VERSION ""

NS_ :

BS_:

BU_: ECS Dummy CGW MFC SPAS ESC BSD SCC SAS MDPS HUD CLU

BO_ 208 EMS_02_10ms: 32 CGW
 SG_ ENG_AccelPdlVal : 16|8@1+ (0.3906,0) [0|0] "%"  Dummy
 SG_ ENG_TqStndVal : 24|6@1+ (10,0) [0|0] "Nm"  Dummy
 SG_ ENG_BrkSwSta : 30|2@1+ (1,0) [0|0] ""  Dummy
 SG_ ENG_TransmsnTyp : 38|6@1+ (1,0) [0|0] ""  Dummy
 SG_ ENG_EngClntTempVal : 44|8@1+ (0.75,-48) [0|0] "℃"  Dummy
 SG_ ENG_AccActSta : 69|2@1+ (1,0) [0|0] ""  Dummy
 SG_ ENG_CltchOpSta : 71|2@1+ (1,0) [0|0] ""  Dummy
 SG_ ENG_EngTyp : 73|4@1+ (1,0) [0|0] ""  Dummy
 SG_ ENG_ThrPosVal : 79|8@1+ (0.469484,-15.0235) [0|0] "%"  Dummy
 SG_ ENG_EngDsplceTyp : 87|8@1+ (0.1,0) [0|0] "liter"  Dummy
 SG_ ENG_MinIndTqVal : 95|8@1+ (0.390625,0) [0|0] "%"  Dummy
 SG_ ENG_TrgtTqVal : 103|8@1+ (0.390625,0) [0|0] "%"  Dummy
 SG_ ENG_GlowLmpSta : 111|2@1+ (1,0) [0|0] ""  Dummy
 SG_ ACC_CrsMainSwLmpSta : 113|2@1+ (1,0) [0|0] ""  Dummy
 SG_ ACC_CrsSetSwLmpSta : 115|2@1+ (1,0) [0|0] ""  Dummy
 SG_ ENG_PreFuelCutInSta : 117|2@1+ (1,0) [0|0] ""  Dummy
 SG_ ENG_EngSta : 119|3@1+ (1,0) [0|0] ""  Dummy
 SG_ ENG_SoakTimeErrSta : 122|2@1+ (1,0) [0|0] ""  Dummy
 SG_ ENG_SoakTimeVal : 124|8@1+ (1,0) [0|0] "Min"  Dummy
 SG_ ENG_MaxIndTqVal : 132|8@1+ (0.390625,0) [0|0] "%"  Dummy
 SG_ ENG_SprkTimeVal : 140|8@1+ (0.375,-35.625) [0|0] "˚"  Dummy
 SG_ ENG_AppAccelPdlSta : 148|2@1+ (1,0) [0|0] ""  Dummy
 SG_ ENG_BstPrsrVal : 172|12@1+ (1.322,0) [0|0] "hPa"  Dummy
 SG_ ENG_EngOilTempVal : 184|8@1+ (0.75,-40) [0|0] "℃"  Dummy
 SG_ ENG_DpfWrngSta : 192|2@1+ (1,0) [0|0] ""  Dummy
 SG_ ENG_BattWrngLmpSta : 194|2@1+ (1,0) [0|0] ""  Dummy
 SG_ ENG_OilPrsrWrngLmpSta : 204|2@1+ (1,0) [0|0] ""  Dummy

BO_ 48 EMS_03_10ms: 32 CGW
 SG_ DCT_AccelPdlVal : 16|8@1+ (0.3906,0) [0|0] "%"  Dummy
 SG_ DCT_EngSpdErrSta : 30|2@1+ (1,0) [0|0] ""  Dummy
 SG_ DCT_EngSpdVal : 34|16@1+ (0.25,0) [0|0] "rpm"  Dummy
 SG_ DCT_CrctEngTqVal : 50|8@1+ (0.390625,0) [0|0] "%"  Dummy

BO_ 538 EMS_04_100ms: 32 CGW
 SG_ BAT_SocVal : 32|8@1+ (1,0) [0|0] "%"  Dummy

BO_ 528 EMS_05_100ms: 32 CGW
 SG_ ENG_ImmoLmpSta : 16|2@1+ (1,0) [0|0] ""  Dummy
 SG_ ENG_MilSta : 18|2@1+ (1,0) [0|0] ""  Dummy
 SG_ ENG_AtmsphPrsrVal : 22|5@1+ (10.7316,458.98) [0|0] "mmHg"  Dummy
 SG_ ENG_BattVoltVal : 35|8@1+ (0.101563,0) [0|0] "V"  Dummy
 SG_ SCC_SafetyFunctSta : 65|2@1+ (1,0) [0|0] ""  Dummy
 SG_ SCC_InAirTempVal : 67|8@1+ (0.75,-48) [0|0] "℃"  Dummy
 SG_ SCR_LvlWrngLmpSta : 116|2@1+ (1,0) [0|0] ""  Dummy
 SG_ SCR_LvlWrngMsgDis : 118|3@1+ (1,0) [0|0] ""  Dummy
 SG_ SCR_SysErrMsgDis : 121|3@1+ (1,0) [0|0] ""  Dummy
 SG_ SCR_IndcmtExitStaDis : 126|2@1+ (1,0) [0|0] ""  Dummy
 SG_ SCR_UreaLvlSta : 128|8@1+ (0.5,0) [0|0] "%"  Dummy
 SG_ SCR_RmnRstrtDis : 136|8@1+ (1,0) [0|0] ""  Dummy
 SG_ SCR_RmnDstDis : 144|16@1+ (1,0) [0|0] "km"  Dummy

BO_ 581 EMS_06_100ms: 32 CGW
 SG_ OBD_EngRpmVal : 32|16@1+ (0.25,0) [0|0] "rpm"  Dummy

BO_ 64 TCU_01_10ms: 32 CGW
 SG_ TCU_Crc1Val : 0|16@1+ (1,0) [0|65535] ""  CLU,Dummy
 SG_ TCU_AlvCnt1Val : 16|8@1+ (1,0) [0|255] ""  CLU,Dummy
 SG_ TCU_GearSlctDis : 24|4@1+ (1,0) [0|0] ""  Dummy
 SG_ TCU_TqRdctnPcVal : 32|16@1+ (0.390625,0) [0|0] "%"  Dummy
 SG_ TCU_GearStepTyp : 48|4@1+ (1,0) [0|0] ""  Dummy
 SG_ TCU_GearShftSta : 52|2@1+ (1,0) [0|0] ""  Dummy
 SG_ TCU_TqCnvrtrSta : 54|2@1+ (1,0) [0|0] ""  Dummy
 SG_ TCU_CurrGearSta : 56|4@1+ (1,0) [0|0] ""  Dummy
 SG_ TCU_TrgtGearSta : 60|4@1+ (1,0) [0|0] ""  Dummy
 SG_ TCU_CluTrgtGearSta : 64|4@1+ (1,0) [0|0] ""  Dummy
 SG_ TCH_EngTrgtGearSta : 68|4@1+ (1,0) [0|0] ""  Dummy
 SG_ TCU_VehSpdKphVal : 88|8@1+ (1,0) [0|0] "km/h"  Dummy
 SG_ TCU_DcmlVehSpdKphVal : 96|8@1+ (0.0078125,0) [0|0] "km/h"  Dummy
 SG_ TCU_EngRpmDis : 112|16@1+ (0.25,0) [0|0] "rpm"  Dummy
 SG_ TCU_EngRpmDisSta : 128|2@1+ (1,0) [0|3] ""  CLU,Dummy
 SG_ TCU_GearLmpBlnkngReq : 130|2@1+ (1,0) [0|0] ""  Dummy
 SG_ TCU_FuelCutInhbtReq : 132|2@1+ (1,0) [0|0] ""  Dummy
 SG_ TCU_SprtyIndxSta : 147|5@1+ (1,0) [0|0] ""  Dummy
 SG_ TCU_DrvngModDis : 152|3@1+ (1,0) [0|0] ""  Dummy
 SG_ TCU_SmrtShftSta : 158|2@1+ (1,0) [0|0] ""  Dummy
 SG_ TCU_NetrlCtrlSta : 184|2@1+ (1,0) [0|0] ""  Dummy
 SG_ TCU_ShftPtrnSta : 186|4@1+ (1,0) [0|0] ""  Dummy
 SG_ TCU_VgisInhbtReq : 190|2@1+ (1,0) [0|0] ""  Dummy

BO_ 106 TCU_02_10ms: 32 CGW
 SG_ TCU_Crc2Val : 0|12@1+ (1,0) [0|0] ""  Dummy
 SG_ TCU_AlvCnt2Val : 12|4@1+ (1,0) [0|0] ""  Dummy
 SG_ TCU_AtTempCVal : 32|8@1+ (1,-40) [0|0] "℃"  Dummy
 SG_ TCU_TqCnvrtrSpdVal : 40|16@1+ (0.25,0) [0|0] "rpm"  Dummy
 SG_ TCU_ActvEcoRdySta : 60|2@1+ (1,0) [0|0] ""  Dummy

BO_ 624 TCU_03_100ms: 32 CGW
 SG_ TCU_Crc3Val : 0|12@1+ (1,0) [0|0] ""  Dummy
 SG_ TCU_AlvCnt3Val : 12|4@1+ (1,0) [0|0] ""  Dummy
 SG_ TCU_WrngMsgSta : 16|8@1+ (1,0) [0|0] ""  Dummy
 SG_ TCU_VehStpTimeDis : 24|5@1+ (1,0) [0|0] ""  Dummy

BO_ 261 CCU_01_20ms: 32 CGW
 SG_ CCU_Crc1Val : 0|12@1+ (1,0) [0|0] ""  Dummy
 SG_ CCU_SrvLmpReq : 70|2@1+ (1,0) [0|0] ""  Dummy

BO_ 768 CCU_03_200ms: 32 CGW
 SG_ CCU_OutTempCDis : 80|8@1+ (0.5,-41) [0|0] "℃"  Dummy
 SG_ CCU_OutTempDis : 88|8@1+ (0.5,-40) [0|0] "℃"  Dummy
 SG_ CCU_OutTempSnsrVal : 96|8@1+ (0.5,-40) [0|0] "℃"  Dummy
 SG_ CCU_TempDispUnitSta : 112|2@1+ (1,0) [0|0] ""  Dummy

BO_ 442 ACU_01_100ms: 32 CGW
 SG_ ACU_SysWrngLmpDis : 16|3@1+ (1,0) [0|0] ""  Dummy
 SG_ ACU_TlltlLmpDis : 19|3@1+ (1,0) [0|0] ""  Dummy
 SG_ ACU_SdArbgExtTyp : 59|3@1+ (1,0) [0|0] ""  Dummy

BO_ 1050 ODS_01_1000ms: 32 CGW
 SG_ ODS_OccClassSta : 24|8@1+ (1,0) [0|0] ""  Dummy

BO_ 810 IBU_02_200ms: 32 CGW
 SG_ BCM_WrngBzrSta : 80|3@1+ (1,0) [0|0] ""  Dummy

BO_ 1168 BCM_01_00ms: 32 CGW
 SG_ BCM_RmtKeyReq : 19|3@1+ (1,0) [0|0] ""  Dummy

BO_ 864 BCM_02_200ms: 32 CGW
 SG_ BAlarm_BglrAlrmSta : 20|2@1+ (1,0) [0|0] ""  Dummy
 SG_ BCM_AccInSta : 26|2@1+ (1,0) [0|0] ""  Dummy
 SG_ BCM_CntryConfgTyp : 34|3@1+ (1,0) [0|0] ""  Dummy
 SG_ BCM_DrvOptTyp : 40|2@1+ (1,0) [0|0] ""  Dummy
 SG_ BCM_Ign1Sta : 48|2@1+ (1,0) [0|0] ""  Dummy
 SG_ BCM_Ign2Sta : 50|2@1+ (1,0) [0|0] ""  Dummy
 SG_ BCM_KeyOnSta : 52|3@1+ (1,0) [0|0] ""  Dummy
 SG_ BCM_MtGearPosRSta : 56|2@1+ (1,0) [0|0] ""  Dummy
 SG_ BCM_SmkOptTyp : 58|2@1+ (1,0) [0|0] ""  Dummy
 SG_ BCM_WrngSta : 80|3@1+ (1,0) [0|0] ""  Dummy
 SG_ HeatedSteerWheel_AutoOffSta : 83|2@1+ (1,0) [0|0] ""  Dummy
 SG_ PHEV_FastChrgDrSwSta : 88|2@1+ (1,0) [0|0] ""  Dummy
 SG_ PHEV_StndChrgDrOpnSwReq : 90|2@1+ (1,0) [0|0] ""  Dummy
 SG_ PHEV_RrChrgDrSwSta : 92|2@1+ (1,0) [0|0] ""  Dummy
 SG_ Warn_SunRoofOpnSta : 98|2@1+ (1,0) [0|0] ""  Dummy
 SG_ Wiper_RainSnsrOptionTyp : 102|2@1+ (1,0) [0|0] ""  Dummy
 SG_ Wiper_RainSnsrSta : 104|3@1+ (1,0) [0|0] ""  Dummy
 SG_ PHEV_FuelDrDis : 112|3@1+ (1,0) [0|0] ""  Dummy
 SG_ Wiper_RrWiperSwSta : 138|2@1+ (1,0) [0|0] ""  Dummy
 SG_ Wiper_SwSta : 140|2@1+ (1,0) [0|0] ""  Dummy

BO_ 869 BCM_03_200ms: 32 CGW
 SG_ Lamp_AvTailLmpSta : 26|2@1+ (1,0) [0|0] ""  Dummy
 SG_ Lamp_AutoLtSnsrHorVal : 54|10@1+ (1,0) [0|0] ""  Dummy
 SG_ Lamp_AutoLtSnsrNightSta : 64|2@1+ (1,0) [0|0] ""  Dummy
 SG_ Lamp_AutoLtSwReq : 80|2@1+ (1,0) [0|0] ""  Dummy
 SG_ Lamp_ExtrnlTailLmpOnReq : 90|2@1+ (1,0) [0|0] ""  Dummy
 SG_ Lamp_HbaCtrlModTyp : 94|2@1+ (1,0) [0|0] ""  Dummy
 SG_ Lamp_HdLmpHiOnReq : 96|2@1+ (1,0) [0|0] ""  Dummy
 SG_ Lamp_HdLmpLoOnReq : 98|2@1+ (1,0) [0|0] ""  Dummy
 SG_ Lamp_IntTailLmpOnReq : 104|2@1+ (1,0) [0|0] ""  Dummy
 SG_ Lamp_PassingLmpOnReq : 109|2@1+ (1,0) [0|0] ""  Dummy
 SG_ Lamp_UsaDrlSwSta : 124|2@1+ (1,0) [0|0] ""  Dummy

BO_ 906 BCM_04_200ms: 32 CGW
 SG_ USM_ArmBzrSta : 18|3@1+ (1,0) [0|0] ""  Dummy
 SG_ USM_AutoDrLkReq : 21|3@1+ (1,0) [0|0] ""  Dummy
 SG_ USM_AutoDrUnLkReq : 24|3@1+ (1,0) [0|0] ""  Dummy
 SG_ USM_EscrtHdLmpSta : 27|3@1+ (1,0) [0|0] ""  Dummy
 SG_ USM_LkSndOptSta : 32|3@1+ (1,0) [0|0] ""  Dummy
 SG_ USM_TwoTrnUnLkCurrentSta : 36|2@1+ (1,0) [0|0] ""  Dummy
 SG_ Mirror_FldReq : 42|2@1+ (1,0) [0|0] ""  Dummy
 SG_ PAS_DstLvlSta : 44|2@1+ (1,0) [0|0] ""  Dummy
 SG_ PAS_FrCtrWrngLvlDis : 48|3@1+ (1,0) [0|0] ""  Dummy
 SG_ PAS_FrLftWrngLvlDis : 53|3@1+ (1,0) [0|0] ""  Dummy
 SG_ PAS_FrRtWrngLvlDis : 58|3@1+ (1,0) [0|0] ""  Dummy
 SG_ PAS_FrSnsrWrngLvlSta : 64|3@1+ (1,0) [0|0] ""  Dummy
 SG_ PAS_OptTyp : 67|2@1+ (1,0) [0|0] ""  Dummy
 SG_ PAS_RrCtrWrngLvlDis : 69|3@1+ (1,0) [0|0] ""  Dummy
 SG_ PAS_RrLftWrngLvlDis : 74|3@1+ (1,0) [0|0] ""  Dummy
 SG_ PAS_RrRtWrngLvlDis : 80|3@1+ (1,0) [0|0] ""  Dummy
 SG_ PAS_RrSnsrWrngLvlSta : 85|3@1+ (1,0) [0|0] ""  Dummy
 SG_ PAS_SysChkSndSta : 88|3@1+ (1,0) [0|0] ""  Dummy
 SG_ PAS_SysOnSta : 91|3@1+ (1,0) [0|0] ""  Dummy
 SG_ SBR_AsstStBltWrngIndSta : 94|2@1+ (1,0) [0|0] ""  Dummy
 SG_ SBR_DrvStBltIndSta : 96|2@1+ (1,0) [0|0] ""  Dummy
 SG_ SBR_RrCtrStBltIndSta : 98|2@1+ (1,0) [0|0] ""  Dummy
 SG_ SBR_RrLftStBltWrngIndSta : 100|2@1+ (1,0) [0|0] ""  Dummy
 SG_ SBR_RrRtStBltWrngIndSta : 102|2@1+ (1,0) [0|0] ""  Dummy
 SG_ SBR_StBltWrngBzrSta : 104|2@1+ (1,0) [0|0] ""  Dummy
 SG_ USM_WrngSndLvlSta : 106|3@1+ (1,0) [0|0] ""  Dummy
 SG_ Wiper_PrkngPosSta : 120|2@1+ (1,0) [0|0] ""  Dummy

BO_ 21 SMK_01_00ms: 32 CGW
 SG_ DoorLock_PsvDrUnLkReq : 20|2@1+ (1,0) [0|0] ""  Dummy
 SG_ SMK_RmtKeyReq : 48|4@1+ (1,0) [0|0] ""  Dummy

BO_ 837 SMK_02_200ms: 32 CGW
 SG_ SMK_CltchIgnLkSwSta : 26|2@1+ (1,0) [0|0] ""  Dummy
 SG_ SMK_DeActvWrngSta : 28|2@1+ (1,0) [0|0] ""  Dummy
 SG_ USM_HfreeOperModSta : 48|3@1+ (1,0) [0|0] ""  Dummy
 SG_ USM_WlcmLtSta : 51|2@1+ (1,0) [0|0] ""  Dummy

BO_ 848 SMK_03_200ms: 32 CGW
 SG_ SMK_StrtStpBtnWrngSta : 40|2@1+ (1,0) [0|0] ""  Dummy

BO_ 858 SMK_04_200ms: 32 CGW
 SG_ Warn_DisWrngSta : 18|4@1+ (1,0) [0|0] ""  Dummy
 SG_ Warn_IdOutWrngSta : 29|2@1+ (1,0) [0|0] ""  Dummy
 SG_ Warn_KeyBattLoWrngSta : 32|2@1+ (1,0) [0|0] ""  Dummy
 SG_ Warn_NotGearPosPWrngSta : 36|2@1+ (1,0) [0|0] ""  Dummy
 SG_ Warn_EsclFlWrngSta : 64|2@1+ (1,0) [0|0] ""  Dummy
 SG_ Warn_EsclNotLkWrngSta : 66|2@1+ (1,0) [0|0] ""  Dummy
 SG_ Warn_EsclNotUnLkWrngSta : 68|2@1+ (1,0) [0|0] ""  Dummy
 SG_ Warn_ImmoLmpOnReq : 70|2@1+ (1,0) [0|0] ""  Dummy

BO_ 800 TPMS_01_200ms: 32 CGW
 SG_ TPMS_FLPosWrngLmpSta : 16|2@1+ (1,0) [0|0] ""  Dummy
 SG_ TPMS_FRPosWrngLmpSta : 18|2@1+ (1,0) [0|0] ""  Dummy
 SG_ TPMS_RLPosWrngLmpSta : 20|2@1+ (1,0) [0|0] ""  Dummy
 SG_ TPMS_RRPosWrngLmpSta : 22|2@1+ (1,0) [0|0] ""  Dummy
 SG_ TPMS_FLTirePrsrVal : 24|8@1+ (1,0) [0|0] "PSI"  Dummy
 SG_ TPMS_FRTirePrsrVal : 32|8@1+ (1,0) [0|0] "PSI"  Dummy
 SG_ TPMS_RLTirePrsrVal : 40|8@1+ (1,0) [0|0] "PSI"  Dummy
 SG_ TPMS_RRTirePrsrVal : 48|8@1+ (1,0) [0|0] "PSI"  Dummy
 SG_ TPMS_SnsrSta : 56|3@1+ (1,0) [0|0] ""  Dummy
 SG_ TPMS_WrngLmpSta : 64|2@1+ (1,0) [0|0] ""  Dummy
 SG_ TPMS_TreadWrngLmpSta : 66|2@1+ (1,0) [0|0] ""  Dummy
 SG_ TPMS_PrsrUnitSta : 68|2@1+ (1,0) [0|0] ""  Dummy

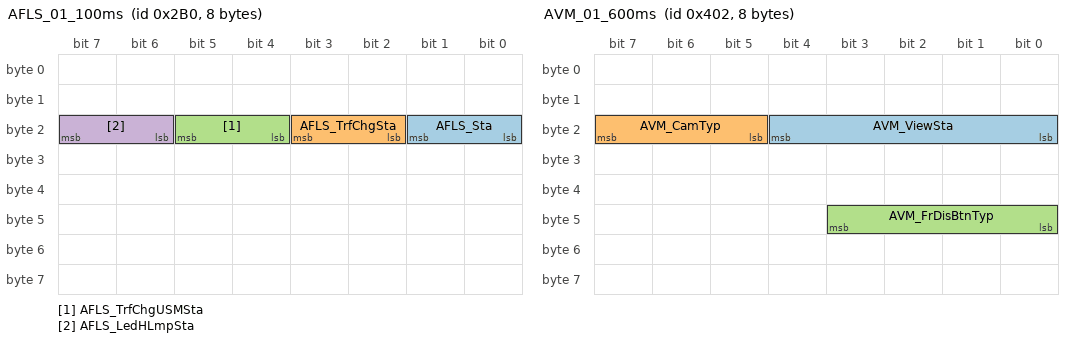
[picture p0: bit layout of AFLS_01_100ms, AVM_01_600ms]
BO_ 688 AFLS_01_100ms: 8 CGW
 SG_ AFLS_Sta : 16|2@1+ (1,0) [0|0] ""  Dummy
 SG_ AFLS_TrfChgSta : 18|2@1+ (1,0) [0|0] ""  Dummy
 SG_ AFLS_TrfChgUSMSta : 20|2@1+ (1,0) [0|0] ""  Dummy
 SG_ AFLS_LedHLmpSta : 22|2@1+ (1,0) [0|0] ""  Dummy

BO_ 1024 AHLS_01_300ms: 8 CGW
 SG_ AHLS_WrnLmpDis : 0|2@1+ (1,0) [0|0] ""  Dummy
 SG_ AHLS_WrnMsgDis : 2|2@1+ (1,0) [0|0] ""  Dummy

BO_ 1026 AVM_01_600ms: 8 CGW
 SG_ AVM_ViewSta : 16|5@1+ (1,0) [0|0] ""  Dummy
 SG_ AVM_CamTyp : 21|3@1+ (1,0) [0|0] ""  Dummy
 SG_ AVM_FrDisBtnTyp : 40|4@1+ (1,0) [0|0] ""  Dummy

BO_ 807 PSB_01_200ms: 8 CGW
 SG_ PSB_LHFlrSta : 16|2@1+ (1,0) [0|0] ""  Dummy
 SG_ PSB_RHFlrSta : 24|2@1+ (1,0) [0|0] ""  Dummy

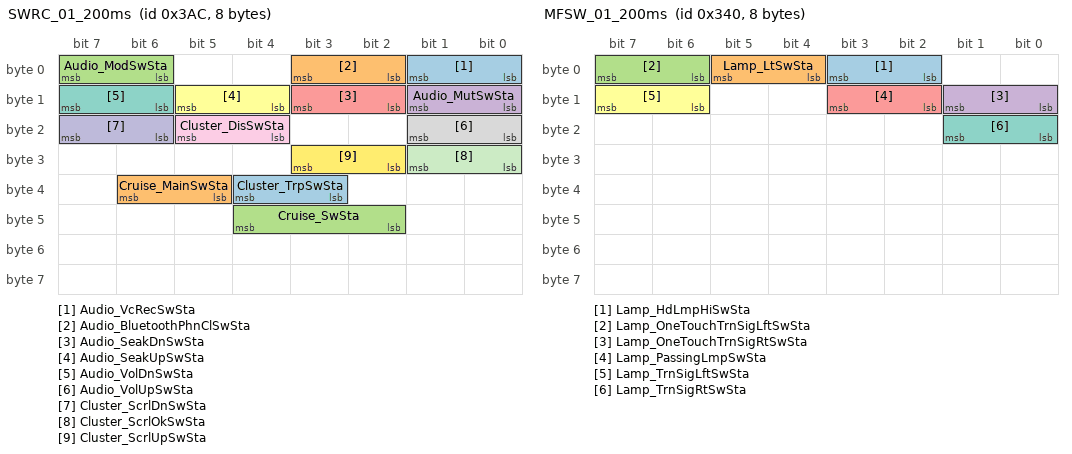
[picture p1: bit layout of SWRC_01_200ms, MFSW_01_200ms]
BO_ 940 SWRC_01_200ms: 8 CGW
 SG_ Audio_VcRecSwSta : 0|2@1+ (1,0) [0|0] ""  Dummy
 SG_ Audio_BluetoothPhnClSwSta : 2|2@1+ (1,0) [0|0] ""  Dummy
 SG_ Audio_ModSwSta : 6|2@1+ (1,0) [0|0] ""  Dummy
 SG_ Audio_MutSwSta : 8|2@1+ (1,0) [0|0] ""  Dummy
 SG_ Audio_SeakDnSwSta : 10|2@1+ (1,0) [0|0] ""  Dummy
 SG_ Audio_SeakUpSwSta : 12|2@1+ (1,0) [0|0] ""  Dummy
 SG_ Audio_VolDnSwSta : 14|2@1+ (1,0) [0|0] ""  Dummy
 SG_ Audio_VolUpSwSta : 16|2@1+ (1,0) [0|0] ""  Dummy
 SG_ Cluster_DisSwSta : 20|2@1+ (1,0) [0|0] ""  Dummy
 SG_ Cluster_ScrlDnSwSta : 22|2@1+ (1,0) [0|0] ""  Dummy
 SG_ Cluster_ScrlOkSwSta : 24|2@1+ (1,0) [0|0] ""  Dummy
 SG_ Cluster_ScrlUpSwSta : 26|2@1+ (1,0) [0|0] ""  Dummy
 SG_ Cluster_TrpSwSta : 35|2@1+ (1,0) [0|0] ""  Dummy
 SG_ Cruise_MainSwSta : 37|2@1+ (1,0) [0|0] ""  Dummy
 SG_ Cruise_SwSta : 42|3@1+ (1,0) [0|0] ""  Dummy

BO_ 832 MFSW_01_200ms: 8 CGW
 SG_ Lamp_HdLmpHiSwSta : 2|2@1+ (1,0) [0|0] ""  Dummy
 SG_ Lamp_LtSwSta : 4|2@1+ (1,0) [0|0] ""  Dummy
 SG_ Lamp_OneTouchTrnSigLftSwSta : 6|2@1+ (1,0) [0|0] ""  Dummy
 SG_ Lamp_OneTouchTrnSigRtSwSta : 8|2@1+ (1,0) [0|0] ""  Dummy
 SG_ Lamp_PassingLmpSwSta : 10|2@1+ (1,0) [0|0] ""  Dummy
 SG_ Lamp_TrnSigLftSwSta : 14|2@1+ (1,0) [0|0] ""  Dummy
 SG_ Lamp_TrnSigRtSwSta : 16|2@1+ (1,0) [0|0] ""  Dummy

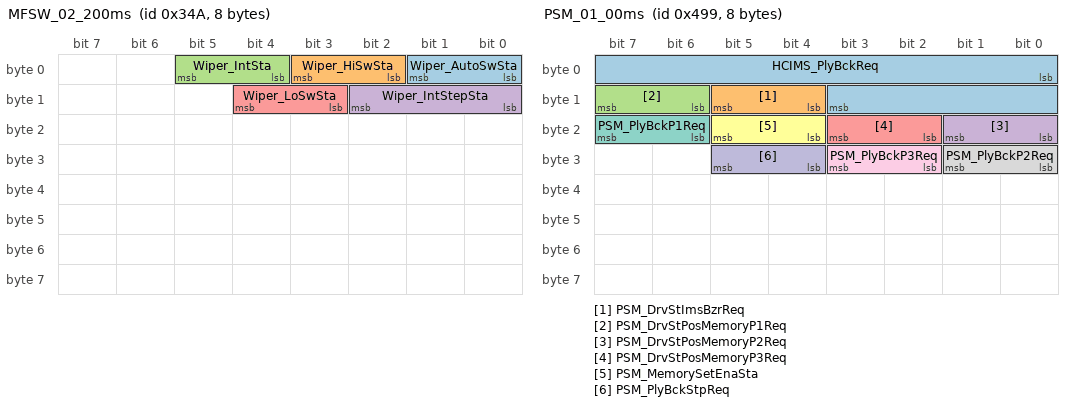
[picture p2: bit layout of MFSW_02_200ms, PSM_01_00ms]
BO_ 842 MFSW_02_200ms: 8 CGW
 SG_ Wiper_AutoSwSta : 0|2@1+ (1,0) [0|0] ""  Dummy
 SG_ Wiper_HiSwSta : 2|2@1+ (1,0) [0|0] ""  Dummy
 SG_ Wiper_IntSta : 4|2@1+ (1,0) [0|0] ""  Dummy
 SG_ Wiper_IntStepSta : 8|3@1+ (1,0) [0|0] ""  Dummy
 SG_ Wiper_LoSwSta : 11|2@1+ (1,0) [0|0] ""  Dummy

BO_ 922 SCM_01_200ms: 8 CGW
 SG_ HWSW_SysSta : 0|2@1+ (1,0) [0|0] ""  Dummy
 SG_ USM_CmdSta : 16|2@1+ (1,0) [0|0] ""  Dummy

BO_ 1177 PSM_01_00ms: 8 CGW
 SG_ HCIMS_PlyBckReq : 0|12@1+ (1,0) [0|0] ""  Dummy
 SG_ PSM_DrvStImsBzrReq : 12|2@1+ (1,0) [0|0] ""  Dummy
 SG_ PSM_DrvStPosMemoryP1Req : 14|2@1+ (1,0) [0|0] ""  Dummy
 SG_ PSM_DrvStPosMemoryP2Req : 16|2@1+ (1,0) [0|0] ""  Dummy
 SG_ PSM_DrvStPosMemoryP3Req : 18|2@1+ (1,0) [0|0] ""  Dummy
 SG_ PSM_MemorySetEnaSta : 20|2@1+ (1,0) [0|0] ""  Dummy
 SG_ PSM_PlyBckP1Req : 22|2@1+ (1,0) [0|0] ""  Dummy
 SG_ PSM_PlyBckP2Req : 24|2@1+ (1,0) [0|0] ""  Dummy
 SG_ PSM_PlyBckP3Req : 26|2@1+ (1,0) [0|0] ""  Dummy
 SG_ PSM_PlyBckStpReq : 28|2@1+ (1,0) [0|0] ""  Dummy

BO_ 794 PSM_04_200ms: 8 CGW
 SG_ USM_MvVal : 20|3@1+ (1,0) [0|0] ""  Dummy

BO_ 926 WPC_01_200ms: 8 CGW
 SG_ USM_CmdWPCSta : 0|2@1+ (1,0) [0|0] ""  Dummy
 SG_ WPC_PhnLftWrngSta : 2|3@1+ (1,0) [0|0] ""  Dummy

BO_ 938 HSWS_01_200ms: 8 CGW
 SG_ HSWS_SysWrngSta : 0|2@1+ (1,0) [0|0] ""  Dummy

BO_ 1159 DDM_01_00ms: 8 CGW
 SG_ Mirror_AsstOSMirFldSta : 6|2@1+ (1,0) [0|0] ""  Dummy

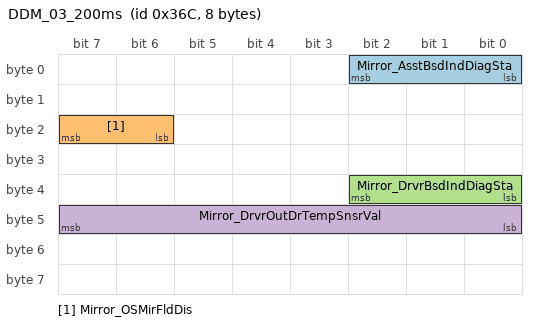
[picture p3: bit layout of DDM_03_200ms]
BO_ 876 DDM_03_200ms: 8 CGW
 SG_ Mirror_AsstBsdIndDiagSta : 0|3@1+ (1,0) [0|0] ""  Dummy
 SG_ Mirror_OSMirFldDis : 22|2@1+ (1,0) [0|0] ""  Dummy
 SG_ Mirror_DrvrBsdIndDiagSta : 32|3@1+ (1,0) [0|0] ""  Dummy
 SG_ Mirror_DrvrOutDrTempSnsrVal : 40|8@1+ (1,0) [0|0] ""  Dummy

BO_ 904 DDM_04_200ms: 8 CGW
 SG_ IMS_DrvrStPosLimSta : 10|2@1+ (1,0) [0|0] ""  Dummy

BA_DEF_ BO_  "NmAsrMessage" ENUM  "No","Yes";
BA_DEF_ BO_  "GenMsgCycleTime" INT 0 2000;
BA_DEF_ BO_  "GenMsgSendType" ENUM  "Cyclic","NoMsgSendType";
BA_DEF_ BO_  "GenMsgCycleTimeFast" INT 0 500;
BA_DEF_ BO_  "GenMsgDelayTime" INT 0 20;
BA_DEF_ BO_  "GenMsgILSupport" ENUM  "No","Yes";
BA_DEF_ BO_  "GenMsgNrOfRepetition" INT 0 3;
BA_DEF_ BO_  "VFrameFormat" ENUM  "StandardCAN","ExtendedCAN","reserved","reserved","reserved","reserved","reserved","reserved","reserved","reserved","reserved","reserved","reserved","reserved","StandardCAN_FD","ExtendedCAN_FD";
BA_DEF_ SG_  "SignalLongName" STRING ;
BA_DEF_ SG_  "UserSigValidity" ENUM  "B+","ACC","IG","IG1","IG2","IG3","IG1 or IG2","IG1 or IG3","Undef";
BA_DEF_ SG_  "GenSigTimeoutTime" INT 0 7000;
BA_DEF_ SG_  "UsrSigTimeoutValue" STRING ;
BA_DEF_ SG_  "UsrSigPurpose" ENUM  "Undef","FN","DIAG","DEV","NM";
BA_DEF_ SG_  "GenSigStartValue" INT 0 1215752192;
BA_DEF_ SG_  "NetworkRequest" ENUM  "Yes","No";
BA_DEF_ SG_  "NetworkRequestHoldingTime" INT 0 65535;
BA_DEF_ SG_  "Description" STRING ;
BA_DEF_ SG_  "Version" STRING ;
BA_DEF_ SG_  "GenSigEnvVarType" ENUM  "Int","Float","Undef";
BA_DEF_ SG_  "GenSigSendType" ENUM  "OnChangeWithRepetition","OnWriteWithRepetition","NoSigSendType";
BA_DEF_ SG_  "GwSigLatencyTime" INT 0 65536;
BA_DEF_ SG_  "GwSigMissingSourceType" ENUM  "Undef","OldValue","DefaultValue","InitialValue";
BA_DEF_ SG_  "RoutingFactor" INT 1 1215752192;
BA_DEF_ SG_  "RoutingFactorMM" INT 1 1215752192;
BA_DEF_DEF_  "NmAsrMessage" "No";
BA_DEF_DEF_  "GenMsgCycleTime" 200;
BA_DEF_DEF_  "GenMsgSendType" "NoMsgSendType";
BA_DEF_DEF_  "GenMsgCycleTimeFast" 40;
BA_DEF_DEF_  "GenMsgDelayTime" 20;
BA_DEF_DEF_  "GenMsgILSupport" "Yes";
BA_DEF_DEF_  "GenMsgNrOfRepetition" 3;
BA_DEF_DEF_  "VFrameFormat" "StandardCAN";
BA_DEF_DEF_  "SignalLongName" "";
BA_DEF_DEF_  "UserSigValidity" "IG";
BA_DEF_DEF_  "GenSigTimeoutTime" 500;
BA_DEF_DEF_  "UsrSigTimeoutValue" "Undef";
BA_DEF_DEF_  "UsrSigPurpose" "FN";
BA_DEF_DEF_  "GenSigStartValue" 0;
BA_DEF_DEF_  "NetworkRequest" "No";
BA_DEF_DEF_  "NetworkRequestHoldingTime" 5.03070881554866E-316;
BA_DEF_DEF_  "Description" "";
BA_DEF_DEF_  "Version" "";
BA_DEF_DEF_  "GenSigEnvVarType" "Undef";
BA_DEF_DEF_  "GenSigSendType" "NoSigSendType";
BA_DEF_DEF_  "GwSigLatencyTime" 40;
BA_DEF_DEF_  "GwSigMissingSourceType" "Undef";
BA_DEF_DEF_  "RoutingFactor" 1;
BA_DEF_DEF_  "RoutingFactorMM" 1;
BA_ "GenMsgSendType" BO_ 208 0;
BA_ "GenMsgCycleTime" BO_ 208 10;
BA_ "VFrameFormat" BO_ 208 14;
BA_ "GenMsgSendType" BO_ 48 0;
BA_ "GenMsgCycleTime" BO_ 48 10;
BA_ "VFrameFormat" BO_ 48 14;
BA_ "GenMsgSendType" BO_ 538 0;
BA_ "GenMsgCycleTime" BO_ 538 100;
BA_ "VFrameFormat" BO_ 538 14;
BA_ "GenMsgSendType" BO_ 528 0;
BA_ "GenMsgCycleTime" BO_ 528 100;
BA_ "VFrameFormat" BO_ 528 14;
BA_ "GenMsgSendType" BO_ 581 0;
BA_ "GenMsgCycleTime" BO_ 581 100;
BA_ "VFrameFormat" BO_ 581 14;
BA_ "GenMsgSendType" BO_ 64 0;
BA_ "GenMsgCycleTime" BO_ 64 10;
BA_ "VFrameFormat" BO_ 64 14;
BA_ "GenMsgSendType" BO_ 106 0;
BA_ "GenMsgCycleTime" BO_ 106 10;
BA_ "VFrameFormat" BO_ 106 14;
BA_ "GenMsgSendType" BO_ 624 0;
BA_ "GenMsgCycleTime" BO_ 624 100;
BA_ "VFrameFormat" BO_ 624 14;
BA_ "GenMsgSendType" BO_ 261 0;
BA_ "GenMsgCycleTime" BO_ 261 20;
BA_ "VFrameFormat" BO_ 261 14;
BA_ "GenMsgSendType" BO_ 768 0;
BA_ "VFrameFormat" BO_ 768 14;
BA_ "GenMsgSendType" BO_ 442 0;
BA_ "GenMsgCycleTime" BO_ 442 100;
BA_ "VFrameFormat" BO_ 442 14;
BA_ "GenMsgSendType" BO_ 1050 0;
BA_ "GenMsgCycleTime" BO_ 1050 1000;
BA_ "VFrameFormat" BO_ 1050 14;
BA_ "GenMsgSendType" BO_ 810 0;
BA_ "VFrameFormat" BO_ 810 14;
BA_ "GenMsgCycleTime" BO_ 1168 0;
BA_ "VFrameFormat" BO_ 1168 14;
BA_ "GenMsgSendType" BO_ 864 0;
BA_ "VFrameFormat" BO_ 864 14;
BA_ "GenMsgSendType" BO_ 869 0;
BA_ "VFrameFormat" BO_ 869 14;
BA_ "GenMsgSendType" BO_ 906 0;
BA_ "VFrameFormat" BO_ 906 14;
BA_ "GenMsgCycleTime" BO_ 21 0;
BA_ "VFrameFormat" BO_ 21 14;
BA_ "GenMsgSendType" BO_ 837 0;
BA_ "VFrameFormat" BO_ 837 14;
BA_ "GenMsgSendType" BO_ 848 0;
BA_ "VFrameFormat" BO_ 848 14;
BA_ "GenMsgSendType" BO_ 858 0;
BA_ "VFrameFormat" BO_ 858 14;
BA_ "GenMsgSendType" BO_ 800 0;
BA_ "VFrameFormat" BO_ 800 14;
BA_ "GenMsgSendType" BO_ 688 0;
BA_ "GenMsgCycleTime" BO_ 688 100;
BA_ "VFrameFormat" BO_ 688 14;
BA_ "GenMsgSendType" BO_ 1024 0;
BA_ "GenMsgCycleTime" BO_ 1024 300;
BA_ "VFrameFormat" BO_ 1024 14;
BA_ "GenMsgSendType" BO_ 1026 0;
BA_ "GenMsgCycleTime" BO_ 1026 600;
BA_ "VFrameFormat" BO_ 1026 14;
BA_ "GenMsgSendType" BO_ 807 0;
BA_ "VFrameFormat" BO_ 807 14;
BA_ "GenMsgSendType" BO_ 940 0;
BA_ "VFrameFormat" BO_ 940 14;
BA_ "GenMsgSendType" BO_ 832 0;
BA_ "VFrameFormat" BO_ 832 14;
BA_ "GenMsgSendType" BO_ 842 0;
BA_ "VFrameFormat" BO_ 842 14;
BA_ "GenMsgSendType" BO_ 922 0;
BA_ "VFrameFormat" BO_ 922 14;
BA_ "GenMsgCycleTime" BO_ 1177 0;
BA_ "VFrameFormat" BO_ 1177 14;
BA_ "GenMsgSendType" BO_ 794 0;
BA_ "VFrameFormat" BO_ 794 14;
BA_ "GenMsgSendType" BO_ 926 0;
BA_ "VFrameFormat" BO_ 926 14;
BA_ "GenMsgSendType" BO_ 938 0;
BA_ "VFrameFormat" BO_ 938 14;
BA_ "GenMsgCycleTime" BO_ 1159 0;
BA_ "VFrameFormat" BO_ 1159 14;
BA_ "GenMsgSendType" BO_ 876 0;
BA_ "VFrameFormat" BO_ 876 14;
BA_ "GenMsgSendType" BO_ 904 0;
BA_ "VFrameFormat" BO_ 904 14;
BA_ "Version" SG_ 208 ENG_AccelPdlVal "1.0";
BA_ "Description" SG_ 208 ENG_AccelPdlVal "The signal PV_AV_CAN is a measure of the Accelerator Pedal value.

The accelerator pedal value is determined via 2 pedal sensors, which are connected mechanically to the

accelerator pedal. If the EMS-ECU recognizes that the accelerator pedal is not acti";
BA_ "UsrSigTimeoutValue" SG_ 208 ENG_AccelPdlVal "";
BA_ "UserSigValidity" SG_ 208 ENG_AccelPdlVal 3;
BA_ "SignalLongName" SG_ 208 ENG_AccelPdlVal "ENG_AcceleratorPedalValue";
BA_ "Version" SG_ 208 ENG_TqStndVal "1.0";
BA_ "Description" SG_ 208 ENG_TqStndVal "The value TQ_STND specifies the torque to which the other torque quantities are referred. The conversion into a physical quantity provides a displayable range of 0...99.6094% of TQ_STND for the appropriate

signals.

If MUL_CODE = 11B is transmitted, the";
BA_ "UsrSigTimeoutValue" SG_ 208 ENG_TqStndVal "";
BA_ "UserSigValidity" SG_ 208 ENG_TqStndVal 3;
BA_ "SignalLongName" SG_ 208 ENG_TqStndVal "ENG_TorqueStandardValue";
BA_ "Version" SG_ 208 ENG_BrkSwSta "1.0";
BA_ "Description" SG_ 208 ENG_BrkSwSta "This signal indicates that a brake switch is activated or not. When the brake switch is activated(pressed) its value is 02H otherwise its value is 01H.

If the EMS does not support this signal the value is 00H.";
BA_ "GenSigStartValue" SG_ 208 ENG_BrkSwSta 1;
BA_ "UsrSigTimeoutValue" SG_ 208 ENG_BrkSwSta "";
BA_ "UserSigValidity" SG_ 208 ENG_BrkSwSta 3;
BA_ "SignalLongName" SG_ 208 ENG_BrkSwSta "ENG_BrakeSwitchStatus";
BA_ "Version" SG_ 208 ENG_TransmsnTyp "1.0";
BA_ "Description" SG_ 208 ENG_TransmsnTyp "A/T or M/T information generated by automatic variant coding.

A/T information is got from the “TCU_TYPE” signal of TCU1 message. (See TCU1 message information)";
BA_ "UsrSigTimeoutValue" SG_ 208 ENG_TransmsnTyp "";
BA_ "UserSigValidity" SG_ 208 ENG_TransmsnTyp 3;
BA_ "SignalLongName" SG_ 208 ENG_TransmsnTyp "ENG_TransmissionType";
BA_ "Version" SG_ 208 ENG_EngClntTempVal "1.0";
BA_ "Description" SG_ 208 ENG_EngClntTempVal "Engine coolant temperature in EMS sensed via an A/D converter; converted into degrees centigrade (°C).";
BA_ "GenSigStartValue" SG_ 208 ENG_EngClntTempVal 255;
BA_ "UsrSigTimeoutValue" SG_ 208 ENG_EngClntTempVal "";
BA_ "UserSigValidity" SG_ 208 ENG_EngClntTempVal 3;
BA_ "SignalLongName" SG_ 208 ENG_EngClntTempVal "ENG_EngineCoolantTemperatureValue";
BA_ "Version" SG_ 208 ENG_AccActSta "1.0";
BA_ "Description" SG_ 208 ENG_AccActSta "EMS sends the state of the cruise control via the signal ACC_ACT. 

If the EMS does not support this signal the value is 00H



If the cruise control is activated then ACC_ACT = 1. In this period, vehicle speed control (cruise control) is performed by th";
BA_ "UsrSigTimeoutValue" SG_ 208 ENG_AccActSta "";
BA_ "UserSigValidity" SG_ 208 ENG_AccActSta 3;
BA_ "SignalLongName" SG_ 208 ENG_AccActSta "ENG_AutoCruiseControlActiveStatus";
BA_ "Version" SG_ 208 ENG_CltchOpSta "1.0";
BA_ "Description" SG_ 208 ENG_CltchOpSta "This signal indicates that ECU has detected an operation of a clutch. Using this signal an ISG (Idle Stop & Go) system acts as an alternator or a starter.



If the EMS does not support this signal the value is 00H";
BA_ "UsrSigTimeoutValue" SG_ 208 ENG_CltchOpSta "";
BA_ "UserSigValidity" SG_ 208 ENG_CltchOpSta 3;
BA_ "SignalLongName" SG_ 208 ENG_CltchOpSta "ENG_ClutchStatus";
BA_ "Version" SG_ 208 ENG_EngTyp "1.0";
BA_ "Description" SG_ 208 ENG_EngTyp "This signal indicates the characteristic of an engine system - which kind of fuel is used, whether the ETC (Electronic Throttle Contro) is applied or not.



When a normal engine system (gasoline fuel and no ETC) is used this value is 00H.";
BA_ "UsrSigTimeoutValue" SG_ 208 ENG_EngTyp "";
BA_ "UserSigValidity" SG_ 208 ENG_EngTyp 3;
BA_ "SignalLongName" SG_ 208 ENG_EngTyp "ENG_EngineType";
BA_ "Version" SG_ 208 ENG_ThrPosVal "1.0";
BA_ "Description" SG_ 208 ENG_ThrPosVal "The signal TPS is a measure of the throttle position.

The throttle position is determined via a potentiometer, which is connected mechanically to the throttle shaft. The voltage value, which is adjusted in the port via the voltage divider, is sensed in ";
BA_ "GenSigStartValue" SG_ 208 ENG_ThrPosVal 32;
BA_ "UsrSigTimeoutValue" SG_ 208 ENG_ThrPosVal "";
BA_ "UserSigValidity" SG_ 208 ENG_ThrPosVal 3;
BA_ "SignalLongName" SG_ 208 ENG_ThrPosVal "ENG_ThrottlePositionValue";
BA_ "Version" SG_ 208 ENG_EngDsplceTyp "1.0";
BA_ "Description" SG_ 208 ENG_EngDsplceTyp "This signal indicates the engine displacement (volume).";
BA_ "UsrSigTimeoutValue" SG_ 208 ENG_EngDsplceTyp "";
BA_ "UserSigValidity" SG_ 208 ENG_EngDsplceTyp 3;
BA_ "SignalLongName" SG_ 208 ENG_EngDsplceTyp "ENG_EngineDisplacementType";
BA_ "Version" SG_ 208 ENG_MinIndTqVal "1.0";
BA_ "Description" SG_ 208 ENG_MinIndTqVal "The signal TQI_MIN is the minimum engine torque (minimum air charging rate) which can be fired without misfire including compensation factors such as atmospheric pressure and temperature.

It is not enough to keep the engine running without external powe";
BA_ "UsrSigTimeoutValue" SG_ 208 ENG_MinIndTqVal "";
BA_ "UserSigValidity" SG_ 208 ENG_MinIndTqVal 3;
BA_ "SignalLongName" SG_ 208 ENG_MinIndTqVal "ENG_MinimumIndicatedTorqueValue";
BA_ "Version" SG_ 208 ENG_TrgtTqVal "1.0";
BA_ "Description" SG_ 208 ENG_TrgtTqVal "The signal TQI_TARGET is determined by an engine torque map with input which consists of  acceleration pedal value, MAF sensor, current RPM and etc. This signal reflects driver’s demand directly. 

But it does not depend on torque interventions realised";
BA_ "UsrSigTimeoutValue" SG_ 208 ENG_TrgtTqVal "";
BA_ "UserSigValidity" SG_ 208 ENG_TrgtTqVal 3;
BA_ "SignalLongName" SG_ 208 ENG_TrgtTqVal "ENG_TargetTorqueValue";
BA_ "Version" SG_ 208 ENG_GlowLmpSta "1.0";
BA_ "Description" SG_ 208 ENG_GlowLmpSta "This signal indicates that a status of glow lamp.



This signal is used for a Diesel or LPI Engine alternatively.";
BA_ "GenSigStartValue" SG_ 208 ENG_GlowLmpSta 1;
BA_ "UsrSigTimeoutValue" SG_ 208 ENG_GlowLmpSta "";
BA_ "UserSigValidity" SG_ 208 ENG_GlowLmpSta 3;
BA_ "SignalLongName" SG_ 208 ENG_GlowLmpSta "ENG_GlowLampStatus";
BA_ "Version" SG_ 208 ACC_CrsMainSwLmpSta "1.0";
BA_ "Description" SG_ 208 ACC_CrsMainSwLmpSta "This signal indicates that an ECU requests cluster to turn on/off auto-cruise control “MAIN” switch indication lamp.



This signal is for the CAN-type cluster installed vehicled only.";
BA_ "UsrSigTimeoutValue" SG_ 208 ACC_CrsMainSwLmpSta "";
BA_ "UserSigValidity" SG_ 208 ACC_CrsMainSwLmpSta 3;
BA_ "SignalLongName" SG_ 208 ACC_CrsMainSwLmpSta "ACC_CruiseMainSwLampStatus";
BA_ "Version" SG_ 208 ACC_CrsSetSwLmpSta "1.0";
BA_ "Description" SG_ 208 ACC_CrsSetSwLmpSta "This signal indicates that an ECU requests cluster to turn on/off auto-cruise control “SET” switch indication lamp.



This signal is for the CAN-type cluster installed vehicled only.";
BA_ "UsrSigTimeoutValue" SG_ 208 ACC_CrsSetSwLmpSta "";
BA_ "UserSigValidity" SG_ 208 ACC_CrsSetSwLmpSta 3;
BA_ "SignalLongName" SG_ 208 ACC_CrsSetSwLmpSta "ACC_CruiseSetSwLampStatus";
BA_ "Version" SG_ 208 ENG_PreFuelCutInSta "1.0";
BA_ "Description" SG_ 208 ENG_PreFuelCutInSta "During coast lock up control of TCU, if there occur a fuel cut in control suddenly then shift shock can happen. To prevent this, it is needed to inform fuel cut in control previously to TCU to release damper lock up before fuel cut in control start.";
BA_ "UsrSigTimeoutValue" SG_ 208 ENG_PreFuelCutInSta "";
BA_ "UserSigValidity" SG_ 208 ENG_PreFuelCutInSta 3;
BA_ "SignalLongName" SG_ 208 ENG_PreFuelCutInSta "ENG_PreFuelCutInStatus";
BA_ "Version" SG_ 208 ENG_EngSta "1.0";
BA_ "Description" SG_ 208 ENG_EngSta "This signal indicates that a status of engine.";
BA_ "UsrSigTimeoutValue" SG_ 208 ENG_EngSta "";
BA_ "UserSigValidity" SG_ 208 ENG_EngSta 3;
BA_ "SignalLongName" SG_ 208 ENG_EngSta "ENG_EngineStatus";
BA_ "Version" SG_ 208 ENG_SoakTimeErrSta "1.0";
BA_ "Description" SG_ 208 ENG_SoakTimeErrSta "This signal indicates that information on soak time error.";
BA_ "UsrSigTimeoutValue" SG_ 208 ENG_SoakTimeErrSta "";
BA_ "UserSigValidity" SG_ 208 ENG_SoakTimeErrSta 3;
BA_ "SignalLongName" SG_ 208 ENG_SoakTimeErrSta "ENG_SoakTimeErrorStatus";
BA_ "Version" SG_ 208 ENG_SoakTimeVal "1.0";
BA_ "Description" SG_ 208 ENG_SoakTimeVal "The Signal SOAK_TIME means the duration from Engine Ignition Off to Ignition On.";
BA_ "UsrSigTimeoutValue" SG_ 208 ENG_SoakTimeVal "";
BA_ "UserSigValidity" SG_ 208 ENG_SoakTimeVal 3;
BA_ "SignalLongName" SG_ 208 ENG_SoakTimeVal "ENG_SoakTimeValue";
BA_ "Version" SG_ 208 ENG_MaxIndTqVal "1.0";
BA_ "Description" SG_ 208 ENG_MaxIndTqVal "The signal TQI_MAX is the current maximum indicated engine torque. This signal reflects the maximum engine torque under current conditions (engine speed, etc…).



Note : TQI_MAX must be transmitted actual engine torque including COT, thermal/spark effi";
BA_ "UsrSigTimeoutValue" SG_ 208 ENG_MaxIndTqVal "";
BA_ "UserSigValidity" SG_ 208 ENG_MaxIndTqVal 3;
BA_ "SignalLongName" SG_ 208 ENG_MaxIndTqVal "ENG_MaximumIndicatedTorqueValue";
BA_ "Version" SG_ 208 ENG_SprkTimeVal "1.0";
BA_ "Description" SG_ 208 ENG_SprkTimeVal "This signal indicates output value of final spark timing from ECU which reflects torque intervention requests by ESC(TCS), SCC and TCU.



Physical range:

-35.625˚ … 0˚  =  00H .. 5FH (Retard)

0.375˚ … 60˚  =  60H .. FFH (Advance) 



Conversion:";
BA_ "UsrSigTimeoutValue" SG_ 208 ENG_SprkTimeVal "";
BA_ "UserSigValidity" SG_ 208 ENG_SprkTimeVal 3;
BA_ "SignalLongName" SG_ 208 ENG_SprkTimeVal "ENG_SparkTimeValue";
BA_ "Version" SG_ 208 ENG_AppAccelPdlSta "1.0";
BA_ "Description" SG_ 208 ENG_AppAccelPdlSta "This signal indicates if the driver applies the accelerator pedal. 

The signal always indicates the actual operation of the accelerator pedal, independent from SCC mode.";
BA_ "UsrSigTimeoutValue" SG_ 208 ENG_AppAccelPdlSta "";
BA_ "UserSigValidity" SG_ 208 ENG_AppAccelPdlSta 3;
BA_ "SignalLongName" SG_ 208 ENG_AppAccelPdlSta "ENG_AppliedAcceleratorPedalStatus";
BA_ "Version" SG_ 208 ENG_BstPrsrVal "1.0";
BA_ "Description" SG_ 208 ENG_BstPrsrVal "Boost pressure for Turbo engine";
BA_ "UsrSigTimeoutValue" SG_ 208 ENG_BstPrsrVal "";
BA_ "UserSigValidity" SG_ 208 ENG_BstPrsrVal 3;
BA_ "SignalLongName" SG_ 208 ENG_BstPrsrVal "ENG_BoostPressureValue";
BA_ "Version" SG_ 208 ENG_EngOilTempVal "1.0";
BA_ "Description" SG_ 208 ENG_EngOilTempVal "engine oil temperature";
BA_ "GenSigStartValue" SG_ 208 ENG_EngOilTempVal 53;
BA_ "UsrSigTimeoutValue" SG_ 208 ENG_EngOilTempVal "";
BA_ "UserSigValidity" SG_ 208 ENG_EngOilTempVal 3;
BA_ "SignalLongName" SG_ 208 ENG_EngOilTempVal "ENG_EngineOilTemperatureValue";
BA_ "Version" SG_ 208 ENG_DpfWrngSta "1.0";
BA_ "Description" SG_ 208 ENG_DpfWrngSta "The signal indicates the status of the 'DPF Warning Level'";
BA_ "UsrSigTimeoutValue" SG_ 208 ENG_DpfWrngSta "";
BA_ "UserSigValidity" SG_ 208 ENG_DpfWrngSta 3;
BA_ "SignalLongName" SG_ 208 ENG_DpfWrngSta "ENG_DpfWarningStatus";
BA_ "Version" SG_ 208 ENG_BattWrngLmpSta "1.0";
BA_ "Description" SG_ 208 ENG_BattWrngLmpSta "The signal indicates the status of the 'Battery Warning Lamp'";
BA_ "UsrSigTimeoutValue" SG_ 208 ENG_BattWrngLmpSta "";
BA_ "UserSigValidity" SG_ 208 ENG_BattWrngLmpSta 3;
BA_ "SignalLongName" SG_ 208 ENG_BattWrngLmpSta "ENG_BatteryWarningLampStatus";
BA_ "Version" SG_ 208 ENG_OilPrsrWrngLmpSta "1.0";
BA_ "Description" SG_ 208 ENG_OilPrsrWrngLmpSta "The signal indicates the status of the 'Oil Pressure Warning Lamp'";
BA_ "UsrSigTimeoutValue" SG_ 208 ENG_OilPrsrWrngLmpSta "";
BA_ "UserSigValidity" SG_ 208 ENG_OilPrsrWrngLmpSta 3;
BA_ "SignalLongName" SG_ 208 ENG_OilPrsrWrngLmpSta "ENG_OilPressureWarningLampStatus";
BA_ "Version" SG_ 48 DCT_AccelPdlVal "1.0";
BA_ "Description" SG_ 48 DCT_AccelPdlVal "The signal PV_AV_CAN is a measure of the Accelerator Pedal value.

The accelerator pedal value is determined via 2 pedal sensors, which are connected mechanically to the

accelerator pedal. If the EMS-ECU recognizes that the accelerator pedal is not acti";
BA_ "UsrSigTimeoutValue" SG_ 48 DCT_AccelPdlVal "";
BA_ "UserSigValidity" SG_ 48 DCT_AccelPdlVal 3;
BA_ "SignalLongName" SG_ 48 DCT_AccelPdlVal "DCT_AcceleratorPedalValue";
BA_ "Version" SG_ 48 DCT_EngSpdErrSta "1.0";
BA_ "Description" SG_ 48 DCT_EngSpdErrSta "The signal F_N_ENG identifies an error on searching for a long tooth or on engine speed sensing.

Note : in some cases a limp-home function can be activated in the ECU (the engine speed signal is then based on the camshaft signal), and the engine may run";
BA_ "UsrSigTimeoutValue" SG_ 48 DCT_EngSpdErrSta "";
BA_ "UserSigValidity" SG_ 48 DCT_EngSpdErrSta 3;
BA_ "SignalLongName" SG_ 48 DCT_EngSpdErrSta "DCT_EngineSpeedErrorStatus";
BA_ "Version" SG_ 48 DCT_EngSpdVal "1.0";
BA_ "Description" SG_ 48 DCT_EngSpdVal "The signal N is generated by crankshaft segment period measurement (in case of an six-cylinder engine, this corresponds to a crankshaft angle of 120°) and measured with a resolution of 4 us.

The signal N is represented as a 16 bit value.



The signal ";
BA_ "UsrSigTimeoutValue" SG_ 48 DCT_EngSpdVal "";
BA_ "UserSigValidity" SG_ 48 DCT_EngSpdVal 3;
BA_ "SignalLongName" SG_ 48 DCT_EngSpdVal "DCT_EngineSpeedValue";
BA_ "Version" SG_ 48 DCT_CrctEngTqVal "1.0";
BA_ "Description" SG_ 48 DCT_CrctEngTqVal "The signal TQI_ACOR comprises the actual indicated engine torque (determined by calculation within the engine management system) (lambda control, knock control, catalyst overheating prevention function, temperature influences, TCS, TCU torque interventio";
BA_ "UsrSigTimeoutValue" SG_ 48 DCT_CrctEngTqVal "";
BA_ "UserSigValidity" SG_ 48 DCT_CrctEngTqVal 3;
BA_ "SignalLongName" SG_ 48 DCT_CrctEngTqVal "DCT_CorrectedEngineTorqueValue";
BA_ "Version" SG_ 538 BAT_SocVal "1.0";
BA_ "Description" SG_ 538 BAT_SocVal "This signal is battery State of Charge as calculated by battery sensor.";
BA_ "UsrSigTimeoutValue" SG_ 538 BAT_SocVal "";
BA_ "GenSigTimeoutTime" SG_ 538 BAT_SocVal 2000;
BA_ "UserSigValidity" SG_ 538 BAT_SocVal 3;
BA_ "SignalLongName" SG_ 538 BAT_SocVal "BAT_StateOfChargeValue";
BA_ "Version" SG_ 528 ENG_ImmoLmpSta "1.0";
BA_ "Description" SG_ 528 ENG_ImmoLmpSta "This signals indicates that a status of Immobilizer lamp.";
BA_ "UsrSigTimeoutValue" SG_ 528 ENG_ImmoLmpSta "";
BA_ "GenSigTimeoutTime" SG_ 528 ENG_ImmoLmpSta 2000;
BA_ "UserSigValidity" SG_ 528 ENG_ImmoLmpSta 3;
BA_ "SignalLongName" SG_ 528 ENG_ImmoLmpSta "ENG_ImmobilizerLampStatus";
BA_ "Version" SG_ 528 ENG_MilSta "1.0";
BA_ "Description" SG_ 528 ENG_MilSta "The signal indicates the status of the 'Check Engine' light. Lamp activation is either effected statically or clocked (500 ms cycle, code sequence).

An evaluation within 10 ms is required to map the activation process as precisely as possible.

In case ";
BA_ "UsrSigTimeoutValue" SG_ 528 ENG_MilSta "";
BA_ "GenSigTimeoutTime" SG_ 528 ENG_MilSta 2000;
BA_ "UserSigValidity" SG_ 528 ENG_MilSta 3;
BA_ "SignalLongName" SG_ 528 ENG_MilSta "ENG_MalfunctionIndicationLampStatus";
BA_ "Version" SG_ 528 ENG_AtmsphPrsrVal "1.0";
BA_ "Description" SG_ 528 ENG_AtmsphPrsrVal "The value AMP_CAN specifies the atmospheric pressure in the unit [mmHg]. It is calculated from the altitude correction factor MAF_FAC_ALTI_MMV. (Modeling Value)

However, when AMP sensor is equipped, the value AMP_CAN is calculated from the sensor output";
BA_ "GenSigStartValue" SG_ 528 ENG_AtmsphPrsrVal 28;
BA_ "UsrSigTimeoutValue" SG_ 528 ENG_AtmsphPrsrVal "";
BA_ "GenSigTimeoutTime" SG_ 528 ENG_AtmsphPrsrVal 2000;
BA_ "UserSigValidity" SG_ 528 ENG_AtmsphPrsrVal 3;
BA_ "SignalLongName" SG_ 528 ENG_AtmsphPrsrVal "ENG_AtmosphericPressureValue";
BA_ "Version" SG_ 528 ENG_BattVoltVal "1.0";
BA_ "Description" SG_ 528 ENG_BattVoltVal "The battery voltage after main relay is transferred.";
BA_ "UsrSigTimeoutValue" SG_ 528 ENG_BattVoltVal "";
BA_ "GenSigTimeoutTime" SG_ 528 ENG_BattVoltVal 2000;
BA_ "UserSigValidity" SG_ 528 ENG_BattVoltVal 3;
BA_ "SignalLongName" SG_ 528 ENG_BattVoltVal "ENG_BatteryVoltageValue";
BA_ "Version" SG_ 528 SCC_SafetyFunctSta "1.0";
BA_ "Description" SG_ 528 SCC_SafetyFunctSta "This signal is Safety function operation bit.";
BA_ "UsrSigTimeoutValue" SG_ 528 SCC_SafetyFunctSta "";
BA_ "GenSigTimeoutTime" SG_ 528 SCC_SafetyFunctSta 2000;
BA_ "UserSigValidity" SG_ 528 SCC_SafetyFunctSta 3;
BA_ "SignalLongName" SG_ 528 SCC_SafetyFunctSta "SCC_SafetyFunctionStatus";
BA_ "Version" SG_ 528 SCC_InAirTempVal "1.0";
BA_ "Description" SG_ 528 SCC_InAirTempVal "IntAirTemp indicates intake air temperature of an engine.

A TCU controls oil pressure during gear shifting and also changes an air-con load compensation factor using this signal.";
BA_ "UsrSigTimeoutValue" SG_ 528 SCC_InAirTempVal "";
BA_ "GenSigTimeoutTime" SG_ 528 SCC_InAirTempVal 2000;
BA_ "UserSigValidity" SG_ 528 SCC_InAirTempVal 3;
BA_ "SignalLongName" SG_ 528 SCC_InAirTempVal "SCC_IntakeAirTemperatureValue";
BA_ "Version" SG_ 528 SCR_LvlWrngLmpSta "1.0";
BA_ "Description" SG_ 528 SCR_LvlWrngLmpSta "The signal indicates the status of the 'SCR level Warning lamp'";
BA_ "UsrSigTimeoutValue" SG_ 528 SCR_LvlWrngLmpSta "";
BA_ "GenSigTimeoutTime" SG_ 528 SCR_LvlWrngLmpSta 2000;
BA_ "UserSigValidity" SG_ 528 SCR_LvlWrngLmpSta 3;
BA_ "SignalLongName" SG_ 528 SCR_LvlWrngLmpSta "SCR_LevelWarningLampStatus";
BA_ "Version" SG_ 528 SCR_LvlWrngMsgDis "1.0";
BA_ "Description" SG_ 528 SCR_LvlWrngMsgDis "The signal indicates the status of the Message";
BA_ "UsrSigTimeoutValue" SG_ 528 SCR_LvlWrngMsgDis "";
BA_ "GenSigTimeoutTime" SG_ 528 SCR_LvlWrngMsgDis 2000;
BA_ "UserSigValidity" SG_ 528 SCR_LvlWrngMsgDis 3;
BA_ "SignalLongName" SG_ 528 SCR_LvlWrngMsgDis "SCR_LevelWarningMessageDisplay";
BA_ "Version" SG_ 528 SCR_SysErrMsgDis "1.0";
BA_ "Description" SG_ 528 SCR_SysErrMsgDis "The signal indicates warning message information which shall be displayed accroding to corresponding SCR error cases";
BA_ "UsrSigTimeoutValue" SG_ 528 SCR_SysErrMsgDis "";
BA_ "GenSigTimeoutTime" SG_ 528 SCR_SysErrMsgDis 2000;
BA_ "UserSigValidity" SG_ 528 SCR_SysErrMsgDis 3;
BA_ "SignalLongName" SG_ 528 SCR_SysErrMsgDis "SCR_SystemErrorMessageDisplay";
BA_ "Version" SG_ 528 SCR_IndcmtExitStaDis "1.0";
BA_ "Description" SG_ 528 SCR_IndcmtExitStaDis "Send information to CLU(or message center) about Inudcement exit condition";
BA_ "UsrSigTimeoutValue" SG_ 528 SCR_IndcmtExitStaDis "";
BA_ "GenSigTimeoutTime" SG_ 528 SCR_IndcmtExitStaDis 2000;
BA_ "UserSigValidity" SG_ 528 SCR_IndcmtExitStaDis 3;
BA_ "SignalLongName" SG_ 528 SCR_IndcmtExitStaDis "SCR_InducementExitConditionDisplay";
BA_ "Version" SG_ 528 SCR_UreaLvlSta "1.0";
BA_ "Description" SG_ 528 SCR_UreaLvlSta "The signal indicates UREA Level";
BA_ "UsrSigTimeoutValue" SG_ 528 SCR_UreaLvlSta "";
BA_ "GenSigTimeoutTime" SG_ 528 SCR_UreaLvlSta 2000;
BA_ "UserSigValidity" SG_ 528 SCR_UreaLvlSta 3;
BA_ "SignalLongName" SG_ 528 SCR_UreaLvlSta "SCR_UreaLevelStatus";
BA_ "Version" SG_ 528 SCR_RmnRstrtDis "1.0";
BA_ "Description" SG_ 528 SCR_RmnRstrtDis "This signal indicates the number of remaining restarts";
BA_ "UsrSigTimeoutValue" SG_ 528 SCR_RmnRstrtDis "";
BA_ "GenSigTimeoutTime" SG_ 528 SCR_RmnRstrtDis 2000;
BA_ "UserSigValidity" SG_ 528 SCR_RmnRstrtDis 3;
BA_ "SignalLongName" SG_ 528 SCR_RmnRstrtDis "SCR_RemainingRestartsDisplay";
BA_ "Version" SG_ 528 SCR_RmnDstDis "1.0";
BA_ "Description" SG_ 528 SCR_RmnDstDis "This signal indicates the remaining distance before engine can not be started";
BA_ "UsrSigTimeoutValue" SG_ 528 SCR_RmnDstDis "";
BA_ "GenSigTimeoutTime" SG_ 528 SCR_RmnDstDis 2000;
BA_ "UserSigValidity" SG_ 528 SCR_RmnDstDis 3;
BA_ "SignalLongName" SG_ 528 SCR_RmnDstDis "SCR_RemainingDistanceDisplay";
BA_ "Version" SG_ 581 OBD_EngRpmVal "1.0";
BA_ "Description" SG_ 581 OBD_EngRpmVal "PID_0CH : Parameter ID for CARB OBD regulation - SAE J1979 Service Mode 02

This signal indicates engine speed (RPM-Revolution per Min.) and compatible with signal “N” in EMS1 message.";
BA_ "UsrSigTimeoutValue" SG_ 581 OBD_EngRpmVal "";
BA_ "GenSigTimeoutTime" SG_ 581 OBD_EngRpmVal 2000;
BA_ "UserSigValidity" SG_ 581 OBD_EngRpmVal 3;
BA_ "SignalLongName" SG_ 581 OBD_EngRpmVal "OBD_EngineRpmValue";
BA_ "Version" SG_ 64 TCU_Crc1Val "1.0";
BA_ "Description" SG_ 64 TCU_Crc1Val "(PH) = 10H-(Least significant nibbles of (Byte0 + Byte1 + Byte2 + Byte3+ Byte4 + Byte5 + Byte6 + Byte7) + Most significant nibbles of (Byte0 + Byte1 + Byte2 + Byte3 + Byte4 + Byte5 + Byte6))";
BA_ "GenSigStartValue" SG_ 64 TCU_Crc1Val 4095;
BA_ "UsrSigTimeoutValue" SG_ 64 TCU_Crc1Val "";
BA_ "UserSigValidity" SG_ 64 TCU_Crc1Val 3;
BA_ "SignalLongName" SG_ 64 TCU_Crc1Val "TCU_Crc1Value";
BA_ "Version" SG_ 64 TCU_AlvCnt1Val "1.0";
BA_ "Description" SG_ 64 TCU_AlvCnt1Val "Alive Counter";
BA_ "UsrSigTimeoutValue" SG_ 64 TCU_AlvCnt1Val "";
BA_ "UserSigValidity" SG_ 64 TCU_AlvCnt1Val 3;
BA_ "SignalLongName" SG_ 64 TCU_AlvCnt1Val "TCU_AliveCounter1Value";
BA_ "Version" SG_ 64 TCU_GearSlctDis "1.0";
BA_ "Description" SG_ 64 TCU_GearSlctDis "Position (P, R, N..), which was identified by the gear selector.

In case the gear selector is in a intermediate position, the last clear recognized position is used.

There is no specific phase relationship between the output and any other signal.";
BA_ "GenSigStartValue" SG_ 64 TCU_GearSlctDis 9;
BA_ "UsrSigTimeoutValue" SG_ 64 TCU_GearSlctDis "";
BA_ "UserSigValidity" SG_ 64 TCU_GearSlctDis 3;
BA_ "SignalLongName" SG_ 64 TCU_GearSlctDis "TCU_GearSelectDisplay";
BA_ "Version" SG_ 64 TCU_TqRdctnPcVal "1.0";
BA_ "Description" SG_ 64 TCU_TqRdctnPcVal "The TCU requests a torque reduction via the signal TQI_TCU to the EMS. 

The requested torque TQI_TCU refers to a maximum torque TQ_STND. This conversion into a physical quantity provides a range of TQ_STND of 0..99.6094%.



TQI_TCU is not relevant to R";
BA_ "GenSigStartValue" SG_ 64 TCU_TqRdctnPcVal 255;
BA_ "UsrSigTimeoutValue" SG_ 64 TCU_TqRdctnPcVal "";
BA_ "UserSigValidity" SG_ 64 TCU_TqRdctnPcVal 3;
BA_ "SignalLongName" SG_ 64 TCU_TqRdctnPcVal "TCU_TorqueReductionPcValue";
BA_ "Version" SG_ 64 TCU_GearStepTyp "1.0";
BA_ "Description" SG_ 64 TCU_GearStepTyp "This signal indicates number of gear steps of step type automatic transmission(A/T) or Dual Clutch Transmission(DCT). A vehicle can have A/T or DCT variant according to its option, for example 4-speed A/T or 5-speed A/T can be equipped in the same kind o";
BA_ "UsrSigTimeoutValue" SG_ 64 TCU_GearStepTyp "";
BA_ "UserSigValidity" SG_ 64 TCU_GearStepTyp 3;
BA_ "SignalLongName" SG_ 64 TCU_GearStepTyp "TCU_GearStepType";
BA_ "Version" SG_ 64 TCU_GearShftSta "1.0";
BA_ "Description" SG_ 64 TCU_GearShftSta "SWI_GS indicates whether a gear change is being executed in the gearbox.



Note : Gear change means a gear shift at D-range and Garage shift(PRND).";
BA_ "UsrSigTimeoutValue" SG_ 64 TCU_GearShftSta "";
BA_ "UserSigValidity" SG_ 64 TCU_GearShftSta 3;
BA_ "SignalLongName" SG_ 64 TCU_GearShftSta "TCU_GearShiftStatus";
BA_ "Version" SG_ 64 TCU_TqCnvrtrSta "1.0";
BA_ "Description" SG_ 64 TCU_TqCnvrtrSta "Status converter clutch



There is no specific phase relationship between the output and any other signal.";
BA_ "UsrSigTimeoutValue" SG_ 64 TCU_TqCnvrtrSta "";
BA_ "UserSigValidity" SG_ 64 TCU_TqCnvrtrSta 3;
BA_ "SignalLongName" SG_ 64 TCU_TqCnvrtrSta "TCU_TorqueConverterStatus";
BA_ "Version" SG_ 64 TCU_CurrGearSta "1.0";
BA_ "Description" SG_ 64 TCU_CurrGearSta "CUR_GR indicates the gear speed which is currently engaged in the gearbox.";
BA_ "UsrSigTimeoutValue" SG_ 64 TCU_CurrGearSta "";
BA_ "UserSigValidity" SG_ 64 TCU_CurrGearSta 3;
BA_ "SignalLongName" SG_ 64 TCU_CurrGearSta "TCU_CurrentGearStatus";
BA_ "Version" SG_ 64 TCU_TrgtGearSta "1.0";
BA_ "Description" SG_ 64 TCU_TrgtGearSta "CF_Tcu_TarGr informs about the speed, which is currently engaged in the gearbox, or, in case of a gear change (SWI_GS), which speed is reached.



Note: Gear changes covering more than one speed are also possible.

In the P and N positions, the frictiona";
BA_ "UsrSigTimeoutValue" SG_ 64 TCU_TrgtGearSta "";
BA_ "UserSigValidity" SG_ 64 TCU_TrgtGearSta 3;
BA_ "SignalLongName" SG_ 64 TCU_TrgtGearSta "TCU_TargetGearStatus";
BA_ "Version" SG_ 64 TCU_CluTrgtGearSta "1.0";
BA_ "Description" SG_ 64 TCU_CluTrgtGearSta "TCH_CluTrgtGearSta informs about target gear of SS timing 

(For indicating Paddle shift or Manual mode on cluster)";
BA_ "UsrSigTimeoutValue" SG_ 64 TCU_CluTrgtGearSta "";
BA_ "UserSigValidity" SG_ 64 TCU_CluTrgtGearSta 3;
BA_ "SignalLongName" SG_ 64 TCU_CluTrgtGearSta "TCU_ClusterTargetGear";
BA_ "Version" SG_ 64 TCH_EngTrgtGearSta "1.0";
BA_ "Description" SG_ 64 TCH_EngTrgtGearSta "TCH_EngTrgtGearSta informs about target gear of SS timing 

(For indicating Paddle shift or Manual mode on cluster)";
BA_ "UsrSigTimeoutValue" SG_ 64 TCH_EngTrgtGearSta "";
BA_ "UserSigValidity" SG_ 64 TCH_EngTrgtGearSta 3;
BA_ "SignalLongName" SG_ 64 TCH_EngTrgtGearSta "TCU_EngineTargetGear";
BA_ "Version" SG_ 64 TCU_VehSpdKphVal "1.0";
BA_ "Description" SG_ 64 TCU_VehSpdKphVal "The vehicle speed calculated by TCU is transferred. 

If a vehicle has no vehicle speed sensor, no wheel speed sensor and no ABS(TCS/ESC) then it is impossible for an EMS to calculate veficle speed. In this case a TCU should calculate vehicle speed and s";
BA_ "UsrSigTimeoutValue" SG_ 64 TCU_VehSpdKphVal "";
BA_ "UserSigValidity" SG_ 64 TCU_VehSpdKphVal 3;
BA_ "SignalLongName" SG_ 64 TCU_VehSpdKphVal "TCU_VehicleSpeedKphValue";
BA_ "Version" SG_ 64 TCU_DcmlVehSpdKphVal "1.0";
BA_ "Description" SG_ 64 TCU_DcmlVehSpdKphVal "The signal VS_TCU_DECIAMAL means the value which is below decimal point of the vehicle speed.

For instance, if a vehicle speed is 13.75Km/h, VS_TCU means 13Km/h and VS_TCU_DECIMAL means 0.75Km/h.



Example)   VS_TCU = 13,  VS_TCU_DECIAMAL  = 96

Vehicl";
BA_ "UsrSigTimeoutValue" SG_ 64 TCU_DcmlVehSpdKphVal "";
BA_ "UserSigValidity" SG_ 64 TCU_DcmlVehSpdKphVal 3;
BA_ "SignalLongName" SG_ 64 TCU_DcmlVehSpdKphVal "TCU_VehicleSpeedDecimalKphValue";
BA_ "Version" SG_ 64 TCU_EngRpmDis "1.0";
BA_ "Description" SG_ 64 TCU_EngRpmDis "Engine RPM from TCU (Only for the display on Cluster)";
BA_ "UsrSigTimeoutValue" SG_ 64 TCU_EngRpmDis "";
BA_ "UserSigValidity" SG_ 64 TCU_EngRpmDis 3;
BA_ "SignalLongName" SG_ 64 TCU_EngRpmDis "TCU_EngineRpmDisplay";
BA_ "Version" SG_ 64 TCU_EngRpmDisSta "1.0";
BA_ "Description" SG_ 64 TCU_EngRpmDisSta "Flag for Engine RPM(from TCU) Display on Cluster, Only when this flag is set to 1, Cluster shall display the Engine RPM from TCU";
BA_ "UsrSigTimeoutValue" SG_ 64 TCU_EngRpmDisSta "";
BA_ "UserSigValidity" SG_ 64 TCU_EngRpmDisSta 3;
BA_ "SignalLongName" SG_ 64 TCU_EngRpmDisSta "TCU_EngineRpmDisplayStatus";
BA_ "Version" SG_ 64 TCU_GearLmpBlnkngReq "1.0";
BA_ "Description" SG_ 64 TCU_GearLmpBlnkngReq "Cluster controls blinking of Gear lamp receiving the request signal from TCU.";
BA_ "UsrSigTimeoutValue" SG_ 64 TCU_GearLmpBlnkngReq "";
BA_ "UserSigValidity" SG_ 64 TCU_GearLmpBlnkngReq 3;
BA_ "SignalLongName" SG_ 64 TCU_GearLmpBlnkngReq "TCU_GearLampBlinkingRequest";
BA_ "Version" SG_ 64 TCU_FuelCutInhbtReq "1.0";
BA_ "Description" SG_ 64 TCU_FuelCutInhbtReq "During coast down shifting, EMS may cut off fuel injection and as a result, a driver can feel bad shift feeling. In this case, to enhance shift quality, TCU needs inhibition of fuel cut off control.

This signal indicates inhibition of engine fuel cut of";
BA_ "UsrSigTimeoutValue" SG_ 64 TCU_FuelCutInhbtReq "";
BA_ "UserSigValidity" SG_ 64 TCU_FuelCutInhbtReq 3;
BA_ "SignalLongName" SG_ 64 TCU_FuelCutInhbtReq "TCU_FuelCutInhibitionRequest";
BA_ "Version" SG_ 64 TCU_SprtyIndxSta "1.0";
BA_ "Description" SG_ 64 TCU_SprtyIndxSta "Sporty index based on the driver's driving behaviour";
BA_ "UsrSigTimeoutValue" SG_ 64 TCU_SprtyIndxSta "";
BA_ "UserSigValidity" SG_ 64 TCU_SprtyIndxSta 3;
BA_ "SignalLongName" SG_ 64 TCU_SprtyIndxSta "TCU_SportyIndexStatus";
BA_ "Version" SG_ 64 TCU_DrvngModDis "1.0";
BA_ "Description" SG_ 64 TCU_DrvngModDis "Driving mode display by TCU";
BA_ "UsrSigTimeoutValue" SG_ 64 TCU_DrvngModDis "";
BA_ "UserSigValidity" SG_ 64 TCU_DrvngModDis 3;
BA_ "SignalLongName" SG_ 64 TCU_DrvngModDis "TCU_DrivingModeDisplay";
BA_ "Version" SG_ 64 TCU_SmrtShftSta "1.0";
BA_ "Description" SG_ 64 TCU_SmrtShftSta "Information of SmartShift";
BA_ "UsrSigTimeoutValue" SG_ 64 TCU_SmrtShftSta "";
BA_ "UserSigValidity" SG_ 64 TCU_SmrtShftSta 3;
BA_ "SignalLongName" SG_ 64 TCU_SmrtShftSta "TCU_SmartShiftStatus";
BA_ "Version" SG_ 64 TCU_NetrlCtrlSta "1.0";
BA_ "Description" SG_ 64 TCU_NetrlCtrlSta "This signal indicates the status of Neutral Control.";
BA_ "UsrSigTimeoutValue" SG_ 64 TCU_NetrlCtrlSta "";
BA_ "UserSigValidity" SG_ 64 TCU_NetrlCtrlSta 3;
BA_ "SignalLongName" SG_ 64 TCU_NetrlCtrlSta "TCU_NeutralControlStatus";
BA_ "Version" SG_ 64 TCU_ShftPtrnSta "1.0";
BA_ "Description" SG_ 64 TCU_ShftPtrnSta "It is an ID of current shift pattern which is being used by TCU.

The ID is assigned for each TCU.";
BA_ "UsrSigTimeoutValue" SG_ 64 TCU_ShftPtrnSta "";
BA_ "UserSigValidity" SG_ 64 TCU_ShftPtrnSta 3;
BA_ "SignalLongName" SG_ 64 TCU_ShftPtrnSta "TCU_ShiftPatternStatus";
BA_ "Version" SG_ 64 TCU_VgisInhbtReq "1.0";
BA_ "Description" SG_ 64 TCU_VgisInhbtReq "TCU requests ECU to inhibit the VGIS fuction from changing its status.";
BA_ "UsrSigTimeoutValue" SG_ 64 TCU_VgisInhbtReq "";
BA_ "UserSigValidity" SG_ 64 TCU_VgisInhbtReq 3;
BA_ "SignalLongName" SG_ 64 TCU_VgisInhbtReq "TCU_VgisInhibitionRequest";
BA_ "Version" SG_ 106 TCU_Crc2Val "1.0";
BA_ "Description" SG_ 106 TCU_Crc2Val "(PH) = 10H-(Least significant nibbles of (Byte0 + Byte1 + Byte2 + Byte3+ Byte4 + Byte5 + Byte6 + Byte7) + Most significant nibbles of (Byte0 + Byte1 + Byte2 + Byte3 + Byte4 + Byte5 + Byte6))";
BA_ "GenSigStartValue" SG_ 106 TCU_Crc2Val 4095;
BA_ "UsrSigTimeoutValue" SG_ 106 TCU_Crc2Val "";
BA_ "UserSigValidity" SG_ 106 TCU_Crc2Val 3;
BA_ "SignalLongName" SG_ 106 TCU_Crc2Val "TCU_Crc2Value";
BA_ "Version" SG_ 106 TCU_AlvCnt2Val "1.0";
BA_ "Description" SG_ 106 TCU_AlvCnt2Val "Alive Counter";
BA_ "UsrSigTimeoutValue" SG_ 106 TCU_AlvCnt2Val "";
BA_ "UserSigValidity" SG_ 106 TCU_AlvCnt2Val 3;
BA_ "SignalLongName" SG_ 106 TCU_AlvCnt2Val "TCU_AliveCounter2Value";
BA_ "Version" SG_ 106 TCU_AtTempCVal "1.0";
BA_ "Description" SG_ 106 TCU_AtTempCVal "Transmission fluid temperature in TCU sensed via an A/D converter; 

converted into degrees centigrade (°C).";
BA_ "GenSigStartValue" SG_ 106 TCU_AtTempCVal 255;
BA_ "UsrSigTimeoutValue" SG_ 106 TCU_AtTempCVal "";
BA_ "UserSigValidity" SG_ 106 TCU_AtTempCVal 3;
BA_ "SignalLongName" SG_ 106 TCU_AtTempCVal "TCU_AtTemperatureCValue";
BA_ "Version" SG_ 106 TCU_TqCnvrtrSpdVal "1.0";
BA_ "Description" SG_ 106 TCU_TqCnvrtrSpdVal "N_TC represents the speed of the torque converter turbine of the gearbox at gearbox-side.";
BA_ "UsrSigTimeoutValue" SG_ 106 TCU_TqCnvrtrSpdVal "";
BA_ "UserSigValidity" SG_ 106 TCU_TqCnvrtrSpdVal 3;
BA_ "SignalLongName" SG_ 106 TCU_TqCnvrtrSpdVal "TCU_TorqueConverterSpeedValue";
BA_ "Version" SG_ 106 TCU_ActvEcoRdySta "1.0";
BA_ "Description" SG_ 106 TCU_ActvEcoRdySta "TCU is ready to perform ‘Active Eco’ function. OR

TCU performs ‘Active Eco’ function.";
BA_ "UsrSigTimeoutValue" SG_ 106 TCU_ActvEcoRdySta "";
BA_ "UserSigValidity" SG_ 106 TCU_ActvEcoRdySta 3;
BA_ "SignalLongName" SG_ 106 TCU_ActvEcoRdySta "TCU_ActiveEcoReadyStatus";
BA_ "Version" SG_ 624 TCU_Crc3Val "1.0";
BA_ "GenSigStartValue" SG_ 624 TCU_Crc3Val 4095;
BA_ "UsrSigTimeoutValue" SG_ 624 TCU_Crc3Val "";
BA_ "GenSigTimeoutTime" SG_ 624 TCU_Crc3Val 2000;
BA_ "UserSigValidity" SG_ 624 TCU_Crc3Val 3;
BA_ "SignalLongName" SG_ 624 TCU_Crc3Val "TCU_Crc3Value";
BA_ "Version" SG_ 624 TCU_AlvCnt3Val "1.0";
BA_ "UsrSigTimeoutValue" SG_ 624 TCU_AlvCnt3Val "";
BA_ "GenSigTimeoutTime" SG_ 624 TCU_AlvCnt3Val 2000;
BA_ "UserSigValidity" SG_ 624 TCU_AlvCnt3Val 3;
BA_ "SignalLongName" SG_ 624 TCU_AlvCnt3Val "TCU_AliveCounter3Value";
BA_ "Version" SG_ 624 TCU_WrngMsgSta "1.0";
BA_ "Description" SG_ 624 TCU_WrngMsgSta "This signal indicates the status of “TCU Warning message”";
BA_ "UsrSigTimeoutValue" SG_ 624 TCU_WrngMsgSta "";
BA_ "GenSigTimeoutTime" SG_ 624 TCU_WrngMsgSta 2000;
BA_ "UserSigValidity" SG_ 624 TCU_WrngMsgSta 3;
BA_ "SignalLongName" SG_ 624 TCU_WrngMsgSta "TCU_WarningMessageStatus";
BA_ "Version" SG_ 624 TCU_VehStpTimeDis "1.0";
BA_ "Description" SG_ 624 TCU_VehStpTimeDis "Vehicle Stop Time, during which the vehicle should be stopped when both clutches of DCT are overheated";
BA_ "UsrSigTimeoutValue" SG_ 624 TCU_VehStpTimeDis "";
BA_ "GenSigTimeoutTime" SG_ 624 TCU_VehStpTimeDis 2000;
BA_ "UserSigValidity" SG_ 624 TCU_VehStpTimeDis 3;
BA_ "SignalLongName" SG_ 624 TCU_VehStpTimeDis "TCU_VehicleStopTimeDisplay";
BA_ "Version" SG_ 261 CCU_Crc1Val "1.0";
BA_ "Description" SG_ 261 CCU_Crc1Val "This value is used to check the FATC message is correctly transmitted.



(PH) = Byte0 XOR Byte1 XOR Byte2 XOR Byte3 XOR Byte 4 XOR Byte5 XOR Byte6

All unused bytes(Free) in the frame will be set to 00.";
BA_ "GenSigStartValue" SG_ 261 CCU_Crc1Val 4095;
BA_ "UsrSigTimeoutValue" SG_ 261 CCU_Crc1Val "";
BA_ "UserSigValidity" SG_ 261 CCU_Crc1Val 7;
BA_ "SignalLongName" SG_ 261 CCU_Crc1Val "CCU_Crc1Value";
BA_ "Version" SG_ 261 CCU_SrvLmpReq "1.0";
BA_ "Description" SG_ 261 CCU_SrvLmpReq "This signal indicates request of service Lamp";
BA_ "UsrSigTimeoutValue" SG_ 261 CCU_SrvLmpReq "";
BA_ "UserSigValidity" SG_ 261 CCU_SrvLmpReq 7;
BA_ "SignalLongName" SG_ 261 CCU_SrvLmpReq "CCU_ServiceLampRequest";
BA_ "Version" SG_ 768 CCU_OutTempCDis "1.0";
BA_ "Description" SG_ 768 CCU_OutTempCDis "This signal indicates Outside temperature (℉).";
BA_ "UsrSigTimeoutValue" SG_ 768 CCU_OutTempCDis "";
BA_ "GenSigTimeoutTime" SG_ 768 CCU_OutTempCDis 2000;
BA_ "UserSigValidity" SG_ 768 CCU_OutTempCDis 4;
BA_ "SignalLongName" SG_ 768 CCU_OutTempCDis "CCU_OutsideTemperatureCelciusDisplay";
BA_ "GenSigSendType" SG_ 768 CCU_OutTempCDis 0;
BA_ "Version" SG_ 768 CCU_OutTempDis "1.0";
BA_ "Description" SG_ 768 CCU_OutTempDis "Outside temperature in FATC sensed via an A/D converter; converted into degrees centigrade (℃)

This information is only used for climate control operation.";
BA_ "UsrSigTimeoutValue" SG_ 768 CCU_OutTempDis "";
BA_ "GenSigTimeoutTime" SG_ 768 CCU_OutTempDis 2000;
BA_ "UserSigValidity" SG_ 768 CCU_OutTempDis 4;
BA_ "SignalLongName" SG_ 768 CCU_OutTempDis "CCU_OutsideTemperatureDisplay";
BA_ "GenSigSendType" SG_ 768 CCU_OutTempDis 0;
BA_ "Version" SG_ 768 CCU_OutTempSnsrVal "1.0";
BA_ "Description" SG_ 768 CCU_OutTempSnsrVal "Actual temperature of Ambient Sensor via an A/D converter; converted into degrees

centigrade (℃).

This is raw data of ambient sensor; just transferred from Ambient Sensor Voltage.";
BA_ "UsrSigTimeoutValue" SG_ 768 CCU_OutTempSnsrVal "";
BA_ "GenSigTimeoutTime" SG_ 768 CCU_OutTempSnsrVal 2000;
BA_ "UserSigValidity" SG_ 768 CCU_OutTempSnsrVal 4;
BA_ "SignalLongName" SG_ 768 CCU_OutTempSnsrVal "CCU_OutsideTemperatureSensorValue";
BA_ "GenSigSendType" SG_ 768 CCU_OutTempSnsrVal 0;
BA_ "Version" SG_ 768 CCU_TempDispUnitSta "1.0";
BA_ "Description" SG_ 768 CCU_TempDispUnitSta "This signal indicates Temp unit of HTR Control (℃, ℉).";
BA_ "UsrSigTimeoutValue" SG_ 768 CCU_TempDispUnitSta "";
BA_ "GenSigTimeoutTime" SG_ 768 CCU_TempDispUnitSta 2000;
BA_ "UserSigValidity" SG_ 768 CCU_TempDispUnitSta 4;
BA_ "SignalLongName" SG_ 768 CCU_TempDispUnitSta "CCU_TemperatureDiplayUnitStatus";
BA_ "GenSigSendType" SG_ 768 CCU_TempDispUnitSta 0;
BA_ "Version" SG_ 442 ACU_SysWrngLmpDis "1";
BA_ "Description" SG_ 442 ACU_SysWrngLmpDis "This signal means information regarding ACU diagnostic information result & discrimination.



1) Default value : 0x0

2) Default value Transmit condition

    - When the input condition is not determined.

    - When the input condition is not supported";
BA_ "UsrSigTimeoutValue" SG_ 442 ACU_SysWrngLmpDis "";
BA_ "GenSigTimeoutTime" SG_ 442 ACU_SysWrngLmpDis 2000;
BA_ "UserSigValidity" SG_ 442 ACU_SysWrngLmpDis 3;
BA_ "SignalLongName" SG_ 442 ACU_SysWrngLmpDis "ACU_SystemWarningLampDisplay";
BA_ "Version" SG_ 442 ACU_TlltlLmpDis "1";
BA_ "Description" SG_ 442 ACU_TlltlLmpDis "This signal means information regarding Occupant status.



1) Default value : 0x0

2) Default value Transmit condition

    - When the input condition is not determined.

    - When the input condition is not supported.";
BA_ "UsrSigTimeoutValue" SG_ 442 ACU_TlltlLmpDis "";
BA_ "GenSigTimeoutTime" SG_ 442 ACU_TlltlLmpDis 2000;
BA_ "UserSigValidity" SG_ 442 ACU_TlltlLmpDis 3;
BA_ "SignalLongName" SG_ 442 ACU_TlltlLmpDis "ACU_TelltaleLampDisplay";
BA_ "Version" SG_ 442 ACU_SdArbgExtTyp "1";
BA_ "Description" SG_ 442 ACU_SdArbgExtTyp "This signal does not specify the types or variations of the side restraints such as the front side airbag only or both the front and the rear side airbag. If any side restraint is equipped, the signal responds as 'exists'.";
BA_ "UsrSigTimeoutValue" SG_ 442 ACU_SdArbgExtTyp "";
BA_ "GenSigTimeoutTime" SG_ 442 ACU_SdArbgExtTyp 2000;
BA_ "UserSigValidity" SG_ 442 ACU_SdArbgExtTyp 3;
BA_ "SignalLongName" SG_ 442 ACU_SdArbgExtTyp "ACU_SideAirbagExistanceType";
BA_ "Version" SG_ 1050 ODS_OccClassSta "1.0";
BA_ "Description" SG_ 1050 ODS_OccClassSta "Signal Value Table : reference with ODS Communiction instruction";
BA_ "GenSigStartValue" SG_ 1050 ODS_OccClassSta 4;
BA_ "UsrSigTimeoutValue" SG_ 1050 ODS_OccClassSta "";
BA_ "GenSigTimeoutTime" SG_ 1050 ODS_OccClassSta 5000;
BA_ "UserSigValidity" SG_ 1050 ODS_OccClassSta 3;
BA_ "SignalLongName" SG_ 1050 ODS_OccClassSta "ODS_OccupantClassificationStatus";
BA_ "Version" SG_ 810 BCM_WrngBzrSta "1";
BA_ "Description" SG_ 810 BCM_WrngBzrSta "Buzzer on command for warning";
BA_ "UsrSigTimeoutValue" SG_ 810 BCM_WrngBzrSta "";
BA_ "GenSigTimeoutTime" SG_ 810 BCM_WrngBzrSta 2000;
BA_ "UserSigValidity" SG_ 810 BCM_WrngBzrSta 0;
BA_ "SignalLongName" SG_ 810 BCM_WrngBzrSta "BCM_WarningBuzzerStatus";
BA_ "GenSigSendType" SG_ 810 BCM_WrngBzrSta 0;
BA_ "Version" SG_ 1168 BCM_RmtKeyReq "1";
BA_ "NetworkRequestHoldingTime" SG_ 1168 BCM_RmtKeyReq 5000;
BA_ "NetworkRequest" SG_ 1168 BCM_RmtKeyReq 0;
BA_ "UsrSigTimeoutValue" SG_ 1168 BCM_RmtKeyReq "";
BA_ "GenSigTimeoutTime" SG_ 1168 BCM_RmtKeyReq 0;
BA_ "UserSigValidity" SG_ 1168 BCM_RmtKeyReq 0;
BA_ "SignalLongName" SG_ 1168 BCM_RmtKeyReq "BCM_RemoteKeyRequest";
BA_ "GenSigSendType" SG_ 1168 BCM_RmtKeyReq 0;
BA_ "Version" SG_ 864 BAlarm_BglrAlrmSta "1";
BA_ "NetworkRequestHoldingTime" SG_ 864 BAlarm_BglrAlrmSta 5000;
BA_ "NetworkRequest" SG_ 864 BAlarm_BglrAlrmSta 0;
BA_ "UsrSigTimeoutValue" SG_ 864 BAlarm_BglrAlrmSta "";
BA_ "GenSigTimeoutTime" SG_ 864 BAlarm_BglrAlrmSta 2000;
BA_ "UserSigValidity" SG_ 864 BAlarm_BglrAlrmSta 0;
BA_ "SignalLongName" SG_ 864 BAlarm_BglrAlrmSta "BAlarm_BuglarAlarmStatus";
BA_ "GenSigSendType" SG_ 864 BAlarm_BglrAlrmSta 0;
BA_ "Version" SG_ 864 BCM_AccInSta "1";
BA_ "NetworkRequestHoldingTime" SG_ 864 BCM_AccInSta 5000;
BA_ "NetworkRequest" SG_ 864 BCM_AccInSta 0;
BA_ "UsrSigTimeoutValue" SG_ 864 BCM_AccInSta "";
BA_ "GenSigTimeoutTime" SG_ 864 BCM_AccInSta 2000;
BA_ "UserSigValidity" SG_ 864 BCM_AccInSta 0;
BA_ "SignalLongName" SG_ 864 BCM_AccInSta "BCM_AccInputStatus";
BA_ "GenSigSendType" SG_ 864 BCM_AccInSta 0;
BA_ "Version" SG_ 864 BCM_CntryConfgTyp "1";
BA_ "NetworkRequestHoldingTime" SG_ 864 BCM_CntryConfgTyp 5000;
BA_ "NetworkRequest" SG_ 864 BCM_CntryConfgTyp 0;
BA_ "UsrSigTimeoutValue" SG_ 864 BCM_CntryConfgTyp "";
BA_ "GenSigTimeoutTime" SG_ 864 BCM_CntryConfgTyp 2000;
BA_ "UserSigValidity" SG_ 864 BCM_CntryConfgTyp 0;
BA_ "SignalLongName" SG_ 864 BCM_CntryConfgTyp "BCM_CountryConfigurationType";
BA_ "GenSigSendType" SG_ 864 BCM_CntryConfgTyp 0;
BA_ "Version" SG_ 864 BCM_DrvOptTyp "1";
BA_ "Description" SG_ 864 BCM_DrvOptTyp "-(Old)C_RHD_Option";
BA_ "NetworkRequestHoldingTime" SG_ 864 BCM_DrvOptTyp 5000;
BA_ "NetworkRequest" SG_ 864 BCM_DrvOptTyp 0;
BA_ "UsrSigTimeoutValue" SG_ 864 BCM_DrvOptTyp "";
BA_ "GenSigTimeoutTime" SG_ 864 BCM_DrvOptTyp 2000;
BA_ "UserSigValidity" SG_ 864 BCM_DrvOptTyp 0;
BA_ "SignalLongName" SG_ 864 BCM_DrvOptTyp "BCM_DriveOptionType";
BA_ "GenSigSendType" SG_ 864 BCM_DrvOptTyp 0;
BA_ "Version" SG_ 864 BCM_Ign1Sta "1";
BA_ "NetworkRequestHoldingTime" SG_ 864 BCM_Ign1Sta 5000;
BA_ "NetworkRequest" SG_ 864 BCM_Ign1Sta 0;
BA_ "UsrSigTimeoutValue" SG_ 864 BCM_Ign1Sta "";
BA_ "GenSigTimeoutTime" SG_ 864 BCM_Ign1Sta 2000;
BA_ "UserSigValidity" SG_ 864 BCM_Ign1Sta 0;
BA_ "SignalLongName" SG_ 864 BCM_Ign1Sta "BCM_Ign1Status";
BA_ "GenSigSendType" SG_ 864 BCM_Ign1Sta 0;
BA_ "Version" SG_ 864 BCM_Ign2Sta "1";
BA_ "NetworkRequestHoldingTime" SG_ 864 BCM_Ign2Sta 5000;
BA_ "NetworkRequest" SG_ 864 BCM_Ign2Sta 0;
BA_ "UsrSigTimeoutValue" SG_ 864 BCM_Ign2Sta "";
BA_ "GenSigTimeoutTime" SG_ 864 BCM_Ign2Sta 2000;
BA_ "UserSigValidity" SG_ 864 BCM_Ign2Sta 0;
BA_ "SignalLongName" SG_ 864 BCM_Ign2Sta "BCM_Ign2Status";
BA_ "GenSigSendType" SG_ 864 BCM_Ign2Sta 0;
BA_ "Version" SG_ 864 BCM_KeyOnSta "1";
BA_ "NetworkRequestHoldingTime" SG_ 864 BCM_KeyOnSta 5000;
BA_ "NetworkRequest" SG_ 864 BCM_KeyOnSta 0;
BA_ "UsrSigTimeoutValue" SG_ 864 BCM_KeyOnSta "";
BA_ "GenSigTimeoutTime" SG_ 864 BCM_KeyOnSta 2000;
BA_ "UserSigValidity" SG_ 864 BCM_KeyOnSta 0;
BA_ "SignalLongName" SG_ 864 BCM_KeyOnSta "BCM_KeyOnStatus";
BA_ "GenSigSendType" SG_ 864 BCM_KeyOnSta 0;
BA_ "Version" SG_ 864 BCM_MtGearPosRSta "1";
BA_ "NetworkRequestHoldingTime" SG_ 864 BCM_MtGearPosRSta 5000;
BA_ "NetworkRequest" SG_ 864 BCM_MtGearPosRSta 0;
BA_ "UsrSigTimeoutValue" SG_ 864 BCM_MtGearPosRSta "";
BA_ "GenSigTimeoutTime" SG_ 864 BCM_MtGearPosRSta 2000;
BA_ "UserSigValidity" SG_ 864 BCM_MtGearPosRSta 0;
BA_ "SignalLongName" SG_ 864 BCM_MtGearPosRSta "BCM_MtGearPositionRStatus";
BA_ "GenSigSendType" SG_ 864 BCM_MtGearPosRSta 0;
BA_ "Version" SG_ 864 BCM_SmkOptTyp "1";
BA_ "Description" SG_ 864 BCM_SmkOptTyp "-(Old)C_PICOption";
BA_ "NetworkRequestHoldingTime" SG_ 864 BCM_SmkOptTyp 5000;
BA_ "NetworkRequest" SG_ 864 BCM_SmkOptTyp 0;
BA_ "UsrSigTimeoutValue" SG_ 864 BCM_SmkOptTyp "";
BA_ "GenSigTimeoutTime" SG_ 864 BCM_SmkOptTyp 2000;
BA_ "UserSigValidity" SG_ 864 BCM_SmkOptTyp 0;
BA_ "SignalLongName" SG_ 864 BCM_SmkOptTyp "BCM_SmkOptionType";
BA_ "GenSigSendType" SG_ 864 BCM_SmkOptTyp 0;
BA_ "Version" SG_ 864 BCM_WrngSta "1";
BA_ "Description" SG_ 864 BCM_WrngSta "Warning command og BCM";
BA_ "NetworkRequestHoldingTime" SG_ 864 BCM_WrngSta 5000;
BA_ "NetworkRequest" SG_ 864 BCM_WrngSta 0;
BA_ "UsrSigTimeoutValue" SG_ 864 BCM_WrngSta "";
BA_ "GenSigTimeoutTime" SG_ 864 BCM_WrngSta 2000;
BA_ "UserSigValidity" SG_ 864 BCM_WrngSta 0;
BA_ "SignalLongName" SG_ 864 BCM_WrngSta "BCM_WarningStatus";
BA_ "GenSigSendType" SG_ 864 BCM_WrngSta 0;
BA_ "Version" SG_ 864 HeatedSteerWheel_AutoOffSta "1";
BA_ "Description" SG_ 864 HeatedSteerWheel_AutoOffSta "This signal is used to sent information of 'Auto Off' state of Steering Wheel Heater







Auto Off : BCM cuts off Steering Wheel Heater Automatically after 30 mins On







0x0 : Manual Off or Fail Off or On of Default Value



0x1 : Automatically Off";
BA_ "NetworkRequestHoldingTime" SG_ 864 HeatedSteerWheel_AutoOffSta 5000;
BA_ "NetworkRequest" SG_ 864 HeatedSteerWheel_AutoOffSta 0;
BA_ "UsrSigTimeoutValue" SG_ 864 HeatedSteerWheel_AutoOffSta "";
BA_ "GenSigTimeoutTime" SG_ 864 HeatedSteerWheel_AutoOffSta 2000;
BA_ "UserSigValidity" SG_ 864 HeatedSteerWheel_AutoOffSta 0;
BA_ "SignalLongName" SG_ 864 HeatedSteerWheel_AutoOffSta "HeatedSteerWheel_AutoOffStatus";
BA_ "GenSigSendType" SG_ 864 HeatedSteerWheel_AutoOffSta 0;
BA_ "Version" SG_ 864 PHEV_FastChrgDrSwSta "1";
BA_ "Description" SG_ 864 PHEV_FastChrgDrSwSta "(EV) Fast Mode Charging Door Open Switch";
BA_ "NetworkRequestHoldingTime" SG_ 864 PHEV_FastChrgDrSwSta 5000;
BA_ "NetworkRequest" SG_ 864 PHEV_FastChrgDrSwSta 0;
BA_ "UsrSigTimeoutValue" SG_ 864 PHEV_FastChrgDrSwSta "";
BA_ "GenSigTimeoutTime" SG_ 864 PHEV_FastChrgDrSwSta 2000;
BA_ "UserSigValidity" SG_ 864 PHEV_FastChrgDrSwSta 0;
BA_ "SignalLongName" SG_ 864 PHEV_FastChrgDrSwSta "PHEV_FastChargingDoorSwitchStatus";
BA_ "GenSigSendType" SG_ 864 PHEV_FastChrgDrSwSta 0;
BA_ "Version" SG_ 864 PHEV_StndChrgDrOpnSwReq "1";
BA_ "Description" SG_ 864 PHEV_StndChrgDrOpnSwReq "(EV/PHEV) Standard Mode Charging Door Open Switch";
BA_ "NetworkRequestHoldingTime" SG_ 864 PHEV_StndChrgDrOpnSwReq 5000;
BA_ "NetworkRequest" SG_ 864 PHEV_StndChrgDrOpnSwReq 0;
BA_ "UsrSigTimeoutValue" SG_ 864 PHEV_StndChrgDrOpnSwReq "";
BA_ "GenSigTimeoutTime" SG_ 864 PHEV_StndChrgDrOpnSwReq 2000;
BA_ "UserSigValidity" SG_ 864 PHEV_StndChrgDrOpnSwReq 0;
BA_ "SignalLongName" SG_ 864 PHEV_StndChrgDrOpnSwReq "PHEV_StandardChargingDoorOpenSwitchRequest";
BA_ "GenSigSendType" SG_ 864 PHEV_StndChrgDrOpnSwReq 0;
BA_ "Version" SG_ 864 PHEV_RrChrgDrSwSta "1";
BA_ "Description" SG_ 864 PHEV_RrChrgDrSwSta "Rear Charging Door Open Switch";
BA_ "NetworkRequestHoldingTime" SG_ 864 PHEV_RrChrgDrSwSta 5000;
BA_ "NetworkRequest" SG_ 864 PHEV_RrChrgDrSwSta 0;
BA_ "UsrSigTimeoutValue" SG_ 864 PHEV_RrChrgDrSwSta "";
BA_ "GenSigTimeoutTime" SG_ 864 PHEV_RrChrgDrSwSta 2000;
BA_ "UserSigValidity" SG_ 864 PHEV_RrChrgDrSwSta 0;
BA_ "SignalLongName" SG_ 864 PHEV_RrChrgDrSwSta "PHEV_RearChargingDoorSwitchStatus";
BA_ "GenSigSendType" SG_ 864 PHEV_RrChrgDrSwSta 0;
BA_ "Version" SG_ 864 Warn_SunRoofOpnSta "1";
BA_ "Description" SG_ 864 Warn_SunRoofOpnSta "-Sunroof open/close state";
BA_ "NetworkRequestHoldingTime" SG_ 864 Warn_SunRoofOpnSta 5000;
BA_ "NetworkRequest" SG_ 864 Warn_SunRoofOpnSta 0;
BA_ "UsrSigTimeoutValue" SG_ 864 Warn_SunRoofOpnSta "";
BA_ "GenSigTimeoutTime" SG_ 864 Warn_SunRoofOpnSta 2000;
BA_ "UserSigValidity" SG_ 864 Warn_SunRoofOpnSta 0;
BA_ "SignalLongName" SG_ 864 Warn_SunRoofOpnSta "Warn_SunRoofOpenStatus";
BA_ "GenSigSendType" SG_ 864 Warn_SunRoofOpnSta 0;
BA_ "Version" SG_ 864 Wiper_RainSnsrOptionTyp "1";
BA_ "Description" SG_ 864 Wiper_RainSnsrOptionTyp "Rain Sensor Option Information";
BA_ "NetworkRequestHoldingTime" SG_ 864 Wiper_RainSnsrOptionTyp 5000;
BA_ "NetworkRequest" SG_ 864 Wiper_RainSnsrOptionTyp 0;
BA_ "UsrSigTimeoutValue" SG_ 864 Wiper_RainSnsrOptionTyp "";
BA_ "GenSigTimeoutTime" SG_ 864 Wiper_RainSnsrOptionTyp 2000;
BA_ "UserSigValidity" SG_ 864 Wiper_RainSnsrOptionTyp 0;
BA_ "SignalLongName" SG_ 864 Wiper_RainSnsrOptionTyp "Wiper_RainSensorOptionType";
BA_ "GenSigSendType" SG_ 864 Wiper_RainSnsrOptionTyp 0;
BA_ "Version" SG_ 864 Wiper_RainSnsrSta "1";
BA_ "Description" SG_ 864 Wiper_RainSnsrSta "This signal represents the status of Rain Sensor signal state.";
BA_ "NetworkRequestHoldingTime" SG_ 864 Wiper_RainSnsrSta 5000;
BA_ "NetworkRequest" SG_ 864 Wiper_RainSnsrSta 0;
BA_ "UsrSigTimeoutValue" SG_ 864 Wiper_RainSnsrSta "";
BA_ "GenSigTimeoutTime" SG_ 864 Wiper_RainSnsrSta 2000;
BA_ "UserSigValidity" SG_ 864 Wiper_RainSnsrSta 0;
BA_ "SignalLongName" SG_ 864 Wiper_RainSnsrSta "Wiper_RainSensorStatus";
BA_ "GenSigSendType" SG_ 864 Wiper_RainSnsrSta 0;
BA_ "Version" SG_ 864 PHEV_FuelDrDis "1";
BA_ "Description" SG_ 864 PHEV_FuelDrDis "PHEV Fuel Door Control CLU Display Message from BCM";
BA_ "NetworkRequestHoldingTime" SG_ 864 PHEV_FuelDrDis 5000;
BA_ "NetworkRequest" SG_ 864 PHEV_FuelDrDis 0;
BA_ "UsrSigTimeoutValue" SG_ 864 PHEV_FuelDrDis "";
BA_ "GenSigTimeoutTime" SG_ 864 PHEV_FuelDrDis 2000;
BA_ "UserSigValidity" SG_ 864 PHEV_FuelDrDis 0;
BA_ "SignalLongName" SG_ 864 PHEV_FuelDrDis "PHEV_FuelDoorDisplay";
BA_ "GenSigSendType" SG_ 864 PHEV_FuelDrDis 0;
BA_ "Version" SG_ 864 Wiper_RrWiperSwSta "1";
BA_ "Description" SG_ 864 Wiper_RrWiperSwSta "Multifunction Rear Wiper Switch Status";
BA_ "NetworkRequestHoldingTime" SG_ 864 Wiper_RrWiperSwSta 5000;
BA_ "NetworkRequest" SG_ 864 Wiper_RrWiperSwSta 0;
BA_ "UsrSigTimeoutValue" SG_ 864 Wiper_RrWiperSwSta "";
BA_ "GenSigTimeoutTime" SG_ 864 Wiper_RrWiperSwSta 2000;
BA_ "UserSigValidity" SG_ 864 Wiper_RrWiperSwSta 0;
BA_ "SignalLongName" SG_ 864 Wiper_RrWiperSwSta "Wiper_RearWiperSwitchStatus";
BA_ "GenSigSendType" SG_ 864 Wiper_RrWiperSwSta 0;
BA_ "Version" SG_ 864 Wiper_SwSta "1";
BA_ "Description" SG_ 864 Wiper_SwSta "Multi Fuction Wiper Switch Status



The value '0x1' means 'Int Sw On' or 'Auto Sw on' and its status determined by 'C_RainSnsOption' signal



0x1 : Wiper Int Sw on (C_RainSnsOption = 0x0)



0x1 : Wiper Auto Sw on (C_RainSnsOption = 0x1)";
BA_ "NetworkRequestHoldingTime" SG_ 864 Wiper_SwSta 5000;
BA_ "NetworkRequest" SG_ 864 Wiper_SwSta 0;
BA_ "UsrSigTimeoutValue" SG_ 864 Wiper_SwSta "";
BA_ "GenSigTimeoutTime" SG_ 864 Wiper_SwSta 2000;
BA_ "UserSigValidity" SG_ 864 Wiper_SwSta 0;
BA_ "SignalLongName" SG_ 864 Wiper_SwSta "Wiper_SwitchStatus";
BA_ "GenSigSendType" SG_ 864 Wiper_SwSta 0;
BA_ "Version" SG_ 869 Lamp_AvTailLmpSta "1";
BA_ "Description" SG_ 869 Lamp_AvTailLmpSta "-Send with at the same time with C_IntTailOn

-Initiail Value: 1";
BA_ "NetworkRequestHoldingTime" SG_ 869 Lamp_AvTailLmpSta 5000;
BA_ "NetworkRequest" SG_ 869 Lamp_AvTailLmpSta 0;
BA_ "GenSigStartValue" SG_ 869 Lamp_AvTailLmpSta 1;
BA_ "UsrSigTimeoutValue" SG_ 869 Lamp_AvTailLmpSta "";
BA_ "GenSigTimeoutTime" SG_ 869 Lamp_AvTailLmpSta 2000;
BA_ "UserSigValidity" SG_ 869 Lamp_AvTailLmpSta 0;
BA_ "SignalLongName" SG_ 869 Lamp_AvTailLmpSta "Lamp_AvTailLampStatus";
BA_ "GenSigSendType" SG_ 869 Lamp_AvTailLmpSta 0;
BA_ "Version" SG_ 869 Lamp_AutoLtSnsrHorVal "1";
BA_ "Description" SG_ 869 Lamp_AutoLtSnsrHorVal "This signal indicates autolight sensor output (for HUD)";
BA_ "NetworkRequestHoldingTime" SG_ 869 Lamp_AutoLtSnsrHorVal 5000;
BA_ "NetworkRequest" SG_ 869 Lamp_AutoLtSnsrHorVal 0;
BA_ "UsrSigTimeoutValue" SG_ 869 Lamp_AutoLtSnsrHorVal "";
BA_ "GenSigTimeoutTime" SG_ 869 Lamp_AutoLtSnsrHorVal 2000;
BA_ "UserSigValidity" SG_ 869 Lamp_AutoLtSnsrHorVal 0;
BA_ "SignalLongName" SG_ 869 Lamp_AutoLtSnsrHorVal "Lamp_AutoLightSensorHorValue";
BA_ "GenSigSendType" SG_ 869 Lamp_AutoLtSnsrHorVal 0;
BA_ "Version" SG_ 869 Lamp_AutoLtSnsrNightSta "1";
BA_ "Description" SG_ 869 Lamp_AutoLtSnsrNightSta "This signal indicates autolight sensor output";
BA_ "NetworkRequestHoldingTime" SG_ 869 Lamp_AutoLtSnsrNightSta 5000;
BA_ "NetworkRequest" SG_ 869 Lamp_AutoLtSnsrNightSta 0;
BA_ "UsrSigTimeoutValue" SG_ 869 Lamp_AutoLtSnsrNightSta "";
BA_ "GenSigTimeoutTime" SG_ 869 Lamp_AutoLtSnsrNightSta 2000;
BA_ "UserSigValidity" SG_ 869 Lamp_AutoLtSnsrNightSta 0;
BA_ "SignalLongName" SG_ 869 Lamp_AutoLtSnsrNightSta "Lamp_AutoLightSensorNightStatus";
BA_ "GenSigSendType" SG_ 869 Lamp_AutoLtSnsrNightSta 0;
BA_ "Version" SG_ 869 Lamp_AutoLtSwReq "1";
BA_ "Description" SG_ 869 Lamp_AutoLtSwReq "-AFLS inhibit signal

-GateWay Signal";
BA_ "NetworkRequestHoldingTime" SG_ 869 Lamp_AutoLtSwReq 5000;
BA_ "NetworkRequest" SG_ 869 Lamp_AutoLtSwReq 0;
BA_ "UsrSigTimeoutValue" SG_ 869 Lamp_AutoLtSwReq "";
BA_ "GenSigTimeoutTime" SG_ 869 Lamp_AutoLtSwReq 2000;
BA_ "UserSigValidity" SG_ 869 Lamp_AutoLtSwReq 0;
BA_ "SignalLongName" SG_ 869 Lamp_AutoLtSwReq "Lamp_AutoLightSwitchRequest";
BA_ "GenSigSendType" SG_ 869 Lamp_AutoLtSwReq 0;
BA_ "Version" SG_ 869 Lamp_ExtrnlTailLmpOnReq "1";
BA_ "Description" SG_ 869 Lamp_ExtrnlTailLmpOnReq "-(Old)C_EXTTailOn";
BA_ "NetworkRequestHoldingTime" SG_ 869 Lamp_ExtrnlTailLmpOnReq 5000;
BA_ "NetworkRequest" SG_ 869 Lamp_ExtrnlTailLmpOnReq 0;
BA_ "UsrSigTimeoutValue" SG_ 869 Lamp_ExtrnlTailLmpOnReq "";
BA_ "GenSigTimeoutTime" SG_ 869 Lamp_ExtrnlTailLmpOnReq 2000;
BA_ "UserSigValidity" SG_ 869 Lamp_ExtrnlTailLmpOnReq 0;
BA_ "SignalLongName" SG_ 869 Lamp_ExtrnlTailLmpOnReq "Lamp_ExternalTailLampOnRequest";
BA_ "GenSigSendType" SG_ 869 Lamp_ExtrnlTailLmpOnReq 0;
BA_ "Version" SG_ 869 Lamp_HbaCtrlModTyp "1";
BA_ "Description" SG_ 869 Lamp_HbaCtrlModTyp "This signal headlamp high control by BCM or HBA";
BA_ "NetworkRequestHoldingTime" SG_ 869 Lamp_HbaCtrlModTyp 5000;
BA_ "NetworkRequest" SG_ 869 Lamp_HbaCtrlModTyp 0;
BA_ "UsrSigTimeoutValue" SG_ 869 Lamp_HbaCtrlModTyp "";
BA_ "GenSigTimeoutTime" SG_ 869 Lamp_HbaCtrlModTyp 2000;
BA_ "UserSigValidity" SG_ 869 Lamp_HbaCtrlModTyp 0;
BA_ "SignalLongName" SG_ 869 Lamp_HbaCtrlModTyp "Lamp_HbaControlModeType";
BA_ "GenSigSendType" SG_ 869 Lamp_HbaCtrlModTyp 0;
BA_ "Version" SG_ 869 Lamp_HdLmpHiOnReq "1";
BA_ "Description" SG_ 869 Lamp_HdLmpHiOnReq "-(Old)C_HLampHighON";
BA_ "NetworkRequestHoldingTime" SG_ 869 Lamp_HdLmpHiOnReq 5000;
BA_ "NetworkRequest" SG_ 869 Lamp_HdLmpHiOnReq 0;
BA_ "UsrSigTimeoutValue" SG_ 869 Lamp_HdLmpHiOnReq "";
BA_ "GenSigTimeoutTime" SG_ 869 Lamp_HdLmpHiOnReq 2000;
BA_ "UserSigValidity" SG_ 869 Lamp_HdLmpHiOnReq 0;
BA_ "SignalLongName" SG_ 869 Lamp_HdLmpHiOnReq "Lamp_HeadLampHighOnRequest";
BA_ "GenSigSendType" SG_ 869 Lamp_HdLmpHiOnReq 0;
BA_ "Version" SG_ 869 Lamp_HdLmpLoOnReq "1";
BA_ "Description" SG_ 869 Lamp_HdLmpLoOnReq "-(Old)C_HLampLowON";
BA_ "NetworkRequestHoldingTime" SG_ 869 Lamp_HdLmpLoOnReq 5000;
BA_ "NetworkRequest" SG_ 869 Lamp_HdLmpLoOnReq 0;
BA_ "UsrSigTimeoutValue" SG_ 869 Lamp_HdLmpLoOnReq "";
BA_ "GenSigTimeoutTime" SG_ 869 Lamp_HdLmpLoOnReq 2000;
BA_ "UserSigValidity" SG_ 869 Lamp_HdLmpLoOnReq 0;
BA_ "SignalLongName" SG_ 869 Lamp_HdLmpLoOnReq "Lamp_HeadLampLowOnRequest";
BA_ "GenSigSendType" SG_ 869 Lamp_HdLmpLoOnReq 0;
BA_ "Version" SG_ 869 Lamp_IntTailLmpOnReq "1";
BA_ "Description" SG_ 869 Lamp_IntTailLmpOnReq "-(Old)C_INTTailOn";
BA_ "NetworkRequestHoldingTime" SG_ 869 Lamp_IntTailLmpOnReq 5000;
BA_ "NetworkRequest" SG_ 869 Lamp_IntTailLmpOnReq 0;
BA_ "UsrSigTimeoutValue" SG_ 869 Lamp_IntTailLmpOnReq "";
BA_ "GenSigTimeoutTime" SG_ 869 Lamp_IntTailLmpOnReq 2000;
BA_ "UserSigValidity" SG_ 869 Lamp_IntTailLmpOnReq 0;
BA_ "SignalLongName" SG_ 869 Lamp_IntTailLmpOnReq "Lamp_InternalTailLampOnRequest";
BA_ "GenSigSendType" SG_ 869 Lamp_IntTailLmpOnReq 0;
BA_ "Version" SG_ 869 Lamp_PassingLmpOnReq "1";
BA_ "Description" SG_ 869 Lamp_PassingLmpOnReq "-Lamp on command for passing lamp dedicated from headlamp";
BA_ "NetworkRequestHoldingTime" SG_ 869 Lamp_PassingLmpOnReq 5000;
BA_ "NetworkRequest" SG_ 869 Lamp_PassingLmpOnReq 0;
BA_ "UsrSigTimeoutValue" SG_ 869 Lamp_PassingLmpOnReq "";
BA_ "GenSigTimeoutTime" SG_ 869 Lamp_PassingLmpOnReq 2000;
BA_ "UserSigValidity" SG_ 869 Lamp_PassingLmpOnReq 0;
BA_ "SignalLongName" SG_ 869 Lamp_PassingLmpOnReq "Lamp_PassingLampOnRequest";
BA_ "GenSigSendType" SG_ 869 Lamp_PassingLmpOnReq 0;
BA_ "Version" SG_ 869 Lamp_UsaDrlSwSta "1";
BA_ "Description" SG_ 869 Lamp_UsaDrlSwSta "USA DRL SW State



(Transmit only USA & Non Autolight & DRL SW is On)";
BA_ "NetworkRequestHoldingTime" SG_ 869 Lamp_UsaDrlSwSta 5000;
BA_ "NetworkRequest" SG_ 869 Lamp_UsaDrlSwSta 0;
BA_ "UsrSigTimeoutValue" SG_ 869 Lamp_UsaDrlSwSta "";
BA_ "GenSigTimeoutTime" SG_ 869 Lamp_UsaDrlSwSta 2000;
BA_ "UserSigValidity" SG_ 869 Lamp_UsaDrlSwSta 0;
BA_ "SignalLongName" SG_ 869 Lamp_UsaDrlSwSta "Lamp_UsaDrlSwitchStatus";
BA_ "GenSigSendType" SG_ 869 Lamp_UsaDrlSwSta 0;
BA_ "Version" SG_ 906 USM_ArmBzrSta "1";
BA_ "NetworkRequestHoldingTime" SG_ 906 USM_ArmBzrSta 5000;
BA_ "NetworkRequest" SG_ 906 USM_ArmBzrSta 0;
BA_ "UsrSigTimeoutValue" SG_ 906 USM_ArmBzrSta "";
BA_ "GenSigTimeoutTime" SG_ 906 USM_ArmBzrSta 2000;
BA_ "UserSigValidity" SG_ 906 USM_ArmBzrSta 0;
BA_ "SignalLongName" SG_ 906 USM_ArmBzrSta "USM_ArmBuzzerStatus";
BA_ "GenSigSendType" SG_ 906 USM_ArmBzrSta 0;
BA_ "Version" SG_ 906 USM_AutoDrLkReq "1";
BA_ "NetworkRequestHoldingTime" SG_ 906 USM_AutoDrLkReq 5000;
BA_ "NetworkRequest" SG_ 906 USM_AutoDrLkReq 0;
BA_ "UsrSigTimeoutValue" SG_ 906 USM_AutoDrLkReq "";
BA_ "GenSigTimeoutTime" SG_ 906 USM_AutoDrLkReq 2000;
BA_ "UserSigValidity" SG_ 906 USM_AutoDrLkReq 0;
BA_ "SignalLongName" SG_ 906 USM_AutoDrLkReq "USM_AutoDoorLockRequest";
BA_ "GenSigSendType" SG_ 906 USM_AutoDrLkReq 0;
BA_ "Version" SG_ 906 USM_AutoDrUnLkReq "1";
BA_ "NetworkRequestHoldingTime" SG_ 906 USM_AutoDrUnLkReq 5000;
BA_ "NetworkRequest" SG_ 906 USM_AutoDrUnLkReq 0;
BA_ "UsrSigTimeoutValue" SG_ 906 USM_AutoDrUnLkReq "";
BA_ "GenSigTimeoutTime" SG_ 906 USM_AutoDrUnLkReq 2000;
BA_ "UserSigValidity" SG_ 906 USM_AutoDrUnLkReq 0;
BA_ "SignalLongName" SG_ 906 USM_AutoDrUnLkReq "USM_AutoDoorUnLockRequest";
BA_ "GenSigSendType" SG_ 906 USM_AutoDrUnLkReq 0;
BA_ "Version" SG_ 906 USM_EscrtHdLmpSta "1";
BA_ "NetworkRequestHoldingTime" SG_ 906 USM_EscrtHdLmpSta 5000;
BA_ "NetworkRequest" SG_ 906 USM_EscrtHdLmpSta 0;
BA_ "UsrSigTimeoutValue" SG_ 906 USM_EscrtHdLmpSta "";
BA_ "GenSigTimeoutTime" SG_ 906 USM_EscrtHdLmpSta 2000;
BA_ "UserSigValidity" SG_ 906 USM_EscrtHdLmpSta 0;
BA_ "SignalLongName" SG_ 906 USM_EscrtHdLmpSta "USM_EscortHeadLampStatus";
BA_ "GenSigSendType" SG_ 906 USM_EscrtHdLmpSta 0;
BA_ "Version" SG_ 906 USM_LkSndOptSta "1";
BA_ "Description" SG_ 906 USM_LkSndOptSta "Current setting value for Door Lock Sound Option";
BA_ "NetworkRequestHoldingTime" SG_ 906 USM_LkSndOptSta 5000;
BA_ "NetworkRequest" SG_ 906 USM_LkSndOptSta 0;
BA_ "UsrSigTimeoutValue" SG_ 906 USM_LkSndOptSta "";
BA_ "GenSigTimeoutTime" SG_ 906 USM_LkSndOptSta 2000;
BA_ "UserSigValidity" SG_ 906 USM_LkSndOptSta 0;
BA_ "SignalLongName" SG_ 906 USM_LkSndOptSta "USM_LockSoundOptionStatus";
BA_ "GenSigSendType" SG_ 906 USM_LkSndOptSta 0;
BA_ "Version" SG_ 906 USM_TwoTrnUnLkCurrentSta "1";
BA_ "NetworkRequestHoldingTime" SG_ 906 USM_TwoTrnUnLkCurrentSta 5000;
BA_ "NetworkRequest" SG_ 906 USM_TwoTrnUnLkCurrentSta 0;
BA_ "UsrSigTimeoutValue" SG_ 906 USM_TwoTrnUnLkCurrentSta "";
BA_ "GenSigTimeoutTime" SG_ 906 USM_TwoTrnUnLkCurrentSta 2000;
BA_ "UserSigValidity" SG_ 906 USM_TwoTrnUnLkCurrentSta 0;
BA_ "SignalLongName" SG_ 906 USM_TwoTrnUnLkCurrentSta "USM_TwoTurnUnlockCurrentStatus";
BA_ "GenSigSendType" SG_ 906 USM_TwoTrnUnLkCurrentSta 0;
BA_ "Version" SG_ 906 Mirror_FldReq "1";
BA_ "NetworkRequestHoldingTime" SG_ 906 Mirror_FldReq 5000;
BA_ "NetworkRequest" SG_ 906 Mirror_FldReq 0;
BA_ "UsrSigTimeoutValue" SG_ 906 Mirror_FldReq "";
BA_ "GenSigTimeoutTime" SG_ 906 Mirror_FldReq 2000;
BA_ "UserSigValidity" SG_ 906 Mirror_FldReq 0;
BA_ "SignalLongName" SG_ 906 Mirror_FldReq "Mirror_OSMirrFoldRequest";
BA_ "GenSigSendType" SG_ 906 Mirror_FldReq 0;
BA_ "Version" SG_ 906 PAS_DstLvlSta "1";
BA_ "Description" SG_ 906 PAS_DstLvlSta "This signal means PAS Distance variant(Short / Long)";
BA_ "NetworkRequestHoldingTime" SG_ 906 PAS_DstLvlSta 5000;
BA_ "NetworkRequest" SG_ 906 PAS_DstLvlSta 0;
BA_ "UsrSigTimeoutValue" SG_ 906 PAS_DstLvlSta "";
BA_ "GenSigTimeoutTime" SG_ 906 PAS_DstLvlSta 2000;
BA_ "UserSigValidity" SG_ 906 PAS_DstLvlSta 3;
BA_ "SignalLongName" SG_ 906 PAS_DstLvlSta "PAS_DistanceLevelStatus";
BA_ "GenSigSendType" SG_ 906 PAS_DstLvlSta 0;
BA_ "Version" SG_ 906 PAS_FrCtrWrngLvlDis "1";
BA_ "Description" SG_ 906 PAS_FrCtrWrngLvlDis "-Front center display";
BA_ "NetworkRequestHoldingTime" SG_ 906 PAS_FrCtrWrngLvlDis 5000;
BA_ "NetworkRequest" SG_ 906 PAS_FrCtrWrngLvlDis 0;
BA_ "UsrSigTimeoutValue" SG_ 906 PAS_FrCtrWrngLvlDis "";
BA_ "GenSigTimeoutTime" SG_ 906 PAS_FrCtrWrngLvlDis 2000;
BA_ "UserSigValidity" SG_ 906 PAS_FrCtrWrngLvlDis 0;
BA_ "SignalLongName" SG_ 906 PAS_FrCtrWrngLvlDis "PAS_FrontCenterWarningLevelDisplay";
BA_ "GenSigSendType" SG_ 906 PAS_FrCtrWrngLvlDis 0;
BA_ "Version" SG_ 906 PAS_FrLftWrngLvlDis "1";
BA_ "Description" SG_ 906 PAS_FrLftWrngLvlDis "-Front Left display";
BA_ "NetworkRequestHoldingTime" SG_ 906 PAS_FrLftWrngLvlDis 5000;
BA_ "NetworkRequest" SG_ 906 PAS_FrLftWrngLvlDis 0;
BA_ "UsrSigTimeoutValue" SG_ 906 PAS_FrLftWrngLvlDis "";
BA_ "GenSigTimeoutTime" SG_ 906 PAS_FrLftWrngLvlDis 2000;
BA_ "UserSigValidity" SG_ 906 PAS_FrLftWrngLvlDis 0;
BA_ "SignalLongName" SG_ 906 PAS_FrLftWrngLvlDis "PAS_FrontLeftWarningLevelDisplay";
BA_ "GenSigSendType" SG_ 906 PAS_FrLftWrngLvlDis 0;
BA_ "Version" SG_ 906 PAS_FrRtWrngLvlDis "1";
BA_ "Description" SG_ 906 PAS_FrRtWrngLvlDis "-Front Right display";
BA_ "NetworkRequestHoldingTime" SG_ 906 PAS_FrRtWrngLvlDis 5000;
BA_ "NetworkRequest" SG_ 906 PAS_FrRtWrngLvlDis 0;
BA_ "UsrSigTimeoutValue" SG_ 906 PAS_FrRtWrngLvlDis "";
BA_ "GenSigTimeoutTime" SG_ 906 PAS_FrRtWrngLvlDis 2000;
BA_ "UserSigValidity" SG_ 906 PAS_FrRtWrngLvlDis 0;
BA_ "SignalLongName" SG_ 906 PAS_FrRtWrngLvlDis "PAS_FrontRightWarningLevelDisplay";
BA_ "GenSigSendType" SG_ 906 PAS_FrRtWrngLvlDis 0;
BA_ "Version" SG_ 906 PAS_FrSnsrWrngLvlSta "1";
BA_ "Description" SG_ 906 PAS_FrSnsrWrngLvlSta "-Front Sensor warning";
BA_ "NetworkRequestHoldingTime" SG_ 906 PAS_FrSnsrWrngLvlSta 5000;
BA_ "NetworkRequest" SG_ 906 PAS_FrSnsrWrngLvlSta 0;
BA_ "UsrSigTimeoutValue" SG_ 906 PAS_FrSnsrWrngLvlSta "";
BA_ "GenSigTimeoutTime" SG_ 906 PAS_FrSnsrWrngLvlSta 2000;
BA_ "UserSigValidity" SG_ 906 PAS_FrSnsrWrngLvlSta 0;
BA_ "SignalLongName" SG_ 906 PAS_FrSnsrWrngLvlSta "PAS_FrontSensorWarningLevelStatus";
BA_ "GenSigSendType" SG_ 906 PAS_FrSnsrWrngLvlSta 0;
BA_ "Version" SG_ 906 PAS_OptTyp "1";
BA_ "Description" SG_ 906 PAS_OptTyp "this signal means PAS Option (Non, RPAS, PAS)";
BA_ "NetworkRequestHoldingTime" SG_ 906 PAS_OptTyp 5000;
BA_ "NetworkRequest" SG_ 906 PAS_OptTyp 0;
BA_ "UsrSigTimeoutValue" SG_ 906 PAS_OptTyp "";
BA_ "GenSigTimeoutTime" SG_ 906 PAS_OptTyp 2000;
BA_ "UserSigValidity" SG_ 906 PAS_OptTyp 3;
BA_ "SignalLongName" SG_ 906 PAS_OptTyp "PAS_OptionType";
BA_ "GenSigSendType" SG_ 906 PAS_OptTyp 0;
BA_ "Version" SG_ 906 PAS_RrCtrWrngLvlDis "1";
BA_ "Description" SG_ 906 PAS_RrCtrWrngLvlDis "-Rear center display";
BA_ "NetworkRequestHoldingTime" SG_ 906 PAS_RrCtrWrngLvlDis 5000;
BA_ "NetworkRequest" SG_ 906 PAS_RrCtrWrngLvlDis 0;
BA_ "UsrSigTimeoutValue" SG_ 906 PAS_RrCtrWrngLvlDis "";
BA_ "GenSigTimeoutTime" SG_ 906 PAS_RrCtrWrngLvlDis 2000;
BA_ "UserSigValidity" SG_ 906 PAS_RrCtrWrngLvlDis 0;
BA_ "SignalLongName" SG_ 906 PAS_RrCtrWrngLvlDis "PAS_RearCenterWarningLevelDisplay";
BA_ "GenSigSendType" SG_ 906 PAS_RrCtrWrngLvlDis 0;
BA_ "Version" SG_ 906 PAS_RrLftWrngLvlDis "1";
BA_ "Description" SG_ 906 PAS_RrLftWrngLvlDis "-Rear Left display";
BA_ "NetworkRequestHoldingTime" SG_ 906 PAS_RrLftWrngLvlDis 5000;
BA_ "NetworkRequest" SG_ 906 PAS_RrLftWrngLvlDis 0;
BA_ "UsrSigTimeoutValue" SG_ 906 PAS_RrLftWrngLvlDis "";
BA_ "GenSigTimeoutTime" SG_ 906 PAS_RrLftWrngLvlDis 2000;
BA_ "UserSigValidity" SG_ 906 PAS_RrLftWrngLvlDis 0;
BA_ "SignalLongName" SG_ 906 PAS_RrLftWrngLvlDis "PAS_RearLeftWarningLevelDisplay";
BA_ "GenSigSendType" SG_ 906 PAS_RrLftWrngLvlDis 0;
BA_ "Version" SG_ 906 PAS_RrRtWrngLvlDis "1";
BA_ "Description" SG_ 906 PAS_RrRtWrngLvlDis "-Rear Right display";
BA_ "NetworkRequestHoldingTime" SG_ 906 PAS_RrRtWrngLvlDis 5000;
BA_ "NetworkRequest" SG_ 906 PAS_RrRtWrngLvlDis 0;
BA_ "UsrSigTimeoutValue" SG_ 906 PAS_RrRtWrngLvlDis "";
BA_ "GenSigTimeoutTime" SG_ 906 PAS_RrRtWrngLvlDis 2000;
BA_ "UserSigValidity" SG_ 906 PAS_RrRtWrngLvlDis 0;
BA_ "SignalLongName" SG_ 906 PAS_RrRtWrngLvlDis "PAS_RearRightWarningLevelDisplay";
BA_ "GenSigSendType" SG_ 906 PAS_RrRtWrngLvlDis 0;
BA_ "Version" SG_ 906 PAS_RrSnsrWrngLvlSta "1";
BA_ "Description" SG_ 906 PAS_RrSnsrWrngLvlSta "-Rear Sensor warning";
BA_ "NetworkRequestHoldingTime" SG_ 906 PAS_RrSnsrWrngLvlSta 5000;
BA_ "NetworkRequest" SG_ 906 PAS_RrSnsrWrngLvlSta 0;
BA_ "UsrSigTimeoutValue" SG_ 906 PAS_RrSnsrWrngLvlSta "";
BA_ "GenSigTimeoutTime" SG_ 906 PAS_RrSnsrWrngLvlSta 2000;
BA_ "UserSigValidity" SG_ 906 PAS_RrSnsrWrngLvlSta 0;
BA_ "SignalLongName" SG_ 906 PAS_RrSnsrWrngLvlSta "PAS_RearSensorWarningLevelStatus";
BA_ "GenSigSendType" SG_ 906 PAS_RrSnsrWrngLvlSta 0;
BA_ "Version" SG_ 906 PAS_SysChkSndSta "1";
BA_ "Description" SG_ 906 PAS_SysChkSndSta "-PAS System state check sound";
BA_ "NetworkRequestHoldingTime" SG_ 906 PAS_SysChkSndSta 5000;
BA_ "NetworkRequest" SG_ 906 PAS_SysChkSndSta 0;
BA_ "UsrSigTimeoutValue" SG_ 906 PAS_SysChkSndSta "";
BA_ "GenSigTimeoutTime" SG_ 906 PAS_SysChkSndSta 2000;
BA_ "UserSigValidity" SG_ 906 PAS_SysChkSndSta 0;
BA_ "SignalLongName" SG_ 906 PAS_SysChkSndSta "PAS_SystemCheckSoundStatus";
BA_ "GenSigSendType" SG_ 906 PAS_SysChkSndSta 0;
BA_ "Version" SG_ 906 PAS_SysOnSta "1";
BA_ "Description" SG_ 906 PAS_SysOnSta "-PAS System operating status";
BA_ "NetworkRequestHoldingTime" SG_ 906 PAS_SysOnSta 5000;
BA_ "NetworkRequest" SG_ 906 PAS_SysOnSta 0;
BA_ "UsrSigTimeoutValue" SG_ 906 PAS_SysOnSta "";
BA_ "GenSigTimeoutTime" SG_ 906 PAS_SysOnSta 2000;
BA_ "UserSigValidity" SG_ 906 PAS_SysOnSta 0;
BA_ "SignalLongName" SG_ 906 PAS_SysOnSta "PAS_SystemOnStatus";
BA_ "GenSigSendType" SG_ 906 PAS_SysOnSta 0;
BA_ "Version" SG_ 906 SBR_AsstStBltWrngIndSta "1";
BA_ "NetworkRequestHoldingTime" SG_ 906 SBR_AsstStBltWrngIndSta 5000;
BA_ "NetworkRequest" SG_ 906 SBR_AsstStBltWrngIndSta 0;
BA_ "UsrSigTimeoutValue" SG_ 906 SBR_AsstStBltWrngIndSta "";
BA_ "GenSigTimeoutTime" SG_ 906 SBR_AsstStBltWrngIndSta 2000;
BA_ "UserSigValidity" SG_ 906 SBR_AsstStBltWrngIndSta 0;
BA_ "SignalLongName" SG_ 906 SBR_AsstStBltWrngIndSta "SBR_AssistSeatBeltWarningIndicatorStatus";
BA_ "GenSigSendType" SG_ 906 SBR_AsstStBltWrngIndSta 0;
BA_ "Version" SG_ 906 SBR_DrvStBltIndSta "1";
BA_ "NetworkRequestHoldingTime" SG_ 906 SBR_DrvStBltIndSta 5000;
BA_ "NetworkRequest" SG_ 906 SBR_DrvStBltIndSta 0;
BA_ "UsrSigTimeoutValue" SG_ 906 SBR_DrvStBltIndSta "";
BA_ "GenSigTimeoutTime" SG_ 906 SBR_DrvStBltIndSta 2000;
BA_ "UserSigValidity" SG_ 906 SBR_DrvStBltIndSta 0;
BA_ "SignalLongName" SG_ 906 SBR_DrvStBltIndSta "SBR_DriverSeatBeltIndicatorStatus";
BA_ "GenSigSendType" SG_ 906 SBR_DrvStBltIndSta 0;
BA_ "Version" SG_ 906 SBR_RrCtrStBltIndSta "1";
BA_ "NetworkRequestHoldingTime" SG_ 906 SBR_RrCtrStBltIndSta 5000;
BA_ "NetworkRequest" SG_ 906 SBR_RrCtrStBltIndSta 0;
BA_ "UsrSigTimeoutValue" SG_ 906 SBR_RrCtrStBltIndSta "";
BA_ "GenSigTimeoutTime" SG_ 906 SBR_RrCtrStBltIndSta 2000;
BA_ "UserSigValidity" SG_ 906 SBR_RrCtrStBltIndSta 0;
BA_ "SignalLongName" SG_ 906 SBR_RrCtrStBltIndSta "SBR_RearCenterSeatBeltIndicatorStatus";
BA_ "GenSigSendType" SG_ 906 SBR_RrCtrStBltIndSta 0;
BA_ "Version" SG_ 906 SBR_RrLftStBltWrngIndSta "1";
BA_ "NetworkRequestHoldingTime" SG_ 906 SBR_RrLftStBltWrngIndSta 5000;
BA_ "NetworkRequest" SG_ 906 SBR_RrLftStBltWrngIndSta 0;
BA_ "UsrSigTimeoutValue" SG_ 906 SBR_RrLftStBltWrngIndSta "";
BA_ "GenSigTimeoutTime" SG_ 906 SBR_RrLftStBltWrngIndSta 2000;
BA_ "UserSigValidity" SG_ 906 SBR_RrLftStBltWrngIndSta 0;
BA_ "SignalLongName" SG_ 906 SBR_RrLftStBltWrngIndSta "SBR_RearLeftSeatBeltWarningIndicatorStatus";
BA_ "GenSigSendType" SG_ 906 SBR_RrLftStBltWrngIndSta 0;
BA_ "Version" SG_ 906 SBR_RrRtStBltWrngIndSta "1";
BA_ "NetworkRequestHoldingTime" SG_ 906 SBR_RrRtStBltWrngIndSta 5000;
BA_ "NetworkRequest" SG_ 906 SBR_RrRtStBltWrngIndSta 0;
BA_ "UsrSigTimeoutValue" SG_ 906 SBR_RrRtStBltWrngIndSta "";
BA_ "GenSigTimeoutTime" SG_ 906 SBR_RrRtStBltWrngIndSta 2000;
BA_ "UserSigValidity" SG_ 906 SBR_RrRtStBltWrngIndSta 0;
BA_ "SignalLongName" SG_ 906 SBR_RrRtStBltWrngIndSta "SBR_RearRightSeatBeltWarningIndicatorStatus";
BA_ "GenSigSendType" SG_ 906 SBR_RrRtStBltWrngIndSta 0;
BA_ "Version" SG_ 906 SBR_StBltWrngBzrSta "1";
BA_ "Description" SG_ 906 SBR_StBltWrngBzrSta "-Seat belt Warning (Reminder) buzzer";
BA_ "NetworkRequestHoldingTime" SG_ 906 SBR_StBltWrngBzrSta 5000;
BA_ "NetworkRequest" SG_ 906 SBR_StBltWrngBzrSta 0;
BA_ "UsrSigTimeoutValue" SG_ 906 SBR_StBltWrngBzrSta "";
BA_ "GenSigTimeoutTime" SG_ 906 SBR_StBltWrngBzrSta 2000;
BA_ "UserSigValidity" SG_ 906 SBR_StBltWrngBzrSta 0;
BA_ "SignalLongName" SG_ 906 SBR_StBltWrngBzrSta "SBR_SeatBeltWarningBuzzerStatus";
BA_ "GenSigSendType" SG_ 906 SBR_StBltWrngBzrSta 0;
BA_ "Version" SG_ 906 USM_WrngSndLvlSta "1";
BA_ "Description" SG_ 906 USM_WrngSndLvlSta "Current setting value for PAS Sound Volume Level";
BA_ "NetworkRequestHoldingTime" SG_ 906 USM_WrngSndLvlSta 5000;
BA_ "NetworkRequest" SG_ 906 USM_WrngSndLvlSta 0;
BA_ "UsrSigTimeoutValue" SG_ 906 USM_WrngSndLvlSta "";
BA_ "GenSigTimeoutTime" SG_ 906 USM_WrngSndLvlSta 2000;
BA_ "UserSigValidity" SG_ 906 USM_WrngSndLvlSta 3;
BA_ "SignalLongName" SG_ 906 USM_WrngSndLvlSta "USM_WarningSoundLevelStatus";
BA_ "GenSigSendType" SG_ 906 USM_WrngSndLvlSta 0;
BA_ "Version" SG_ 906 Wiper_PrkngPosSta "1";
BA_ "NetworkRequestHoldingTime" SG_ 906 Wiper_PrkngPosSta 5000;
BA_ "NetworkRequest" SG_ 906 Wiper_PrkngPosSta 0;
BA_ "UsrSigTimeoutValue" SG_ 906 Wiper_PrkngPosSta "";
BA_ "GenSigTimeoutTime" SG_ 906 Wiper_PrkngPosSta 2000;
BA_ "UserSigValidity" SG_ 906 Wiper_PrkngPosSta 0;
BA_ "SignalLongName" SG_ 906 Wiper_PrkngPosSta "Wiper_ParkingPositionStatus";
BA_ "GenSigSendType" SG_ 906 Wiper_PrkngPosSta 0;
BA_ "Version" SG_ 21 DoorLock_PsvDrUnLkReq "1";
BA_ "UsrSigTimeoutValue" SG_ 21 DoorLock_PsvDrUnLkReq "";
BA_ "GenSigTimeoutTime" SG_ 21 DoorLock_PsvDrUnLkReq 0;
BA_ "UserSigValidity" SG_ 21 DoorLock_PsvDrUnLkReq 0;
BA_ "SignalLongName" SG_ 21 DoorLock_PsvDrUnLkReq "DoorLock_PassiveDoorUnLockRequest";
BA_ "GenSigSendType" SG_ 21 DoorLock_PsvDrUnLkReq 0;
BA_ "Version" SG_ 21 SMK_RmtKeyReq "1";
BA_ "Description" SG_ 21 SMK_RmtKeyReq "-(Old)C_SMKRKECMD";
BA_ "UsrSigTimeoutValue" SG_ 21 SMK_RmtKeyReq "";
BA_ "GenSigTimeoutTime" SG_ 21 SMK_RmtKeyReq 0;
BA_ "UserSigValidity" SG_ 21 SMK_RmtKeyReq 0;
BA_ "SignalLongName" SG_ 21 SMK_RmtKeyReq "SMK_RemoteKeyRequest";
BA_ "GenSigSendType" SG_ 21 SMK_RmtKeyReq 0;
BA_ "Version" SG_ 837 SMK_CltchIgnLkSwSta "1";
BA_ "Description" SG_ 837 SMK_CltchIgnLkSwSta "This signal indicates that SMK has detected an operation of a Ignition Lock switch. EMS uses this signal for improving drivability of manual trasmission vehicle.







If the SMK does not support this signal the value is 00H



0x0 : SMK determines that";
BA_ "UsrSigTimeoutValue" SG_ 837 SMK_CltchIgnLkSwSta "";
BA_ "GenSigTimeoutTime" SG_ 837 SMK_CltchIgnLkSwSta 2000;
BA_ "UserSigValidity" SG_ 837 SMK_CltchIgnLkSwSta 3;
BA_ "SignalLongName" SG_ 837 SMK_CltchIgnLkSwSta "SMK_ClutchIgnLockSwitchStatus";
BA_ "GenSigSendType" SG_ 837 SMK_CltchIgnLkSwSta 0;
BA_ "Version" SG_ 837 SMK_DeActvWrngSta "1";
BA_ "Description" SG_ 837 SMK_DeActvWrngSta "-(Old)C_Deactivation_Warning";
BA_ "UsrSigTimeoutValue" SG_ 837 SMK_DeActvWrngSta "";
BA_ "GenSigTimeoutTime" SG_ 837 SMK_DeActvWrngSta 2000;
BA_ "UserSigValidity" SG_ 837 SMK_DeActvWrngSta 0;
BA_ "SignalLongName" SG_ 837 SMK_DeActvWrngSta "SMK_DeActivationWarningStatus";
BA_ "GenSigSendType" SG_ 837 SMK_DeActvWrngSta 0;
BA_ "Version" SG_ 837 USM_HfreeOperModSta "1";
BA_ "UsrSigTimeoutValue" SG_ 837 USM_HfreeOperModSta "";
BA_ "GenSigTimeoutTime" SG_ 837 USM_HfreeOperModSta 2000;
BA_ "UserSigValidity" SG_ 837 USM_HfreeOperModSta 0;
BA_ "SignalLongName" SG_ 837 USM_HfreeOperModSta "USM_HandsFreeOperatingModeStatus";
BA_ "GenSigSendType" SG_ 837 USM_HfreeOperModSta 0;
BA_ "Version" SG_ 837 USM_WlcmLtSta "1";
BA_ "UsrSigTimeoutValue" SG_ 837 USM_WlcmLtSta "";
BA_ "GenSigTimeoutTime" SG_ 837 USM_WlcmLtSta 2000;
BA_ "UserSigValidity" SG_ 837 USM_WlcmLtSta 0;
BA_ "SignalLongName" SG_ 837 USM_WlcmLtSta "USM_WelcomeLightStatus";
BA_ "GenSigSendType" SG_ 837 USM_WlcmLtSta 0;
BA_ "Version" SG_ 848 SMK_StrtStpBtnWrngSta "1";
BA_ "Description" SG_ 848 SMK_StrtStpBtnWrngSta "-(Old)C_SSB_Warning";
BA_ "UsrSigTimeoutValue" SG_ 848 SMK_StrtStpBtnWrngSta "";
BA_ "GenSigTimeoutTime" SG_ 848 SMK_StrtStpBtnWrngSta 2000;
BA_ "UserSigValidity" SG_ 848 SMK_StrtStpBtnWrngSta 0;
BA_ "SignalLongName" SG_ 848 SMK_StrtStpBtnWrngSta "SMK_StartStopButtonWarningStatus";
BA_ "GenSigSendType" SG_ 848 SMK_StrtStpBtnWrngSta 0;
BA_ "Version" SG_ 858 Warn_DisWrngSta "1";
BA_ "Description" SG_ 858 Warn_DisWrngSta "-(Old)C_PICWarningIND



Changed Value Table ('15 1/12)



: 0x4 : Not Locked Warning → AC_Plug_Connected_Warning



for EV/PHEV SMK Warning Logic(Cranking Trial with AC Plug Connected)";
BA_ "UsrSigTimeoutValue" SG_ 858 Warn_DisWrngSta "";
BA_ "GenSigTimeoutTime" SG_ 858 Warn_DisWrngSta 2000;
BA_ "UserSigValidity" SG_ 858 Warn_DisWrngSta 0;
BA_ "SignalLongName" SG_ 858 Warn_DisWrngSta "Warn_DisplayWarningStatus";
BA_ "GenSigSendType" SG_ 858 Warn_DisWrngSta 0;
BA_ "Version" SG_ 858 Warn_IdOutWrngSta "1";
BA_ "Description" SG_ 858 Warn_IdOutWrngSta "-(Old)C_IDOUT_WNG";
BA_ "UsrSigTimeoutValue" SG_ 858 Warn_IdOutWrngSta "";
BA_ "GenSigTimeoutTime" SG_ 858 Warn_IdOutWrngSta 2000;
BA_ "UserSigValidity" SG_ 858 Warn_IdOutWrngSta 0;
BA_ "SignalLongName" SG_ 858 Warn_IdOutWrngSta "Warn_IdOutWarningStatus";
BA_ "GenSigSendType" SG_ 858 Warn_IdOutWrngSta 0;
BA_ "Version" SG_ 858 Warn_KeyBattLoWrngSta "1";
BA_ "Description" SG_ 858 Warn_KeyBattLoWrngSta "-(Old)C_KeyBATDischargeWarning";
BA_ "UsrSigTimeoutValue" SG_ 858 Warn_KeyBattLoWrngSta "";
BA_ "GenSigTimeoutTime" SG_ 858 Warn_KeyBattLoWrngSta 2000;
BA_ "UserSigValidity" SG_ 858 Warn_KeyBattLoWrngSta 0;
BA_ "SignalLongName" SG_ 858 Warn_KeyBattLoWrngSta "Warn_KeyBatteryLowWarningStatus";
BA_ "GenSigSendType" SG_ 858 Warn_KeyBattLoWrngSta 0;
BA_ "Version" SG_ 858 Warn_NotGearPosPWrngSta "1";
BA_ "Description" SG_ 858 Warn_NotGearPosPWrngSta "-(Old)C_Vehicle_not_P_Warning";
BA_ "UsrSigTimeoutValue" SG_ 858 Warn_NotGearPosPWrngSta "";
BA_ "GenSigTimeoutTime" SG_ 858 Warn_NotGearPosPWrngSta 2000;
BA_ "UserSigValidity" SG_ 858 Warn_NotGearPosPWrngSta 0;
BA_ "SignalLongName" SG_ 858 Warn_NotGearPosPWrngSta "Warn_NotGearPositionPWarningStatus";
BA_ "GenSigSendType" SG_ 858 Warn_NotGearPosPWrngSta 0;
BA_ "Version" SG_ 858 Warn_EsclFlWrngSta "1";
BA_ "Description" SG_ 858 Warn_EsclFlWrngSta "-(Old)C_ESCL_Fail_Warning";
BA_ "UsrSigTimeoutValue" SG_ 858 Warn_EsclFlWrngSta "";
BA_ "GenSigTimeoutTime" SG_ 858 Warn_EsclFlWrngSta 2000;
BA_ "UserSigValidity" SG_ 858 Warn_EsclFlWrngSta 0;
BA_ "SignalLongName" SG_ 858 Warn_EsclFlWrngSta "Warn_EsclFailWarningStatus";
BA_ "GenSigSendType" SG_ 858 Warn_EsclFlWrngSta 0;
BA_ "Version" SG_ 858 Warn_EsclNotLkWrngSta "1";
BA_ "Description" SG_ 858 Warn_EsclNotLkWrngSta "-(Old)C_ESCL_Notlocked_Warning";
BA_ "UsrSigTimeoutValue" SG_ 858 Warn_EsclNotLkWrngSta "";
BA_ "GenSigTimeoutTime" SG_ 858 Warn_EsclNotLkWrngSta 2000;
BA_ "UserSigValidity" SG_ 858 Warn_EsclNotLkWrngSta 0;
BA_ "SignalLongName" SG_ 858 Warn_EsclNotLkWrngSta "Warn_EsclNotLockWarningStatus";
BA_ "GenSigSendType" SG_ 858 Warn_EsclNotLkWrngSta 0;
BA_ "Version" SG_ 858 Warn_EsclNotUnLkWrngSta "1";
BA_ "Description" SG_ 858 Warn_EsclNotUnLkWrngSta "-(Old)C_ESCLNotUnlockWarning";
BA_ "UsrSigTimeoutValue" SG_ 858 Warn_EsclNotUnLkWrngSta "";
BA_ "GenSigTimeoutTime" SG_ 858 Warn_EsclNotUnLkWrngSta 2000;
BA_ "UserSigValidity" SG_ 858 Warn_EsclNotUnLkWrngSta 0;
BA_ "SignalLongName" SG_ 858 Warn_EsclNotUnLkWrngSta "Warn_EsclNotUnLockWarningStatus";
BA_ "GenSigSendType" SG_ 858 Warn_EsclNotUnLkWrngSta 0;
BA_ "Version" SG_ 858 Warn_ImmoLmpOnReq "1";
BA_ "Description" SG_ 858 Warn_ImmoLmpOnReq "-(Old)C_ImmoLp";
BA_ "UsrSigTimeoutValue" SG_ 858 Warn_ImmoLmpOnReq "";
BA_ "GenSigTimeoutTime" SG_ 858 Warn_ImmoLmpOnReq 2000;
BA_ "UserSigValidity" SG_ 858 Warn_ImmoLmpOnReq 0;
BA_ "SignalLongName" SG_ 858 Warn_ImmoLmpOnReq "Warn_ImmobilizerLampOnRequest";
BA_ "GenSigSendType" SG_ 858 Warn_ImmoLmpOnReq 0;
BA_ "Version" SG_ 800 TPMS_FLPosWrngLmpSta "1.0";
BA_ "Description" SG_ 800 TPMS_FLPosWrngLmpSta "The signal indicates the status of the “FL POSITION Warning lamp”";
BA_ "UsrSigTimeoutValue" SG_ 800 TPMS_FLPosWrngLmpSta "";
BA_ "GenSigTimeoutTime" SG_ 800 TPMS_FLPosWrngLmpSta 2000;
BA_ "UserSigValidity" SG_ 800 TPMS_FLPosWrngLmpSta 3;
BA_ "SignalLongName" SG_ 800 TPMS_FLPosWrngLmpSta "TPMS_FrontLeftPositionWarningLampStatus";
BA_ "Version" SG_ 800 TPMS_FRPosWrngLmpSta "1.0";
BA_ "Description" SG_ 800 TPMS_FRPosWrngLmpSta "The signal indicates the status of the “FR POSITION Warning lamp”";
BA_ "UsrSigTimeoutValue" SG_ 800 TPMS_FRPosWrngLmpSta "";
BA_ "GenSigTimeoutTime" SG_ 800 TPMS_FRPosWrngLmpSta 2000;
BA_ "UserSigValidity" SG_ 800 TPMS_FRPosWrngLmpSta 3;
BA_ "SignalLongName" SG_ 800 TPMS_FRPosWrngLmpSta "TPMS_FrontRightPositionWarningLampStatus";
BA_ "Version" SG_ 800 TPMS_RLPosWrngLmpSta "1.0";
BA_ "Description" SG_ 800 TPMS_RLPosWrngLmpSta "The signal indicates the status of the “RL POSITION Warning lamp”";
BA_ "UsrSigTimeoutValue" SG_ 800 TPMS_RLPosWrngLmpSta "";
BA_ "GenSigTimeoutTime" SG_ 800 TPMS_RLPosWrngLmpSta 2000;
BA_ "UserSigValidity" SG_ 800 TPMS_RLPosWrngLmpSta 3;
BA_ "SignalLongName" SG_ 800 TPMS_RLPosWrngLmpSta "TPMS_RearLeftPositionWarningLampStatus";
BA_ "Version" SG_ 800 TPMS_RRPosWrngLmpSta "1.0";
BA_ "Description" SG_ 800 TPMS_RRPosWrngLmpSta "The signal indicates the status of the “RR POSITION Warning lamp”";
BA_ "UsrSigTimeoutValue" SG_ 800 TPMS_RRPosWrngLmpSta "";
BA_ "GenSigTimeoutTime" SG_ 800 TPMS_RRPosWrngLmpSta 2000;
BA_ "UserSigValidity" SG_ 800 TPMS_RRPosWrngLmpSta 3;
BA_ "SignalLongName" SG_ 800 TPMS_RRPosWrngLmpSta "TPMS_RearRightPositionWarningLampStatus";
BA_ "Version" SG_ 800 TPMS_FLTirePrsrVal "1.0";
BA_ "Description" SG_ 800 TPMS_FLTirePrsrVal "The signal indicates the “FL tire pressure”.";
BA_ "UsrSigTimeoutValue" SG_ 800 TPMS_FLTirePrsrVal "";
BA_ "GenSigTimeoutTime" SG_ 800 TPMS_FLTirePrsrVal 2000;
BA_ "UserSigValidity" SG_ 800 TPMS_FLTirePrsrVal 3;
BA_ "SignalLongName" SG_ 800 TPMS_FLTirePrsrVal "TPMS_FrontLeftTirePressureValue";
BA_ "Version" SG_ 800 TPMS_FRTirePrsrVal "1.0";
BA_ "Description" SG_ 800 TPMS_FRTirePrsrVal "The signal indicates the “FR tire pressure”.";
BA_ "UsrSigTimeoutValue" SG_ 800 TPMS_FRTirePrsrVal "";
BA_ "GenSigTimeoutTime" SG_ 800 TPMS_FRTirePrsrVal 2000;
BA_ "UserSigValidity" SG_ 800 TPMS_FRTirePrsrVal 3;
BA_ "SignalLongName" SG_ 800 TPMS_FRTirePrsrVal "TPMS_FrontRightTirePressureValue";
BA_ "Version" SG_ 800 TPMS_RLTirePrsrVal "1.0";
BA_ "Description" SG_ 800 TPMS_RLTirePrsrVal "The signal indicates the “RL tire pressure”.";
BA_ "UsrSigTimeoutValue" SG_ 800 TPMS_RLTirePrsrVal "";
BA_ "GenSigTimeoutTime" SG_ 800 TPMS_RLTirePrsrVal 2000;
BA_ "UserSigValidity" SG_ 800 TPMS_RLTirePrsrVal 3;
BA_ "SignalLongName" SG_ 800 TPMS_RLTirePrsrVal "TPMS_RearLeftTirePressureValue";
BA_ "Version" SG_ 800 TPMS_RRTirePrsrVal "1.0";
BA_ "Description" SG_ 800 TPMS_RRTirePrsrVal "The signal indicates the “RR tire pressure”.";
BA_ "UsrSigTimeoutValue" SG_ 800 TPMS_RRTirePrsrVal "";
BA_ "GenSigTimeoutTime" SG_ 800 TPMS_RRTirePrsrVal 2000;
BA_ "UserSigValidity" SG_ 800 TPMS_RRTirePrsrVal 3;
BA_ "SignalLongName" SG_ 800 TPMS_RRTirePrsrVal "TPMS_RearRightTirePressureValue";
BA_ "Version" SG_ 800 TPMS_SnsrSta "1.0";
BA_ "Description" SG_ 800 TPMS_SnsrSta "The signal indicates the status of the TPMS";
BA_ "UsrSigTimeoutValue" SG_ 800 TPMS_SnsrSta "";
BA_ "GenSigTimeoutTime" SG_ 800 TPMS_SnsrSta 2000;
BA_ "UserSigValidity" SG_ 800 TPMS_SnsrSta 3;
BA_ "SignalLongName" SG_ 800 TPMS_SnsrSta "TPMS_SensorStatus";
BA_ "Version" SG_ 800 TPMS_WrngLmpSta "1.0";
BA_ "Description" SG_ 800 TPMS_WrngLmpSta "The signal indicates the status of the “TPMS Malfunction Warning lamp”";
BA_ "UsrSigTimeoutValue" SG_ 800 TPMS_WrngLmpSta "";
BA_ "GenSigTimeoutTime" SG_ 800 TPMS_WrngLmpSta 2000;
BA_ "UserSigValidity" SG_ 800 TPMS_WrngLmpSta 3;
BA_ "SignalLongName" SG_ 800 TPMS_WrngLmpSta "TPMS_WarninglampStatus";
BA_ "Version" SG_ 800 TPMS_TreadWrngLmpSta "1.0";
BA_ "Description" SG_ 800 TPMS_TreadWrngLmpSta "The signal indicates the status of the “TREAD Warning lamp”";
BA_ "UsrSigTimeoutValue" SG_ 800 TPMS_TreadWrngLmpSta "";
BA_ "GenSigTimeoutTime" SG_ 800 TPMS_TreadWrngLmpSta 2000;
BA_ "UserSigValidity" SG_ 800 TPMS_TreadWrngLmpSta 3;
BA_ "SignalLongName" SG_ 800 TPMS_TreadWrngLmpSta "TPMS_TreadWarningLampStatus";
BA_ "Version" SG_ 800 TPMS_PrsrUnitSta "1.0";
BA_ "Description" SG_ 800 TPMS_PrsrUnitSta "The signal indicates the unit of pressure for display on cluster.";
BA_ "UsrSigTimeoutValue" SG_ 800 TPMS_PrsrUnitSta "";
BA_ "GenSigTimeoutTime" SG_ 800 TPMS_PrsrUnitSta 2000;
BA_ "UserSigValidity" SG_ 800 TPMS_PrsrUnitSta 3;
BA_ "SignalLongName" SG_ 800 TPMS_PrsrUnitSta "TPMS_PressureUnit";
BA_ "Version" SG_ 688 AFLS_Sta "1.0";
BA_ "Description" SG_ 688 AFLS_Sta "This signal indicates AFLS state (whether AFLS is in active state or inactivated) and fault condition.

 

A cluster shall turn on 'AFLS' indication lamp in its display panel when this signal is set to '03H'.



A cluster shall blink on 'AFLS' indication";
BA_ "UsrSigTimeoutValue" SG_ 688 AFLS_Sta "";
BA_ "GenSigTimeoutTime" SG_ 688 AFLS_Sta 2000;
BA_ "UserSigValidity" SG_ 688 AFLS_Sta 3;
BA_ "SignalLongName" SG_ 688 AFLS_Sta "AFLS_Status";
BA_ "Version" SG_ 688 AFLS_TrfChgSta "1.0";
BA_ "Description" SG_ 688 AFLS_TrfChgSta "This signal indicates Traffic Change status what is change drive mode. If this signal is set to “01H”, this means that Traffic Change Mode is Enabled and Swivel is Disabled. 



Traffic Change mode on/off state is changed by passing beam switch keep up";
BA_ "UsrSigTimeoutValue" SG_ 688 AFLS_TrfChgSta "";
BA_ "GenSigTimeoutTime" SG_ 688 AFLS_TrfChgSta 2000;
BA_ "UserSigValidity" SG_ 688 AFLS_TrfChgSta 3;
BA_ "SignalLongName" SG_ 688 AFLS_TrfChgSta "AFLS_TrafficChangeStatus";
BA_ "Version" SG_ 688 AFLS_TrfChgUSMSta "1.0";
BA_ "Description" SG_ 688 AFLS_TrfChgUSMSta "This signal indicates Traffic Change status what is changed drive mode with user setting.



If this signal is set to ‘02H’, this means that Traffic change Mode is done. 

A cluster shall display at IGN ON in Traffic change Mode.



AFLS Traffic change";
BA_ "UsrSigTimeoutValue" SG_ 688 AFLS_TrfChgUSMSta "";
BA_ "GenSigTimeoutTime" SG_ 688 AFLS_TrfChgUSMSta 2000;
BA_ "UserSigValidity" SG_ 688 AFLS_TrfChgUSMSta 3;
BA_ "SignalLongName" SG_ 688 AFLS_TrfChgUSMSta "AFLS_TrafficChangeUSMStatus";
BA_ "Version" SG_ 688 AFLS_LedHLmpSta "1.0";
BA_ "Description" SG_ 688 AFLS_LedHLmpSta "This signal is LED headlamp status inform whether LED fail or not which is regulation of ECE, Domestic.



If LED H/Lamp detects LED failure then a cluster shall be turn on to 'LED' indicator in the display panel and It should be to display the words 'Ch";
BA_ "UsrSigTimeoutValue" SG_ 688 AFLS_LedHLmpSta "";
BA_ "GenSigTimeoutTime" SG_ 688 AFLS_LedHLmpSta 2000;
BA_ "UserSigValidity" SG_ 688 AFLS_LedHLmpSta 3;
BA_ "SignalLongName" SG_ 688 AFLS_LedHLmpSta "AFLS_LedHeadlampStatus";
BA_ "Version" SG_ 1024 AHLS_WrnLmpDis "1.0";
BA_ "Description" SG_ 1024 AHLS_WrnLmpDis "AHLS Malfunction & Fire Event Warning Lamp";
BA_ "UsrSigTimeoutValue" SG_ 1024 AHLS_WrnLmpDis "";
BA_ "GenSigTimeoutTime" SG_ 1024 AHLS_WrnLmpDis 2000;
BA_ "UserSigValidity" SG_ 1024 AHLS_WrnLmpDis 3;
BA_ "SignalLongName" SG_ 1024 AHLS_WrnLmpDis "AHLS_WarningLampDisplay";
BA_ "Version" SG_ 1024 AHLS_WrnMsgDis "1.0";
BA_ "Description" SG_ 1024 AHLS_WrnMsgDis "AHLS Malfunction & Fire Event Warning Message";
BA_ "UsrSigTimeoutValue" SG_ 1024 AHLS_WrnMsgDis "";
BA_ "GenSigTimeoutTime" SG_ 1024 AHLS_WrnMsgDis 2000;
BA_ "UserSigValidity" SG_ 1024 AHLS_WrnMsgDis 3;
BA_ "SignalLongName" SG_ 1024 AHLS_WrnMsgDis "AHLS_WarningMessageDisplay";
BA_ "Version" SG_ 1026 AVM_ViewSta "1";
BA_ "Description" SG_ 1026 AVM_ViewSta "This signal indicates AVM View State";
BA_ "GenSigStartValue" SG_ 1026 AVM_ViewSta 31;
BA_ "UsrSigTimeoutValue" SG_ 1026 AVM_ViewSta "";
BA_ "GenSigTimeoutTime" SG_ 1026 AVM_ViewSta 5000;
BA_ "UserSigValidity" SG_ 1026 AVM_ViewSta 3;
BA_ "SignalLongName" SG_ 1026 AVM_ViewSta "AVM_ViewStatus";
BA_ "GenSigSendType" SG_ 1026 AVM_ViewSta 0;
BA_ "Version" SG_ 1026 AVM_CamTyp "1";
BA_ "Description" SG_ 1026 AVM_CamTyp "To classify AVM Type (Full Type / Half Type)";
BA_ "GenSigStartValue" SG_ 1026 AVM_CamTyp 7;
BA_ "UsrSigTimeoutValue" SG_ 1026 AVM_CamTyp "";
BA_ "GenSigTimeoutTime" SG_ 1026 AVM_CamTyp 5000;
BA_ "UserSigValidity" SG_ 1026 AVM_CamTyp 3;
BA_ "SignalLongName" SG_ 1026 AVM_CamTyp "AVM_CameraType";
BA_ "GenSigSendType" SG_ 1026 AVM_CamTyp 0;
BA_ "Version" SG_ 1026 AVM_FrDisBtnTyp "1";
BA_ "Description" SG_ 1026 AVM_FrDisBtnTyp "This signal indicates the type of buttons at the front display mode.";
BA_ "UsrSigTimeoutValue" SG_ 1026 AVM_FrDisBtnTyp "";
BA_ "GenSigTimeoutTime" SG_ 1026 AVM_FrDisBtnTyp 5000;
BA_ "UserSigValidity" SG_ 1026 AVM_FrDisBtnTyp 3;
BA_ "SignalLongName" SG_ 1026 AVM_FrDisBtnTyp "AVM_FrontDisplayButtonType";
BA_ "GenSigSendType" SG_ 1026 AVM_FrDisBtnTyp 0;
BA_ "Version" SG_ 807 PSB_LHFlrSta "1.0";
BA_ "Description" SG_ 807 PSB_LHFlrSta "Information about availability of PSB_LH (LH Pre-Safe S/Belt).";
BA_ "UsrSigTimeoutValue" SG_ 807 PSB_LHFlrSta "";
BA_ "GenSigTimeoutTime" SG_ 807 PSB_LHFlrSta 2000;
BA_ "UserSigValidity" SG_ 807 PSB_LHFlrSta 3;
BA_ "SignalLongName" SG_ 807 PSB_LHFlrSta "PSB_LeftHandedFailureStatus";
BA_ "Version" SG_ 807 PSB_RHFlrSta "1.0";
BA_ "Description" SG_ 807 PSB_RHFlrSta "Information about availability of PSB_RH (LH Pre-Safe S/Belt).";
BA_ "UsrSigTimeoutValue" SG_ 807 PSB_RHFlrSta "";
BA_ "GenSigTimeoutTime" SG_ 807 PSB_RHFlrSta 2000;
BA_ "UserSigValidity" SG_ 807 PSB_RHFlrSta 3;
BA_ "SignalLongName" SG_ 807 PSB_RHFlrSta "PSB_RightHandedFailureStatus";
BA_ "Version" SG_ 940 Audio_VcRecSwSta "1";
BA_ "Description" SG_ 940 Audio_VcRecSwSta "Audio Voice recognition switch



MM-CAN Gateway needed







Long key decision time is 800ms";
BA_ "NetworkRequestHoldingTime" SG_ 940 Audio_VcRecSwSta 5000;
BA_ "NetworkRequest" SG_ 940 Audio_VcRecSwSta 0;
BA_ "UsrSigTimeoutValue" SG_ 940 Audio_VcRecSwSta "";
BA_ "GenSigTimeoutTime" SG_ 940 Audio_VcRecSwSta 2000;
BA_ "UserSigValidity" SG_ 940 Audio_VcRecSwSta 1;
BA_ "SignalLongName" SG_ 940 Audio_VcRecSwSta "Audio_VoiceReconitionSwitchStatus";
BA_ "GenSigSendType" SG_ 940 Audio_VcRecSwSta 0;
BA_ "Version" SG_ 940 Audio_BluetoothPhnClSwSta "1";
BA_ "Description" SG_ 940 Audio_BluetoothPhnClSwSta "Bluetooth phone call switch on/off



MM-CAN Gateway needed



Long key time is 800ms";
BA_ "NetworkRequestHoldingTime" SG_ 940 Audio_BluetoothPhnClSwSta 5000;
BA_ "NetworkRequest" SG_ 940 Audio_BluetoothPhnClSwSta 0;
BA_ "UsrSigTimeoutValue" SG_ 940 Audio_BluetoothPhnClSwSta "";
BA_ "GenSigTimeoutTime" SG_ 940 Audio_BluetoothPhnClSwSta 2000;
BA_ "UserSigValidity" SG_ 940 Audio_BluetoothPhnClSwSta 1;
BA_ "SignalLongName" SG_ 940 Audio_BluetoothPhnClSwSta "Audio_BluetoothPhoneCallSwitchStatus";
BA_ "GenSigSendType" SG_ 940 Audio_BluetoothPhnClSwSta 0;
BA_ "Version" SG_ 940 Audio_ModSwSta "1";
BA_ "Description" SG_ 940 Audio_ModSwSta "Audio Mode switch



MM-CAN Gateway needed







Long key decision time is 800ms";
BA_ "NetworkRequestHoldingTime" SG_ 940 Audio_ModSwSta 5000;
BA_ "NetworkRequest" SG_ 940 Audio_ModSwSta 0;
BA_ "UsrSigTimeoutValue" SG_ 940 Audio_ModSwSta "";
BA_ "GenSigTimeoutTime" SG_ 940 Audio_ModSwSta 2000;
BA_ "UserSigValidity" SG_ 940 Audio_ModSwSta 1;
BA_ "SignalLongName" SG_ 940 Audio_ModSwSta "Audio_ModeSwitchStatus";
BA_ "GenSigSendType" SG_ 940 Audio_ModSwSta 0;
BA_ "Version" SG_ 940 Audio_MutSwSta "1";
BA_ "Description" SG_ 940 Audio_MutSwSta "Audio Mute switch



MM-CAN Gateway needed







Long key decision time is 800ms";
BA_ "NetworkRequestHoldingTime" SG_ 940 Audio_MutSwSta 5000;
BA_ "NetworkRequest" SG_ 940 Audio_MutSwSta 0;
BA_ "UsrSigTimeoutValue" SG_ 940 Audio_MutSwSta "";
BA_ "GenSigTimeoutTime" SG_ 940 Audio_MutSwSta 2000;
BA_ "UserSigValidity" SG_ 940 Audio_MutSwSta 1;
BA_ "SignalLongName" SG_ 940 Audio_MutSwSta "Audio_MuteSwitchStatus";
BA_ "GenSigSendType" SG_ 940 Audio_MutSwSta 0;
BA_ "Version" SG_ 940 Audio_SeakDnSwSta "1";
BA_ "Description" SG_ 940 Audio_SeakDnSwSta "Audio Seek Down switch



MM-CAN Gateway needed







Long key decision time is 800ms";
BA_ "NetworkRequestHoldingTime" SG_ 940 Audio_SeakDnSwSta 5000;
BA_ "NetworkRequest" SG_ 940 Audio_SeakDnSwSta 0;
BA_ "UsrSigTimeoutValue" SG_ 940 Audio_SeakDnSwSta "";
BA_ "GenSigTimeoutTime" SG_ 940 Audio_SeakDnSwSta 2000;
BA_ "UserSigValidity" SG_ 940 Audio_SeakDnSwSta 1;
BA_ "SignalLongName" SG_ 940 Audio_SeakDnSwSta "Audio_SeakDownSwitchStatus";
BA_ "GenSigSendType" SG_ 940 Audio_SeakDnSwSta 0;
BA_ "Version" SG_ 940 Audio_SeakUpSwSta "1";
BA_ "Description" SG_ 940 Audio_SeakUpSwSta "Audio Seek Up switch



MM-CAN Gateway needed







Long key decision time is 800ms";
BA_ "NetworkRequestHoldingTime" SG_ 940 Audio_SeakUpSwSta 5000;
BA_ "NetworkRequest" SG_ 940 Audio_SeakUpSwSta 0;
BA_ "UsrSigTimeoutValue" SG_ 940 Audio_SeakUpSwSta "";
BA_ "GenSigTimeoutTime" SG_ 940 Audio_SeakUpSwSta 2000;
BA_ "UserSigValidity" SG_ 940 Audio_SeakUpSwSta 1;
BA_ "SignalLongName" SG_ 940 Audio_SeakUpSwSta "Audio_SeakUpSwitchStatus";
BA_ "GenSigSendType" SG_ 940 Audio_SeakUpSwSta 0;
BA_ "Version" SG_ 940 Audio_VolDnSwSta "1";
BA_ "Description" SG_ 940 Audio_VolDnSwSta "Audio Volume Down switch



MM-CAN Gateway needed







Long key decision time is 800ms";
BA_ "NetworkRequestHoldingTime" SG_ 940 Audio_VolDnSwSta 5000;
BA_ "NetworkRequest" SG_ 940 Audio_VolDnSwSta 0;
BA_ "UsrSigTimeoutValue" SG_ 940 Audio_VolDnSwSta "";
BA_ "GenSigTimeoutTime" SG_ 940 Audio_VolDnSwSta 2000;
BA_ "UserSigValidity" SG_ 940 Audio_VolDnSwSta 1;
BA_ "SignalLongName" SG_ 940 Audio_VolDnSwSta "Audio_VolumeDownSwitchStatus";
BA_ "GenSigSendType" SG_ 940 Audio_VolDnSwSta 0;
BA_ "Version" SG_ 940 Audio_VolUpSwSta "1";
BA_ "Description" SG_ 940 Audio_VolUpSwSta "Audio Volume Up switch



MM-CAN Gateway needed







Long Key decision time is 800ms";
BA_ "NetworkRequestHoldingTime" SG_ 940 Audio_VolUpSwSta 5000;
BA_ "NetworkRequest" SG_ 940 Audio_VolUpSwSta 0;
BA_ "UsrSigTimeoutValue" SG_ 940 Audio_VolUpSwSta "";
BA_ "GenSigTimeoutTime" SG_ 940 Audio_VolUpSwSta 2000;
BA_ "UserSigValidity" SG_ 940 Audio_VolUpSwSta 1;
BA_ "SignalLongName" SG_ 940 Audio_VolUpSwSta "Audio_VolumeUpSwitchStatus";
BA_ "GenSigSendType" SG_ 940 Audio_VolUpSwSta 0;
BA_ "Version" SG_ 940 Cluster_DisSwSta "1";
BA_ "Description" SG_ 940 Cluster_DisSwSta "Long key decision time is 1000ms";
BA_ "NetworkRequestHoldingTime" SG_ 940 Cluster_DisSwSta 5000;
BA_ "NetworkRequest" SG_ 940 Cluster_DisSwSta 0;
BA_ "UsrSigTimeoutValue" SG_ 940 Cluster_DisSwSta "";
BA_ "GenSigTimeoutTime" SG_ 940 Cluster_DisSwSta 2000;
BA_ "UserSigValidity" SG_ 940 Cluster_DisSwSta 1;
BA_ "SignalLongName" SG_ 940 Cluster_DisSwSta "Cluster_DisplaySwitchStatus";
BA_ "GenSigSendType" SG_ 940 Cluster_DisSwSta 0;
BA_ "Version" SG_ 940 Cluster_ScrlDnSwSta "1";
BA_ "NetworkRequestHoldingTime" SG_ 940 Cluster_ScrlDnSwSta 5000;
BA_ "NetworkRequest" SG_ 940 Cluster_ScrlDnSwSta 0;
BA_ "UsrSigTimeoutValue" SG_ 940 Cluster_ScrlDnSwSta "";
BA_ "GenSigTimeoutTime" SG_ 940 Cluster_ScrlDnSwSta 2000;
BA_ "UserSigValidity" SG_ 940 Cluster_ScrlDnSwSta 1;
BA_ "SignalLongName" SG_ 940 Cluster_ScrlDnSwSta "Cluster_ScrollDownSwitchStatus";
BA_ "GenSigSendType" SG_ 940 Cluster_ScrlDnSwSta 0;
BA_ "Version" SG_ 940 Cluster_ScrlOkSwSta "1";
BA_ "Description" SG_ 940 Cluster_ScrlOkSwSta "Long key decision time is 1000ms";
BA_ "NetworkRequestHoldingTime" SG_ 940 Cluster_ScrlOkSwSta 5000;
BA_ "NetworkRequest" SG_ 940 Cluster_ScrlOkSwSta 0;
BA_ "UsrSigTimeoutValue" SG_ 940 Cluster_ScrlOkSwSta "";
BA_ "GenSigTimeoutTime" SG_ 940 Cluster_ScrlOkSwSta 2000;
BA_ "UserSigValidity" SG_ 940 Cluster_ScrlOkSwSta 1;
BA_ "SignalLongName" SG_ 940 Cluster_ScrlOkSwSta "Cluster_ScrollOkSwitchStatus";
BA_ "GenSigSendType" SG_ 940 Cluster_ScrlOkSwSta 0;
BA_ "Version" SG_ 940 Cluster_ScrlUpSwSta "1";
BA_ "NetworkRequestHoldingTime" SG_ 940 Cluster_ScrlUpSwSta 5000;
BA_ "NetworkRequest" SG_ 940 Cluster_ScrlUpSwSta 0;
BA_ "UsrSigTimeoutValue" SG_ 940 Cluster_ScrlUpSwSta "";
BA_ "GenSigTimeoutTime" SG_ 940 Cluster_ScrlUpSwSta 2000;
BA_ "UserSigValidity" SG_ 940 Cluster_ScrlUpSwSta 1;
BA_ "SignalLongName" SG_ 940 Cluster_ScrlUpSwSta "SWRC_ClusterScrollUpSwitchStatus";
BA_ "GenSigSendType" SG_ 940 Cluster_ScrlUpSwSta 0;
BA_ "Version" SG_ 940 Cluster_TrpSwSta "1";
BA_ "Description" SG_ 940 Cluster_TrpSwSta "Long key decision time is 1000ms";
BA_ "NetworkRequestHoldingTime" SG_ 940 Cluster_TrpSwSta 5000;
BA_ "NetworkRequest" SG_ 940 Cluster_TrpSwSta 0;
BA_ "UsrSigTimeoutValue" SG_ 940 Cluster_TrpSwSta "";
BA_ "GenSigTimeoutTime" SG_ 940 Cluster_TrpSwSta 2000;
BA_ "UserSigValidity" SG_ 940 Cluster_TrpSwSta 1;
BA_ "SignalLongName" SG_ 940 Cluster_TrpSwSta "Cluster_TripSwitchStatus";
BA_ "GenSigSendType" SG_ 940 Cluster_TrpSwSta 0;
BA_ "Version" SG_ 940 Cruise_MainSwSta "1";
BA_ "Description" SG_ 940 Cruise_MainSwSta "cruise on/off switch

C-CAN Gateway needed";
BA_ "NetworkRequestHoldingTime" SG_ 940 Cruise_MainSwSta 5000;
BA_ "NetworkRequest" SG_ 940 Cruise_MainSwSta 0;
BA_ "UsrSigTimeoutValue" SG_ 940 Cruise_MainSwSta "";
BA_ "GenSigTimeoutTime" SG_ 940 Cruise_MainSwSta 2000;
BA_ "UserSigValidity" SG_ 940 Cruise_MainSwSta 3;
BA_ "SignalLongName" SG_ 940 Cruise_MainSwSta "Cruise_MainSwitchStatus";
BA_ "GenSigSendType" SG_ 940 Cruise_MainSwSta 0;
BA_ "Version" SG_ 940 Cruise_SwSta "1";
BA_ "Description" SG_ 940 Cruise_SwSta "cruise switch status

C-CAN Gateway needed";
BA_ "NetworkRequestHoldingTime" SG_ 940 Cruise_SwSta 5000;
BA_ "NetworkRequest" SG_ 940 Cruise_SwSta 0;
BA_ "UsrSigTimeoutValue" SG_ 940 Cruise_SwSta "";
BA_ "GenSigTimeoutTime" SG_ 940 Cruise_SwSta 2000;
BA_ "UserSigValidity" SG_ 940 Cruise_SwSta 3;
BA_ "SignalLongName" SG_ 940 Cruise_SwSta "Cruise_SwitchStatus";
BA_ "GenSigSendType" SG_ 940 Cruise_SwSta 0;
BA_ "Version" SG_ 832 Lamp_HdLmpHiSwSta "1";
BA_ "NetworkRequestHoldingTime" SG_ 832 Lamp_HdLmpHiSwSta 5000;
BA_ "NetworkRequest" SG_ 832 Lamp_HdLmpHiSwSta 0;
BA_ "UsrSigTimeoutValue" SG_ 832 Lamp_HdLmpHiSwSta "";
BA_ "GenSigTimeoutTime" SG_ 832 Lamp_HdLmpHiSwSta 2000;
BA_ "UserSigValidity" SG_ 832 Lamp_HdLmpHiSwSta 0;
BA_ "SignalLongName" SG_ 832 Lamp_HdLmpHiSwSta "Lamp_HeadLampHighSwitchStatus";
BA_ "GenSigSendType" SG_ 832 Lamp_HdLmpHiSwSta 0;
BA_ "Version" SG_ 832 Lamp_LtSwSta "1";
BA_ "NetworkRequestHoldingTime" SG_ 832 Lamp_LtSwSta 5000;
BA_ "NetworkRequest" SG_ 832 Lamp_LtSwSta 0;
BA_ "UsrSigTimeoutValue" SG_ 832 Lamp_LtSwSta "";
BA_ "GenSigTimeoutTime" SG_ 832 Lamp_LtSwSta 2000;
BA_ "UserSigValidity" SG_ 832 Lamp_LtSwSta 0;
BA_ "SignalLongName" SG_ 832 Lamp_LtSwSta "Lamp_LightSwitchStatus";
BA_ "GenSigSendType" SG_ 832 Lamp_LtSwSta 0;
BA_ "Version" SG_ 832 Lamp_OneTouchTrnSigLftSwSta "1";
BA_ "Description" SG_ 832 Lamp_OneTouchTrnSigLftSwSta "ONE TOUCH TURN SIGNAL FOR LH";
BA_ "NetworkRequestHoldingTime" SG_ 832 Lamp_OneTouchTrnSigLftSwSta 5000;
BA_ "NetworkRequest" SG_ 832 Lamp_OneTouchTrnSigLftSwSta 0;
BA_ "UsrSigTimeoutValue" SG_ 832 Lamp_OneTouchTrnSigLftSwSta "";
BA_ "GenSigTimeoutTime" SG_ 832 Lamp_OneTouchTrnSigLftSwSta 2000;
BA_ "UserSigValidity" SG_ 832 Lamp_OneTouchTrnSigLftSwSta 0;
BA_ "SignalLongName" SG_ 832 Lamp_OneTouchTrnSigLftSwSta "Lamp_OneTouchTurnSignalLeftSwitchStatus";
BA_ "GenSigSendType" SG_ 832 Lamp_OneTouchTrnSigLftSwSta 0;
BA_ "Version" SG_ 832 Lamp_OneTouchTrnSigRtSwSta "1";
BA_ "Description" SG_ 832 Lamp_OneTouchTrnSigRtSwSta "ONE TOUCH TURN SIGNAL FOR RH";
BA_ "NetworkRequestHoldingTime" SG_ 832 Lamp_OneTouchTrnSigRtSwSta 5000;
BA_ "NetworkRequest" SG_ 832 Lamp_OneTouchTrnSigRtSwSta 0;
BA_ "UsrSigTimeoutValue" SG_ 832 Lamp_OneTouchTrnSigRtSwSta "";
BA_ "GenSigTimeoutTime" SG_ 832 Lamp_OneTouchTrnSigRtSwSta 2000;
BA_ "UserSigValidity" SG_ 832 Lamp_OneTouchTrnSigRtSwSta 0;
BA_ "SignalLongName" SG_ 832 Lamp_OneTouchTrnSigRtSwSta "Lamp_OneTouchTurnSignalRightSwitchStatus";
BA_ "GenSigSendType" SG_ 832 Lamp_OneTouchTrnSigRtSwSta 0;
BA_ "Version" SG_ 832 Lamp_PassingLmpSwSta "1";
BA_ "NetworkRequestHoldingTime" SG_ 832 Lamp_PassingLmpSwSta 5000;
BA_ "NetworkRequest" SG_ 832 Lamp_PassingLmpSwSta 0;
BA_ "UsrSigTimeoutValue" SG_ 832 Lamp_PassingLmpSwSta "";
BA_ "GenSigTimeoutTime" SG_ 832 Lamp_PassingLmpSwSta 2000;
BA_ "UserSigValidity" SG_ 832 Lamp_PassingLmpSwSta 0;
BA_ "SignalLongName" SG_ 832 Lamp_PassingLmpSwSta "Lamp_PassingLampSwitchStatus";
BA_ "GenSigSendType" SG_ 832 Lamp_PassingLmpSwSta 0;
BA_ "Version" SG_ 832 Lamp_TrnSigLftSwSta "1";
BA_ "NetworkRequestHoldingTime" SG_ 832 Lamp_TrnSigLftSwSta 5000;
BA_ "NetworkRequest" SG_ 832 Lamp_TrnSigLftSwSta 0;
BA_ "UsrSigTimeoutValue" SG_ 832 Lamp_TrnSigLftSwSta "";
BA_ "GenSigTimeoutTime" SG_ 832 Lamp_TrnSigLftSwSta 2000;
BA_ "UserSigValidity" SG_ 832 Lamp_TrnSigLftSwSta 0;
BA_ "SignalLongName" SG_ 832 Lamp_TrnSigLftSwSta "Lamp_TurnSignalLeftSwitchStatus";
BA_ "GenSigSendType" SG_ 832 Lamp_TrnSigLftSwSta 0;
BA_ "Version" SG_ 832 Lamp_TrnSigRtSwSta "1";
BA_ "NetworkRequestHoldingTime" SG_ 832 Lamp_TrnSigRtSwSta 5000;
BA_ "NetworkRequest" SG_ 832 Lamp_TrnSigRtSwSta 0;
BA_ "UsrSigTimeoutValue" SG_ 832 Lamp_TrnSigRtSwSta "";
BA_ "GenSigTimeoutTime" SG_ 832 Lamp_TrnSigRtSwSta 2000;
BA_ "UserSigValidity" SG_ 832 Lamp_TrnSigRtSwSta 0;
BA_ "SignalLongName" SG_ 832 Lamp_TrnSigRtSwSta "Lamp_TurnSignalRightSwitchStatus";
BA_ "GenSigSendType" SG_ 832 Lamp_TrnSigRtSwSta 0;
BA_ "Version" SG_ 842 Wiper_AutoSwSta "1";
BA_ "NetworkRequestHoldingTime" SG_ 842 Wiper_AutoSwSta 5000;
BA_ "NetworkRequest" SG_ 842 Wiper_AutoSwSta 0;
BA_ "UsrSigTimeoutValue" SG_ 842 Wiper_AutoSwSta "";
BA_ "GenSigTimeoutTime" SG_ 842 Wiper_AutoSwSta 2000;
BA_ "UserSigValidity" SG_ 842 Wiper_AutoSwSta 0;
BA_ "SignalLongName" SG_ 842 Wiper_AutoSwSta "Wiper_AutoSwitchStatus";
BA_ "GenSigSendType" SG_ 842 Wiper_AutoSwSta 0;
BA_ "Version" SG_ 842 Wiper_HiSwSta "1";
BA_ "NetworkRequestHoldingTime" SG_ 842 Wiper_HiSwSta 5000;
BA_ "NetworkRequest" SG_ 842 Wiper_HiSwSta 0;
BA_ "UsrSigTimeoutValue" SG_ 842 Wiper_HiSwSta "";
BA_ "GenSigTimeoutTime" SG_ 842 Wiper_HiSwSta 2000;
BA_ "UserSigValidity" SG_ 842 Wiper_HiSwSta 0;
BA_ "SignalLongName" SG_ 842 Wiper_HiSwSta "Wiper_HighSwitchStatus";
BA_ "GenSigSendType" SG_ 842 Wiper_HiSwSta 0;
BA_ "Version" SG_ 842 Wiper_IntSta "1";
BA_ "NetworkRequestHoldingTime" SG_ 842 Wiper_IntSta 5000;
BA_ "NetworkRequest" SG_ 842 Wiper_IntSta 0;
BA_ "UsrSigTimeoutValue" SG_ 842 Wiper_IntSta "";
BA_ "GenSigTimeoutTime" SG_ 842 Wiper_IntSta 2000;
BA_ "UserSigValidity" SG_ 842 Wiper_IntSta 0;
BA_ "SignalLongName" SG_ 842 Wiper_IntSta "Wiper_IntermittentStatus";
BA_ "GenSigSendType" SG_ 842 Wiper_IntSta 0;
BA_ "Version" SG_ 842 Wiper_IntStepSta "1";
BA_ "NetworkRequestHoldingTime" SG_ 842 Wiper_IntStepSta 5000;
BA_ "NetworkRequest" SG_ 842 Wiper_IntStepSta 0;
BA_ "UsrSigTimeoutValue" SG_ 842 Wiper_IntStepSta "";
BA_ "GenSigTimeoutTime" SG_ 842 Wiper_IntStepSta 2000;
BA_ "UserSigValidity" SG_ 842 Wiper_IntStepSta 0;
BA_ "SignalLongName" SG_ 842 Wiper_IntStepSta "Wiper_IntermittentStepStatus";
BA_ "GenSigSendType" SG_ 842 Wiper_IntStepSta 0;
BA_ "Version" SG_ 842 Wiper_LoSwSta "1";
BA_ "NetworkRequestHoldingTime" SG_ 842 Wiper_LoSwSta 5000;
BA_ "NetworkRequest" SG_ 842 Wiper_LoSwSta 0;
BA_ "UsrSigTimeoutValue" SG_ 842 Wiper_LoSwSta "";
BA_ "GenSigTimeoutTime" SG_ 842 Wiper_LoSwSta 2000;
BA_ "UserSigValidity" SG_ 842 Wiper_LoSwSta 0;
BA_ "SignalLongName" SG_ 842 Wiper_LoSwSta "Wiper_LowSwitchStatus";
BA_ "GenSigSendType" SG_ 842 Wiper_LoSwSta 0;
BA_ "Version" SG_ 922 HWSW_SysSta "1";
BA_ "Description" SG_ 922 HWSW_SysSta "This signal indicates normal or failure status of HSWS. 



 - HSWS : Haptic Steering Warning System";
BA_ "NetworkRequestHoldingTime" SG_ 922 HWSW_SysSta 5000;
BA_ "NetworkRequest" SG_ 922 HWSW_SysSta 0;
BA_ "UsrSigTimeoutValue" SG_ 922 HWSW_SysSta "";
BA_ "GenSigTimeoutTime" SG_ 922 HWSW_SysSta 2000;
BA_ "UserSigValidity" SG_ 922 HWSW_SysSta 3;
BA_ "SignalLongName" SG_ 922 HWSW_SysSta "HWSW_SystemStatus";
BA_ "GenSigSendType" SG_ 922 HWSW_SysSta 0;
BA_ "Version" SG_ 922 USM_CmdSta "1";
BA_ "NetworkRequestHoldingTime" SG_ 922 USM_CmdSta 5000;
BA_ "NetworkRequest" SG_ 922 USM_CmdSta 0;
BA_ "UsrSigTimeoutValue" SG_ 922 USM_CmdSta "";
BA_ "GenSigTimeoutTime" SG_ 922 USM_CmdSta 2000;
BA_ "UserSigValidity" SG_ 922 USM_CmdSta 0;
BA_ "SignalLongName" SG_ 922 USM_CmdSta "USM_CommandStatus";
BA_ "GenSigSendType" SG_ 922 USM_CmdSta 0;
BA_ "Version" SG_ 1177 HCIMS_PlyBckReq "1";
BA_ "Description" SG_ 1177 HCIMS_PlyBckReq "Signal for Health Care IMS Playback DB Number";
BA_ "NetworkRequestHoldingTime" SG_ 1177 HCIMS_PlyBckReq 5000;
BA_ "NetworkRequest" SG_ 1177 HCIMS_PlyBckReq 0;
BA_ "UsrSigTimeoutValue" SG_ 1177 HCIMS_PlyBckReq "";
BA_ "GenSigTimeoutTime" SG_ 1177 HCIMS_PlyBckReq 0;
BA_ "UserSigValidity" SG_ 1177 HCIMS_PlyBckReq 0;
BA_ "SignalLongName" SG_ 1177 HCIMS_PlyBckReq "HCIMS_PlayBackRequest";
BA_ "GenSigSendType" SG_ 1177 HCIMS_PlyBckReq 0;
BA_ "Version" SG_ 1177 PSM_DrvStImsBzrReq "1";
BA_ "Description" SG_ 1177 PSM_DrvStImsBzrReq "IMS 부져음을 클러스터 스피커에서 출력하기 위한 시그널";
BA_ "NetworkRequestHoldingTime" SG_ 1177 PSM_DrvStImsBzrReq 5000;
BA_ "NetworkRequest" SG_ 1177 PSM_DrvStImsBzrReq 0;
BA_ "UsrSigTimeoutValue" SG_ 1177 PSM_DrvStImsBzrReq "";
BA_ "GenSigTimeoutTime" SG_ 1177 PSM_DrvStImsBzrReq 0;
BA_ "UserSigValidity" SG_ 1177 PSM_DrvStImsBzrReq 0;
BA_ "SignalLongName" SG_ 1177 PSM_DrvStImsBzrReq "PSM_DriverSeatImsBuzzerRequest";
BA_ "GenSigSendType" SG_ 1177 PSM_DrvStImsBzrReq 0;
BA_ "Version" SG_ 1177 PSM_DrvStPosMemoryP1Req "1";
BA_ "Description" SG_ 1177 PSM_DrvStPosMemoryP1Req "-(Old)C_MEMP1CMD";
BA_ "NetworkRequestHoldingTime" SG_ 1177 PSM_DrvStPosMemoryP1Req 5000;
BA_ "NetworkRequest" SG_ 1177 PSM_DrvStPosMemoryP1Req 0;
BA_ "UsrSigTimeoutValue" SG_ 1177 PSM_DrvStPosMemoryP1Req "";
BA_ "GenSigTimeoutTime" SG_ 1177 PSM_DrvStPosMemoryP1Req 0;
BA_ "UserSigValidity" SG_ 1177 PSM_DrvStPosMemoryP1Req 0;
BA_ "SignalLongName" SG_ 1177 PSM_DrvStPosMemoryP1Req "PSM_DriverSeatPositionMemoryP1Request";
BA_ "GenSigSendType" SG_ 1177 PSM_DrvStPosMemoryP1Req 0;
BA_ "Version" SG_ 1177 PSM_DrvStPosMemoryP2Req "1";
BA_ "Description" SG_ 1177 PSM_DrvStPosMemoryP2Req "-(Old)C_MEMP2CMD";
BA_ "NetworkRequestHoldingTime" SG_ 1177 PSM_DrvStPosMemoryP2Req 5000;
BA_ "NetworkRequest" SG_ 1177 PSM_DrvStPosMemoryP2Req 0;
BA_ "UsrSigTimeoutValue" SG_ 1177 PSM_DrvStPosMemoryP2Req "";
BA_ "GenSigTimeoutTime" SG_ 1177 PSM_DrvStPosMemoryP2Req 0;
BA_ "UserSigValidity" SG_ 1177 PSM_DrvStPosMemoryP2Req 0;
BA_ "SignalLongName" SG_ 1177 PSM_DrvStPosMemoryP2Req "PSM_DriverSeatPositionMemoryP2Request";
BA_ "GenSigSendType" SG_ 1177 PSM_DrvStPosMemoryP2Req 0;
BA_ "Version" SG_ 1177 PSM_DrvStPosMemoryP3Req "1";
BA_ "Description" SG_ 1177 PSM_DrvStPosMemoryP3Req "Memory IMS3";
BA_ "NetworkRequestHoldingTime" SG_ 1177 PSM_DrvStPosMemoryP3Req 5000;
BA_ "NetworkRequest" SG_ 1177 PSM_DrvStPosMemoryP3Req 0;
BA_ "UsrSigTimeoutValue" SG_ 1177 PSM_DrvStPosMemoryP3Req "";
BA_ "GenSigTimeoutTime" SG_ 1177 PSM_DrvStPosMemoryP3Req 0;
BA_ "UserSigValidity" SG_ 1177 PSM_DrvStPosMemoryP3Req 0;
BA_ "SignalLongName" SG_ 1177 PSM_DrvStPosMemoryP3Req "PSM_DriverSeatPositionMemoryP3Request";
BA_ "GenSigSendType" SG_ 1177 PSM_DrvStPosMemoryP3Req 0;
BA_ "Version" SG_ 1177 PSM_MemorySetEnaSta "1";
BA_ "Description" SG_ 1177 PSM_MemorySetEnaSta "-(Old)C_MEMENB";
BA_ "NetworkRequestHoldingTime" SG_ 1177 PSM_MemorySetEnaSta 5000;
BA_ "NetworkRequest" SG_ 1177 PSM_MemorySetEnaSta 0;
BA_ "UsrSigTimeoutValue" SG_ 1177 PSM_MemorySetEnaSta "";
BA_ "GenSigTimeoutTime" SG_ 1177 PSM_MemorySetEnaSta 0;
BA_ "UserSigValidity" SG_ 1177 PSM_MemorySetEnaSta 0;
BA_ "SignalLongName" SG_ 1177 PSM_MemorySetEnaSta "PSM_MemorySetEnableStatus";
BA_ "GenSigSendType" SG_ 1177 PSM_MemorySetEnaSta 0;
BA_ "Version" SG_ 1177 PSM_PlyBckP1Req "1";
BA_ "NetworkRequestHoldingTime" SG_ 1177 PSM_PlyBckP1Req 5000;
BA_ "NetworkRequest" SG_ 1177 PSM_PlyBckP1Req 0;
BA_ "UsrSigTimeoutValue" SG_ 1177 PSM_PlyBckP1Req "";
BA_ "GenSigTimeoutTime" SG_ 1177 PSM_PlyBckP1Req 0;
BA_ "UserSigValidity" SG_ 1177 PSM_PlyBckP1Req 0;
BA_ "SignalLongName" SG_ 1177 PSM_PlyBckP1Req "PSM_PlayBackP1Request";
BA_ "GenSigSendType" SG_ 1177 PSM_PlyBckP1Req 0;
BA_ "Version" SG_ 1177 PSM_PlyBckP2Req "1";
BA_ "NetworkRequestHoldingTime" SG_ 1177 PSM_PlyBckP2Req 5000;
BA_ "NetworkRequest" SG_ 1177 PSM_PlyBckP2Req 0;
BA_ "UsrSigTimeoutValue" SG_ 1177 PSM_PlyBckP2Req "";
BA_ "GenSigTimeoutTime" SG_ 1177 PSM_PlyBckP2Req 0;
BA_ "UserSigValidity" SG_ 1177 PSM_PlyBckP2Req 0;
BA_ "SignalLongName" SG_ 1177 PSM_PlyBckP2Req "PSM_PlayBackP2Request";
BA_ "GenSigSendType" SG_ 1177 PSM_PlyBckP2Req 0;
BA_ "Version" SG_ 1177 PSM_PlyBckP3Req "1";
BA_ "Description" SG_ 1177 PSM_PlyBckP3Req "PLAY IMS3";
BA_ "NetworkRequestHoldingTime" SG_ 1177 PSM_PlyBckP3Req 5000;
BA_ "NetworkRequest" SG_ 1177 PSM_PlyBckP3Req 0;
BA_ "UsrSigTimeoutValue" SG_ 1177 PSM_PlyBckP3Req "";
BA_ "GenSigTimeoutTime" SG_ 1177 PSM_PlyBckP3Req 0;
BA_ "UserSigValidity" SG_ 1177 PSM_PlyBckP3Req 0;
BA_ "SignalLongName" SG_ 1177 PSM_PlyBckP3Req "PSM_PlayBackP3Request";
BA_ "GenSigSendType" SG_ 1177 PSM_PlyBckP3Req 0;
BA_ "Version" SG_ 1177 PSM_PlyBckStpReq "1";
BA_ "Description" SG_ 1177 PSM_PlyBckStpReq "This signal is used to stop during playback";
BA_ "NetworkRequestHoldingTime" SG_ 1177 PSM_PlyBckStpReq 5000;
BA_ "NetworkRequest" SG_ 1177 PSM_PlyBckStpReq 0;
BA_ "UsrSigTimeoutValue" SG_ 1177 PSM_PlyBckStpReq "";
BA_ "GenSigTimeoutTime" SG_ 1177 PSM_PlyBckStpReq 0;
BA_ "UserSigValidity" SG_ 1177 PSM_PlyBckStpReq 0;
BA_ "SignalLongName" SG_ 1177 PSM_PlyBckStpReq "PSM_PlayBackStopRequest";
BA_ "GenSigSendType" SG_ 1177 PSM_PlyBckStpReq 0;
BA_ "Version" SG_ 794 USM_MvVal "1";
BA_ "NetworkRequestHoldingTime" SG_ 794 USM_MvVal 5000;
BA_ "NetworkRequest" SG_ 794 USM_MvVal 0;
BA_ "UsrSigTimeoutValue" SG_ 794 USM_MvVal "";
BA_ "GenSigTimeoutTime" SG_ 794 USM_MvVal 2000;
BA_ "UserSigValidity" SG_ 794 USM_MvVal 0;
BA_ "SignalLongName" SG_ 794 USM_MvVal "USM_MovingValue";
BA_ "GenSigSendType" SG_ 794 USM_MvVal 0;
BA_ "Version" SG_ 926 USM_CmdWPCSta "1";
BA_ "Description" SG_ 926 USM_CmdWPCSta "USM request value of WPC";
BA_ "NetworkRequestHoldingTime" SG_ 926 USM_CmdWPCSta 5000;
BA_ "NetworkRequest" SG_ 926 USM_CmdWPCSta 0;
BA_ "UsrSigTimeoutValue" SG_ 926 USM_CmdWPCSta "";
BA_ "GenSigTimeoutTime" SG_ 926 USM_CmdWPCSta 2000;
BA_ "UserSigValidity" SG_ 926 USM_CmdWPCSta 0;
BA_ "SignalLongName" SG_ 926 USM_CmdWPCSta "USM_CommandWPCStatus";
BA_ "GenSigSendType" SG_ 926 USM_CmdWPCSta 0;
BA_ "Version" SG_ 926 WPC_PhnLftWrngSta "1";
BA_ "Description" SG_ 926 WPC_PhnLftWrngSta "Warning by WPC for User (Phone left in vehicle)";
BA_ "NetworkRequestHoldingTime" SG_ 926 WPC_PhnLftWrngSta 5000;
BA_ "NetworkRequest" SG_ 926 WPC_PhnLftWrngSta 0;
BA_ "UsrSigTimeoutValue" SG_ 926 WPC_PhnLftWrngSta "";
BA_ "GenSigTimeoutTime" SG_ 926 WPC_PhnLftWrngSta 2000;
BA_ "UserSigValidity" SG_ 926 WPC_PhnLftWrngSta 0;
BA_ "SignalLongName" SG_ 926 WPC_PhnLftWrngSta "WPC_PhoneLeftWarningStatus";
BA_ "GenSigSendType" SG_ 926 WPC_PhnLftWrngSta 0;
BA_ "Version" SG_ 938 HSWS_SysWrngSta "1";
BA_ "Description" SG_ 938 HSWS_SysWrngSta "This signal indicates normal or failure status of HSWS. 

 - HSWS : Haptic Steering Warning System";
BA_ "NetworkRequestHoldingTime" SG_ 938 HSWS_SysWrngSta 5000;
BA_ "NetworkRequest" SG_ 938 HSWS_SysWrngSta 0;
BA_ "UsrSigTimeoutValue" SG_ 938 HSWS_SysWrngSta "";
BA_ "GenSigTimeoutTime" SG_ 938 HSWS_SysWrngSta 2000;
BA_ "UserSigValidity" SG_ 938 HSWS_SysWrngSta 3;
BA_ "SignalLongName" SG_ 938 HSWS_SysWrngSta "HSWS_SystemWarningStatus";
BA_ "GenSigSendType" SG_ 938 HSWS_SysWrngSta 0;
BA_ "Version" SG_ 1159 Mirror_AsstOSMirFldSta "1";
BA_ "NetworkRequestHoldingTime" SG_ 1159 Mirror_AsstOSMirFldSta 5000;
BA_ "NetworkRequest" SG_ 1159 Mirror_AsstOSMirFldSta 0;
BA_ "UsrSigTimeoutValue" SG_ 1159 Mirror_AsstOSMirFldSta "";
BA_ "GenSigTimeoutTime" SG_ 1159 Mirror_AsstOSMirFldSta 0;
BA_ "UserSigValidity" SG_ 1159 Mirror_AsstOSMirFldSta 0;
BA_ "SignalLongName" SG_ 1159 Mirror_AsstOSMirFldSta "Mirror_AssistOutSideMirrorFoldStatus";
BA_ "GenSigSendType" SG_ 1159 Mirror_AsstOSMirFldSta 0;
BA_ "Version" SG_ 876 Mirror_AsstBsdIndDiagSta "1";
BA_ "Description" SG_ 876 Mirror_AsstBsdIndDiagSta "Diagnosis signal for BSD Indicator of assist side mirror";
BA_ "NetworkRequestHoldingTime" SG_ 876 Mirror_AsstBsdIndDiagSta 5000;
BA_ "NetworkRequest" SG_ 876 Mirror_AsstBsdIndDiagSta 0;
BA_ "UsrSigTimeoutValue" SG_ 876 Mirror_AsstBsdIndDiagSta "";
BA_ "GenSigTimeoutTime" SG_ 876 Mirror_AsstBsdIndDiagSta 2000;
BA_ "UserSigValidity" SG_ 876 Mirror_AsstBsdIndDiagSta 0;
BA_ "SignalLongName" SG_ 876 Mirror_AsstBsdIndDiagSta "Mirror_AssistBsdIndicatorDiagnosticStatus";
BA_ "GenSigSendType" SG_ 876 Mirror_AsstBsdIndDiagSta 0;
BA_ "Version" SG_ 876 Mirror_OSMirFldDis "1";
BA_ "Description" SG_ 876 Mirror_OSMirFldDis "- AVM Warning Indicator signal";
BA_ "NetworkRequestHoldingTime" SG_ 876 Mirror_OSMirFldDis 5000;
BA_ "NetworkRequest" SG_ 876 Mirror_OSMirFldDis 0;
BA_ "UsrSigTimeoutValue" SG_ 876 Mirror_OSMirFldDis "";
BA_ "GenSigTimeoutTime" SG_ 876 Mirror_OSMirFldDis 2000;
BA_ "UserSigValidity" SG_ 876 Mirror_OSMirFldDis 0;
BA_ "SignalLongName" SG_ 876 Mirror_OSMirFldDis "Mirror_OutSideMirrorFoldDisplay";
BA_ "GenSigSendType" SG_ 876 Mirror_OSMirFldDis 0;
BA_ "Version" SG_ 876 Mirror_DrvrBsdIndDiagSta "1";
BA_ "Description" SG_ 876 Mirror_DrvrBsdIndDiagSta "Diagnosis signal (BSD Indicator) 



 - DH Only";
BA_ "NetworkRequestHoldingTime" SG_ 876 Mirror_DrvrBsdIndDiagSta 5000;
BA_ "NetworkRequest" SG_ 876 Mirror_DrvrBsdIndDiagSta 0;
BA_ "UsrSigTimeoutValue" SG_ 876 Mirror_DrvrBsdIndDiagSta "";
BA_ "GenSigTimeoutTime" SG_ 876 Mirror_DrvrBsdIndDiagSta 2000;
BA_ "UserSigValidity" SG_ 876 Mirror_DrvrBsdIndDiagSta 0;
BA_ "SignalLongName" SG_ 876 Mirror_DrvrBsdIndDiagSta "Mirror_DriverBsdIndicatorDiagnosticStatus";
BA_ "GenSigSendType" SG_ 876 Mirror_DrvrBsdIndDiagSta 0;
BA_ "Version" SG_ 876 Mirror_DrvrOutDrTempSnsrVal "1";
BA_ "Description" SG_ 876 Mirror_DrvrOutDrTempSnsrVal "Outdoor Temperature";
BA_ "NetworkRequestHoldingTime" SG_ 876 Mirror_DrvrOutDrTempSnsrVal 5000;
BA_ "NetworkRequest" SG_ 876 Mirror_DrvrOutDrTempSnsrVal 0;
BA_ "UsrSigTimeoutValue" SG_ 876 Mirror_DrvrOutDrTempSnsrVal "";
BA_ "GenSigTimeoutTime" SG_ 876 Mirror_DrvrOutDrTempSnsrVal 2000;
BA_ "UserSigValidity" SG_ 876 Mirror_DrvrOutDrTempSnsrVal 0;
BA_ "SignalLongName" SG_ 876 Mirror_DrvrOutDrTempSnsrVal "Mirror_DriverOutDoorTemperatureSensorValue";
BA_ "GenSigSendType" SG_ 876 Mirror_DrvrOutDrTempSnsrVal 0;
BA_ "Version" SG_ 904 IMS_DrvrStPosLimSta "1";
BA_ "Description" SG_ 904 IMS_DrvrStPosLimSta "Signal for Limit setting";
BA_ "NetworkRequestHoldingTime" SG_ 904 IMS_DrvrStPosLimSta 5000;
BA_ "NetworkRequest" SG_ 904 IMS_DrvrStPosLimSta 0;
BA_ "UsrSigTimeoutValue" SG_ 904 IMS_DrvrStPosLimSta "";
BA_ "GenSigTimeoutTime" SG_ 904 IMS_DrvrStPosLimSta 2000;
BA_ "UserSigValidity" SG_ 904 IMS_DrvrStPosLimSta 0;
BA_ "SignalLongName" SG_ 904 IMS_DrvrStPosLimSta "IMS_DriverSeatPositionLimitStatus";
BA_ "GenSigSendType" SG_ 904 IMS_DrvrStPosLimSta 0;
VAL_ 208 ENG_AccelPdlVal 0 "Accelerator Pedal not activated/0xFE" ;
VAL_ 208 ENG_BrkSwSta 0 "Brake switch is not pressed (OFF)/0x1" ;
VAL_ 208 ENG_TransmsnTyp 0 "A/T vehicle (Step Shift A/T)/0x0A" ;
VAL_ 208 ENG_EngClntTempVal 255 "Error indicator" ;
VAL_ 208 ENG_AccActSta 0 "Auto cruise control is not active/0x1" ;
VAL_ 208 ENG_CltchOpSta 0 "Clutch is not operating/0x1" ;
VAL_ 208 ENG_EngTyp 0 "Fuel - Gasoline,  ETC - No/0x1" ;
VAL_ 208 ENG_ThrPosVal 32 "Idle (port value is learnt)/0xF5" ;
VAL_ 208 ENG_EngDsplceTyp 255 "Error indicator" ;
VAL_ 208 ENG_GlowLmpSta 0 "Lamp Off/0x1" ;
VAL_ 208 ACC_CrsMainSwLmpSta 0 "Cruise MAIN switch indication lamp turn OFF/0x1" ;
VAL_ 208 ACC_CrsSetSwLmpSta 0 "Cruise SET switch indication lamp turn OFF/0x1" ;
VAL_ 208 ENG_PreFuelCutInSta 0 "Continue to fuel cut off control/0x1" ;
VAL_ 208 ENG_EngSta 0 "Engine Stop/0x1" ;
VAL_ 208 ENG_SoakTimeErrSta 0 "No Failure detected/0x1" ;
VAL_ 208 ENG_AppAccelPdlSta 0 "Accelerator pedal not pressed/0x1" ;
VAL_ 208 ENG_BstPrsrVal 4095 "Error indicator" ;
VAL_ 208 ENG_EngOilTempVal 255 "Error indicator" ;
VAL_ 208 ENG_DpfWrngSta 0 "DPF Normal State/0x1" ;
VAL_ 208 ENG_BattWrngLmpSta 0 "Battery Warning Lamp OFF/0x1" ;
VAL_ 208 ENG_OilPrsrWrngLmpSta 0 "Oil Pressure Warning Lamp OFF/0x1" ;
VAL_ 48 DCT_AccelPdlVal 0 "Accelerator Pedal not activated/0xFE" ;
VAL_ 48 DCT_EngSpdErrSta 0 "No error/0x1" ;
VAL_ 538 BAT_SocVal 255 "Error indicator" ;
VAL_ 528 ENG_ImmoLmpSta 0 "Immobilizer lamp OFF/0x1" ;
VAL_ 528 ENG_MilSta 0 "Check Engine lamp OFF/0x1" ;
VAL_ 528 ENG_AtmsphPrsrVal 28 "Error indicator" ;
VAL_ 528 ENG_BattVoltVal 255 "Error indicator" ;
VAL_ 528 SCC_SafetyFunctSta 0 "No Safety Function operation/0x1" ;
VAL_ 528 SCC_InAirTempVal 255 "Error indicator" ;
VAL_ 528 SCR_LvlWrngLmpSta 0 "Lamp Off/0x1" ;
VAL_ 528 SCR_LvlWrngMsgDis 0 "No display/0x1" ;
VAL_ 528 SCR_SysErrMsgDis 0 "No display/0x1" ;
VAL_ 528 SCR_IndcmtExitStaDis 0 "No display/0x1" ;
VAL_ 528 SCR_UreaLvlSta 0 "urea level in % scale/0xFF" 1 "urea level in % scale/0xFF" 2 "urea level in % scale/0xFF" 3 "urea level in % scale/0xFF" 4 "urea level in % scale/0xFF" 5 "urea level in % scale/0xFF" 6 "urea level in % scale/0xFF" 7 "urea level in % scale/0xFF" 8 "urea level in % scale/0xFF" 9 "urea level in % scale/0xFF" 10 "urea level in % scale/0xFF" 11 "urea level in % scale/0xFF" 12 "urea level in % scale/0xFF" 13 "urea level in % scale/0xFF" 14 "urea level in % scale/0xFF" 15 "urea level in % scale/0xFF" 16 "urea level in % scale/0xFF" 17 "urea level in % scale/0xFF" 18 "urea level in % scale/0xFF" 19 "urea level in % scale/0xFF" 20 "urea level in % scale/0xFF" 21 "urea level in % scale/0xFF" 22 "urea level in % scale/0xFF" 23 "urea level in % scale/0xFF" 24 "urea level in % scale/0xFF" 25 "urea level in % scale/0xFF" 26 "urea level in % scale/0xFF" 27 "urea level in % scale/0xFF" 28 "urea level in % scale/0xFF" 29 "urea level in % scale/0xFF" 30 "urea level in % scale/0xFF" 31 "urea level in % scale/0xFF" 32 "urea level in % scale/0xFF" 33 "urea level in % scale/0xFF" 34 "urea level in % scale/0xFF" 35 "urea level in % scale/0xFF" 36 "urea level in % scale/0xFF" 37 "urea level in % scale/0xFF" 38 "urea level in % scale/0xFF" 39 "urea level in % scale/0xFF" 40 "urea level in % scale/0xFF" 41 "urea level in % scale/0xFF" 42 "urea level in % scale/0xFF" 43 "urea level in % scale/0xFF" 44 "urea level in % scale/0xFF" 45 "urea level in % scale/0xFF" 46 "urea level in % scale/0xFF" 47 "urea level in % scale/0xFF" 48 "urea level in % scale/0xFF" 49 "urea level in % scale/0xFF" 50 "urea level in % scale/0xFF" 51 "urea level in % scale/0xFF" 52 "urea level in % scale/0xFF" 53 "urea level in % scale/0xFF" 54 "urea level in % scale/0xFF" 55 "urea level in % scale/0xFF" 56 "urea level in % scale/0xFF" 57 "urea level in % scale/0xFF" 58 "urea level in % scale/0xFF" 59 "urea level in % scale/0xFF" 60 "urea level in % scale/0xFF" 61 "urea level in % scale/0xFF" 62 "urea level in % scale/0xFF" 63 "urea level in % scale/0xFF" 64 "urea level in % scale/0xFF" 65 "urea level in % scale/0xFF" 66 "urea level in % scale/0xFF" 67 "urea level in % scale/0xFF" 68 "urea level in % scale/0xFF" 69 "urea level in % scale/0xFF" 70 "urea level in % scale/0xFF" 71 "urea level in % scale/0xFF" 72 "urea level in % scale/0xFF" 73 "urea level in % scale/0xFF" 74 "urea level in % scale/0xFF" 75 "urea level in % scale/0xFF" 76 "urea level in % scale/0xFF" 77 "urea level in % scale/0xFF" 78 "urea level in % scale/0xFF" 79 "urea level in % scale/0xFF" 80 "urea level in % scale/0xFF" 81 "urea level in % scale/0xFF" 82 "urea level in % scale/0xFF" 83 "urea level in % scale/0xFF" 84 "urea level in % scale/0xFF" 85 "urea level in % scale/0xFF" 86 "urea level in % scale/0xFF" 87 "urea level in % scale/0xFF" 88 "urea level in % scale/0xFF" 89 "urea level in % scale/0xFF" 90 "urea level in % scale/0xFF" 91 "urea level in % scale/0xFF" 92 "urea level in % scale/0xFF" 93 "urea level in % scale/0xFF" 94 "urea level in % scale/0xFF" 95 "urea level in % scale/0xFF" 96 "urea level in % scale/0xFF" 97 "urea level in % scale/0xFF" 98 "urea level in % scale/0xFF" 99 "urea level in % scale/0xFF" 100 "urea level in % scale/0xFF" 101 "urea level in % scale/0xFF" 102 "urea level in % scale/0xFF" 103 "urea level in % scale/0xFF" 104 "urea level in % scale/0xFF" 105 "urea level in % scale/0xFF" 106 "urea level in % scale/0xFF" 107 "urea level in % scale/0xFF" 108 "urea level in % scale/0xFF" 109 "urea level in % scale/0xFF" 110 "urea level in % scale/0xFF" 111 "urea level in % scale/0xFF" 112 "urea level in % scale/0xFF" 113 "urea level in % scale/0xFF" 114 "urea level in % scale/0xFF" 115 "urea level in % scale/0xFF" 116 "urea level in % scale/0xFF" 117 "urea level in % scale/0xFF" 118 "urea level in % scale/0xFF" 119 "urea level in % scale/0xFF" 120 "urea level in % scale/0xFF" 121 "urea level in % scale/0xFF" 122 "urea level in % scale/0xFF" 123 "urea level in % scale/0xFF" 124 "urea level in % scale/0xFF" 125 "urea level in % scale/0xFF" 126 "urea level in % scale/0xFF" 127 "urea level in % scale/0xFF" 128 "urea level in % scale/0xFF" 129 "urea level in % scale/0xFF" 130 "urea level in % scale/0xFF" 131 "urea level in % scale/0xFF" 132 "urea level in % scale/0xFF" 133 "urea level in % scale/0xFF" 134 "urea level in % scale/0xFF" 135 "urea level in % scale/0xFF" 136 "urea level in % scale/0xFF" 137 "urea level in % scale/0xFF" 138 "urea level in % scale/0xFF" 139 "urea level in % scale/0xFF" 140 "urea level in % scale/0xFF" 141 "urea level in % scale/0xFF" 142 "urea level in % scale/0xFF" 143 "urea level in % scale/0xFF" 144 "urea level in % scale/0xFF" 145 "urea level in % scale/0xFF" 146 "urea level in % scale/0xFF" 147 "urea level in % scale/0xFF" 148 "urea level in % scale/0xFF" 149 "urea level in % scale/0xFF" 150 "urea level in % scale/0xFF" 151 "urea level in % scale/0xFF" 152 "urea level in % scale/0xFF" 153 "urea level in % scale/0xFF" 154 "urea level in % scale/0xFF" 155 "urea level in % scale/0xFF" 156 "urea level in % scale/0xFF" 157 "urea level in % scale/0xFF" 158 "urea level in % scale/0xFF" 159 "urea level in % scale/0xFF" 160 "urea level in % scale/0xFF" 161 "urea level in % scale/0xFF" 162 "urea level in % scale/0xFF" 163 "urea level in % scale/0xFF" 164 "urea level in % scale/0xFF" 165 "urea level in % scale/0xFF" 166 "urea level in % scale/0xFF" 167 "urea level in % scale/0xFF" 168 "urea level in % scale/0xFF" 169 "urea level in % scale/0xFF" 170 "urea level in % scale/0xFF" 171 "urea level in % scale/0xFF" 172 "urea level in % scale/0xFF" 173 "urea level in % scale/0xFF" 174 "urea level in % scale/0xFF" 175 "urea level in % scale/0xFF" 176 "urea level in % scale/0xFF" 177 "urea level in % scale/0xFF" 178 "urea level in % scale/0xFF" 179 "urea level in % scale/0xFF" 180 "urea level in % scale/0xFF" 181 "urea level in % scale/0xFF" 182 "urea level in % scale/0xFF" 183 "urea level in % scale/0xFF" 184 "urea level in % scale/0xFF" 185 "urea level in % scale/0xFF" 186 "urea level in % scale/0xFF" 187 "urea level in % scale/0xFF" 188 "urea level in % scale/0xFF" 189 "urea level in % scale/0xFF" 190 "urea level in % scale/0xFF" 191 "urea level in % scale/0xFF" 192 "urea level in % scale/0xFF" 193 "urea level in % scale/0xFF" 194 "urea level in % scale/0xFF" 195 "urea level in % scale/0xFF" 196 "urea level in % scale/0xFF" 197 "urea level in % scale/0xFF" 198 "urea level in % scale/0xFF" 199 "urea level in % scale/0xFF" 200 "urea level in % scale/0xFF" ;
VAL_ 528 SCR_RmnRstrtDis 0 "No display/0x01~0xFE" ;
VAL_ 528 SCR_RmnDstDis 0 "No display/0x0001~0x61A8" ;
VAL_ 64 TCU_GearSlctDis 0 "P" 1 "L" 2 "2" 3 "3" 4 "DS Mode" 5 "D" 6 "N" 7 "R" 8 "sports mode / manual shift / paddle shift" 9 "Not Display at Cluster" 10 "Sub-Rom Communication" 11 "Sub-Rom Communication Error" 12 "Paddle shift (D-position)" 13 "Reserved" 14 "Intermediate Position" 15 "fault" ;
VAL_ 64 TCU_TqRdctnPcVal 0 "Max. reduction" 255 "No reduction" ;
VAL_ 64 TCU_GearStepTyp 3 "3 - Speed A/T or DCT" 4 "4 - Speed A/T or DCT" 5 "5 - Speed A/T or DCT" 6 "6 - Speed A/T or DCT" ;
VAL_ 64 TCU_GearShftSta 0 "no gear change" 1 "gear change is active" 2 "Not used" 3 "Error Indicator" ;
VAL_ 64 TCU_TqCnvrtrSta 0 "No lock up control" 1 "Slip lock up" 2 "Fully lock up" 3 "Off slip lock up" ;
VAL_ 64 TCU_CurrGearSta 0 "if N or P are detected (no frictional connection)" 1 "1st speed" 2 "2nd speed" 3 "3rd speed" 4 "4th speed" 5 "5th speed" 6 "6th speed" 7 "7th speed" 8 "8th speed" 14 "Reverse speed" ;
VAL_ 64 TCU_TrgtGearSta 0 "if N or P are detected (no frictional connection)" 1 "1st speed" 2 "2nd speed" 3 "3rd speed" 4 "4th speed" 5 "5th speed" 6 "6th speed" 7 "7th speed" 8 "8th speed" 14 "Reverse speed" ;
VAL_ 64 TCU_CluTrgtGearSta 0 "if N or P are detected (no frictional connection)" 1 "1st speed" 2 "2nd speed" 3 "3rd speed" 4 "4th speed" 5 "5th speed" 6 "6th speed" 7 "7th speed" 8 "8th speed" 14 "Reverse speed" ;
VAL_ 64 TCH_EngTrgtGearSta 0 "if N or P are detected (no frictional connection)" 1 "1st speed" 2 "2nd speed" 3 "3rd speed" 4 "4th speed" 5 "5th speed" 6 "6th speed" 7 "7th speed" 8 "8th speed" 14 "Reverse speed" ;
VAL_ 64 TCU_VehSpdKphVal 255 "Error Indicator" ;
VAL_ 64 TCU_DcmlVehSpdKphVal 0 "Error Indicator" ;
VAL_ 64 TCU_EngRpmDis 65535 "Error Indicator" ;
VAL_ 64 TCU_GearLmpBlnkngReq 0 "No blink" 1 "Request lamp blinking" 2 "Not used" 3 "Error Indicator" ;
VAL_ 64 TCU_FuelCutInhbtReq 0 "No request" 1 "Fuel cut inhibition request from TCU" 2 "Not used" 3 "Error Indicator" ;
VAL_ 64 TCU_SprtyIndxSta 0 "Invalid" 1 "Step 1" 2 "Step 2" 3 "Step 3" 4 "Step 4" 5 "Step 5" 6 "Step 6" 7 "Step 7" 8 "Step 8" 9 "Step 9" 10 "Step 10" 11 "Step 11" 12 "Step 12" 13 "Step 13" 14 "Step 14" 15 "Step 15" 16 "Step 16" 17 "Step 17" 18 "Step 18" 19 "Step 19" 20 "Step 20" 21 "Step 21" 22 "Step 22" 23 "Step 23" 24 "Step 24" 25 "Step 25" 26 "Invalid" 27 "Invalid" 28 "Invalid" 29 "Invalid" 30 "Invalid" 31 "Invalid" ;
VAL_ 64 TCU_DrvngModDis 0 "Inactive" 1 "Normal" 2 "Eco" 3 "Eco+" 4 "Sport" 5 "Sport+" 6 "Snow" 7 "Reserved" ;
VAL_ 64 TCU_SmrtShftSta 0 "Smart Shift not Applied" 1 "Smart Shift Applied" 2 "Not used" 3 "Error Indicator" ;
VAL_ 64 TCU_NetrlCtrlSta 0 "No NC" 1 "NC Entry" 2 "NC Applied" 3 "NC Exit" ;
VAL_ 64 TCU_ShftPtrnSta 0 "Normal (ECO)" 1 "Uphill 1 (Optional)" 2 "Uphill 2 (Optional)" 3 "Reserved" 4 "Downhill 1 (Optional)" 5 "Cruise (Optional)" 6 "Cruise_Uphill 1 (Optional)" 7 "Cruise_Uphill 2 (Optional)" 8 "Active ECO (Optional)" 9 "Sport Drive (Optional)" 15 "None of the above" ;
VAL_ 64 TCU_VgisInhbtReq 0 "There’s no request from TCU" 1 "TCU inhibits ECU from changing VGIS status" 2 "Not used" 3 "Error Indicator" ;
VAL_ 106 TCU_AtTempCVal 255 "Error Indicator" ;
VAL_ 106 TCU_TqCnvrtrSpdVal 255 "Error Indicator" ;
VAL_ 106 TCU_ActvEcoRdySta 0 "Not Ready" 1 "Ready" 2 "Not used" 3 "Error Indicator" ;
VAL_ 624 TCU_WrngMsgSta 0 "No Warning message" 1 "Warning message 1" 2 "Warning message 2" 3 "Warning message 3" 4 "Warning message 4" ;
VAL_ 261 CCU_SrvLmpReq 0 "Off" 1 "Service Lamp On" 2 "Not used" 3 "Error Indicator" ;
VAL_ 768 CCU_OutTempCDis 0 "Blank Display" 1 "Blank Display" 254 "Sensor Fail ( - - Display )" 255 "Invalid" ;
VAL_ 768 CCU_OutTempDis 255 "Error" ;
VAL_ 768 CCU_OutTempSnsrVal 255 "Error" ;
VAL_ 768 CCU_TempDispUnitSta 0 "Centigrade(℃)" 1 "Fahrenheit(℉)" 2 "Not used" 3 "Error Indicator" ;
VAL_ 442 ACU_SysWrngLmpDis 0 "Warning Lamp off" 1 "Warning Lamp on" 2 "Warning Lamp flash" 3 "Reserved" 4 "Reserved" 5 "Reserved" 6 "Not used" 7 "Error Indicator" ;
VAL_ 442 ACU_TlltlLmpDis 0 "Telltale Lamp off" 1 "Telltale Lamp on" 2 "Telltale Lamp flash" 3 "Reserved" 4 "Reserved" 5 "Reserved" 6 "Not used" 7 "Error Indicator" ;
VAL_ 442 ACU_SdArbgExtTyp 0 "Side(or Side/Curtain) Airbag doesn't exist." 1 "Side(or Side/Curtain) Airbag exists." 2 "ACU EOL Programming Mode" 3 "Reserved" 4 "Reserved" 5 "Reserved" 6 "Not used" 7 "Error Indicator" ;
VAL_ 1050 ODS_OccClassSta 255 "Error Indicator" ;
VAL_ 810 BCM_WrngBzrSta 0 "Off" 1 "SeatBelt Warning" 2 "Key Operated Warning" 3 "Parking Brake Warning" 4 "Sun Roof Open Warning" 5 "Key Learning Sound(NoSMKOption" 6 "ICE Warning" 7 "Rear Fog Warning" ;
VAL_ 1168 BCM_RmtKeyReq 0 "None" 1 "Lock" 2 "Unlock" 3 "Panic" 4 "Panic Stop" 5 "Trunk(Or Tail Gate)" 6 "Reserve" 7 "Reserve" ;
VAL_ 864 BAlarm_BglrAlrmSta 0 "DIS-,PRE-,AUTOLOCKTIMER1,2,3(TG)" 1 "ARM,-WAIT,RE-,ALARM,-HD(Trunk)" 2 "Not Used" 3 "Error Indicator" ;
VAL_ 864 BCM_AccInSta 0 "Acc Off" 1 "Acc On" 2 "Not Used" 3 "Error Indicator" ;
VAL_ 864 BCM_CntryConfgTyp 0 "Dom" 1 "Na" 2 "Eu" 3 "Aus" 4 "China" 5 "Gen,Mes" 6 "India" ;
VAL_ 864 BCM_DrvOptTyp 0 "Lhd" 1 "Rhd" 2 "Not Used" 3 "Error Indicator" ;
VAL_ 864 BCM_Ign1Sta 0 "IGN1 Off" 1 "IGN1 On" 2 "Not Used" 3 "Error Indicator" ;
VAL_ 864 BCM_Ign2Sta 0 "IGN2 Off" 1 "IGN2 On" 2 "Not Used" 3 "Error Indicator" ;
VAL_ 864 BCM_KeyOnSta 0 "KeyOff" 1 "KeyIn" 2 "Acc" 3 "Ign" 4 "St" ;
VAL_ 864 BCM_MtGearPosRSta 0 "Off" 1 "On" 2 "Not Used" 3 "Error Indicator" ;
VAL_ 864 BCM_SmkOptTyp 0 "Non SMK Option" 1 "SMK Option" 2 "Not Used" 3 "Error Indicator" ;
VAL_ 864 BCM_WrngSta 0 "Off" 1 "Power off request warning" 2 "Shift P request Warning" 3 "Reserved" ;
VAL_ 864 HeatedSteerWheel_AutoOffSta 0 "Manual Off or Fail Off or On of Default Value" 1 "Automatically Off by Timer" 2 "Not Used" 3 "Error Indicator" ;
VAL_ 864 PHEV_FastChrgDrSwSta 0 "Close" 1 "Open" 2 "Not Used" 3 "Error Indicator" ;
VAL_ 864 PHEV_StndChrgDrOpnSwReq 0 "Close" 1 "Open" 2 "Not Used" 3 "Error Indicator" ;
VAL_ 864 PHEV_RrChrgDrSwSta 0 "Close" 1 "Open" 2 "Not Used" 3 "Error Indicator" ;
VAL_ 864 Warn_SunRoofOpnSta 0 "Close" 1 "Open" 2 "Not Used" 3 "Error Indicator" ;
VAL_ 864 Wiper_RainSnsrOptionTyp 0 "Non Rain Sensor Option" 1 "Rain Sensor Option" 2 "Not Used" 3 "Error Indicator" ;
VAL_ 864 Wiper_RainSnsrSta 0 "OFF" 1 "Rain Detected" 2 "Low" 3 "High" 4 "Fault 1" 5 "Fault 2" 6 "Fault 3" 7 "Reserved" ;
VAL_ 864 PHEV_FuelDrDis 0 "Off" 1 "Fuel Door Open Wait" 2 "Refueling Ready(Fuel Door Open)" 3 "Check Fuel Door" 4 "Charging" 5 "Fuel Door Not Open" 6 "Reserved" 7 "Reserved" ;
VAL_ 864 Wiper_RrWiperSwSta 0 "Rear Wiper Sw Off" 1 "Raer Wiper Low Sw On" 2 "Rear Wiper High Sw On" 3 "Reserved" ;
VAL_ 864 Wiper_SwSta 0 "Wiper Sw Off" 1 "Wiper Int or Auto Sw On (Refer to C_RainSnsOption)" 2 "Wiper Low Sw On" 3 "Wiper High Sw On" ;
VAL_ 869 Lamp_AvTailLmpSta 0 "Off" 1 "On" 2 "Not Used" 3 "Error Indicator" ;
VAL_ 869 Lamp_AutoLtSnsrNightSta 0 "Off" 1 "Night" 2 "Not Used" 3 "Error Indicator" ;
VAL_ 869 Lamp_AutoLtSwReq 0 "Off" 1 "On" 2 "Not Used" 3 "Error Indicator" ;
VAL_ 869 Lamp_ExtrnlTailLmpOnReq 0 "Off" 1 "On" 2 "Not Used" 3 "Error Indicator" ;
VAL_ 869 Lamp_HbaCtrlModTyp 0 "H/Lamp High control Mode by BCM" 1 "H/Lamp High control Mode by HBA" 2 "Not Used" 3 "Error Indicator" ;
VAL_ 869 Lamp_HdLmpHiOnReq 0 "Off" 1 "On" 2 "Not Used" 3 "Error Indicator" ;
VAL_ 869 Lamp_HdLmpLoOnReq 0 "Off" 1 "On" 2 "Not Used" 3 "Error Indicator" ;
VAL_ 869 Lamp_IntTailLmpOnReq 0 "Off" 1 "On" 2 "Not Used" 3 "Error Indicator" ;
VAL_ 869 Lamp_PassingLmpOnReq 0 "Off" 1 "On" 2 "Not Used" 3 "Error Indicator" ;
VAL_ 869 Lamp_UsaDrlSwSta 0 "Off" 1 "On" 2 "Not Used" 3 "Error Indicator" ;
VAL_ 906 USM_ArmBzrSta 0 "Default Value" 1 "Arm Disarm Buzzer Off" 2 "Arm Disarm Buzzer On" 3 "Invalid" ;
VAL_ 906 USM_AutoDrLkReq 0 "Default" 1 "Off" 2 "Vehicle Speed On(15km)" 3 "Shift Lever On" 4 "Invalid" ;
VAL_ 906 USM_AutoDrUnLkReq 0 "Default" 1 "Off" 2 "Key Out On (AllDoors)" 3 "Shift Lever On (AllDoors)" 4 "Override" 5 "Invalid" 6 "Key Out On (Driver Door)" 7 "Shift Lever On (Driver Door)" ;
VAL_ 906 USM_EscrtHdLmpSta 0 "Default Value" 1 "Escort Off" 2 "Escort On" 3 "Invalid" ;
VAL_ 906 USM_LkSndOptSta 0 "Default" 1 "Disable" 2 "Enable" 3 "Invalid" ;
VAL_ 906 USM_TwoTrnUnLkCurrentSta 0 "Default" 1 "Ttunlock Off" 2 "Ttunlock On" 3 "Invalid" ;
VAL_ 906 Mirror_FldReq 0 "Default" 1 "Fold(Away)" 2 "Unfold(Access)" ;
VAL_ 906 PAS_DstLvlSta 0 "Short Distance" 1 "Long Distance" 2 "Not Used" 3 "Error Indicator" ;
VAL_ 906 PAS_FrCtrWrngLvlDis 0 "Off" 1 "1st warning" 2 "2nd warning" 3 "3rd warning" 4 "Error" ;
VAL_ 906 PAS_FrLftWrngLvlDis 0 "Off" 1 "1st warning" 2 "2nd warning" 3 "3rd warning" 4 "Error" ;
VAL_ 906 PAS_FrRtWrngLvlDis 0 "Off" 1 "1st warning" 2 "2nd warning" 3 "3rd warning" 4 "Error" ;
VAL_ 906 PAS_FrSnsrWrngLvlSta 0 "Off" 1 "1st Waring" 2 "2nd Waring" 3 "3rd Warning" 4 "Reserved" ;
VAL_ 906 PAS_OptTyp 0 "Non" 1 "RPAS" 2 "PAS" 3 "reserved" ;
VAL_ 906 PAS_RrCtrWrngLvlDis 0 "Off" 1 "1st warning" 2 "2nd warning" 3 "3rd warning" 4 "Error" ;
VAL_ 906 PAS_RrLftWrngLvlDis 0 "Off" 1 "1st warning" 2 "2nd warning" 3 "3rd warning" 4 "Error" ;
VAL_ 906 PAS_RrRtWrngLvlDis 0 "Off" 1 "1st warning" 2 "2nd warning" 3 "3rd warning" 4 "Error" ;
VAL_ 906 PAS_RrSnsrWrngLvlSta 0 "Off" 1 "1st Waring" 2 "2nd Waring" 3 "3rd Warning" 4 "Reserved" ;
VAL_ 906 PAS_SysChkSndSta 0 "Off" 1 "R_Confirm" 2 "Error" 3 "Reserved" ;
VAL_ 906 PAS_SysOnSta 0 "Off" 1 "On" 2 "Reserved" ;
VAL_ 906 SBR_AsstStBltWrngIndSta 0 "Off" 1 "Blinking" 2 "On" ;
VAL_ 906 SBR_DrvStBltIndSta 0 "Off" 1 "Blink" 2 "On" ;
VAL_ 906 SBR_RrCtrStBltIndSta 0 "Off" 1 "Blinking" 2 "On" ;
VAL_ 906 SBR_RrLftStBltWrngIndSta 0 "Off" 1 "Blinking" 2 "On" ;
VAL_ 906 SBR_RrRtStBltWrngIndSta 0 "Off" 1 "Blinking" 2 "On" ;
VAL_ 906 SBR_StBltWrngBzrSta 0 "Off" 1 "On" 2 "Not Used" 3 "Error Indicator" ;
VAL_ 906 USM_WrngSndLvlSta 0 "Default" 1 "Level 1" 2 "Level 2" 3 "Level 3" 4 "Reserved" 5 "Reserved" 6 "Reserved" 7 "Invalid (Error Value)" ;
VAL_ 906 Wiper_PrkngPosSta 0 "else" 1 "Parking Position" 2 "Not Used" 3 "Error Indicator" ;
VAL_ 21 DoorLock_PsvDrUnLkReq 0 "None" 1 "UnLock" 2 "Unlock only DRV Door" 3 "PIC_Key_Reminder" ;
VAL_ 21 SMK_RmtKeyReq 0 "None" 1 "Lock" 2 "Unlock" 3 "Trunk(or Tail Gate)" 4 "Panic" 5 "Panic Stop" 6 "Two Step Unlock Warning" ;
VAL_ 837 SMK_CltchIgnLkSwSta 0 "Clutch Ign SW Off" 1 "Clutch Ign SW On(Step on the clutch)" 2 "Not Used" 3 "Error Indicator" ;
VAL_ 837 SMK_DeActvWrngSta 0 "Off" 1 "On" 2 "Not Used" 3 "Error Indicator" ;
VAL_ 837 USM_HfreeOperModSta 0 "Default Value" 1 "HandsFree Off" 2 "HandsFree On" 3 "Reserved" 4 "Invalid" ;
VAL_ 837 USM_WlcmLtSta 0 "Default Value" 1 "Welcome Light Off" 2 "Welcome Light On" 3 "Invalid" ;
VAL_ 848 SMK_StrtStpBtnWrngSta 0 "Off" 1 "On" 2 "Not Used" 3 "Error Indicator" ;
VAL_ 858 Warn_DisWrngSta 0 "Off" 1 "Shift_P_Warning" 2 "Key_Bat_Discharge_Warning" 3 "Not_Unlocked_Warning" 4 "AC_Plug_Connected_Warning" 5 "Escl_Ecu_Fail_Warning" 6 "Engine_Start_Operation_IND" 7 "Auth_Fail_Warning" 8 "Key_Removal_IND" 9 "SMK_Lamp_Warning" 10 "SSB_Warning" 11 "Auth_Fail_Warning2" 12 "Vehicle_Not_P_Warning" 13 "Stop Lamp Fuse Fail Warning" 14 "Not P_N Warning" ;
VAL_ 858 Warn_IdOutWrngSta 0 "Off" 1 "On" 2 "Not Used" 3 "Error Indicator" ;
VAL_ 858 Warn_KeyBattLoWrngSta 0 "Off" 1 "On" 2 "Not Used" 3 "Error Indicator" ;
VAL_ 858 Warn_NotGearPosPWrngSta 0 "Off" 1 "On" 2 "Not Used" 3 "Error Indicator" ;
VAL_ 858 Warn_EsclFlWrngSta 0 "Off" 1 "On" 2 "Not Used" 3 "Error Indicator" ;
VAL_ 858 Warn_EsclNotLkWrngSta 0 "Off" 1 "On" 2 "Not Used" 3 "Error Indicator" ;
VAL_ 858 Warn_EsclNotUnLkWrngSta 0 "Off" 1 "On" 2 "Not Used" 3 "Error Indicator" ;
VAL_ 858 Warn_ImmoLmpOnReq 0 "Off" 1 "On" 2 "Not Used" 3 "Error Indicator" ;
VAL_ 800 TPMS_FLPosWrngLmpSta 0 "FL POSITION Warning lamp OFF" 1 "FL POSITION Warning lamp ON" 2 "Not used" 3 "Error Indicator" ;
VAL_ 800 TPMS_FRPosWrngLmpSta 0 "FR POSITION Warning lamp OFF" 1 "FR POSITION Warning lamp ON" 2 "Not used" 3 "Error Indicator" ;
VAL_ 800 TPMS_RLPosWrngLmpSta 0 "RL POSITION Warning lamp OFF" 1 "RL POSITION Warning lamp ON" 2 "Not used" 3 "Error Indicator" ;
VAL_ 800 TPMS_RRPosWrngLmpSta 0 "RR POSITION Warning lamp OFF" 1 "RR POSITION Warning lamp ON" 2 "Not used" 3 "Error Indicator" ;
VAL_ 800 TPMS_FLTirePrsrVal 255 "Error" ;
VAL_ 800 TPMS_FRTirePrsrVal 255 "Error" ;
VAL_ 800 TPMS_RLTirePrsrVal 255 "Error" ;
VAL_ 800 TPMS_RRTirePrsrVal 255 "Error" ;
VAL_ 800 TPMS_SnsrSta 0 "inactive" 1 "active" 2 "reserved" 3 "reserved" 4 "reserved" 5 "reserved" 6 "reserved" 7 "reserved" ;
VAL_ 800 TPMS_WrngLmpSta 0 "TPMS Malfunction Warning lamp OFF" 1 "TPMS Malfunction Warning lamp ON" 2 "TPMS Malfunction Warning lamp BLINKING(2Hz)" 3 "Error Indicator" ;
VAL_ 800 TPMS_TreadWrngLmpSta 0 "TREAD Warning lamp OFF" 1 "TREAD Warning lamp ON" 2 "TREAD Warning lamp BLINKING(2Hz)" 3 "Error Indicator" ;
VAL_ 800 TPMS_PrsrUnitSta 0 "psi" 1 "kpa" 2 "bar" 3 "Error Indicator" ;
VAL_ 688 AFLS_Sta 0 "AFLS is in normal condition" 1 "AFLS Off" 2 "Sensor not Calibrated or Parameter not written(경고등 점멸)" 3 "AFLS is defective" ;
VAL_ 688 AFLS_TrfChgSta 0 "Nomal Mode" 1 "Traffic Change Mode" 2 "Not Used" 3 "Error Indicator" ;
VAL_ 688 AFLS_TrfChgUSMSta 0 "Off (사양없음)" 1 "Normal Mode" 2 "Traffic Change Mode" 3 "Invalid" ;
VAL_ 688 AFLS_LedHLmpSta 0 "LED Headlamp is in nornal condition" 1 "FAN fail" 2 "LED Fail" 3 "Invalid" ;
VAL_ 1024 AHLS_WrnLmpDis 0 "Turn off the warning lamp" 1 "Turn on the warning lamp" 2 "The warning lamp blink(2Hz)" 3 "Error indicator" ;
VAL_ 1024 AHLS_WrnMsgDis 0 "AHLS normal operation" 1 "AHLS malfunction" 2 "AHLS fired" 3 "Error indicator" ;
VAL_ 1026 AVM_ViewSta 0 "None" 1 "AVM Off" 2 "AVM+Rear View" 3 "AVM+Front View" 4 "RearLeft+Rear View" 5 "FrontLeft+Front View" 6 "RearRight+Rear View" 7 "FrontRight+Front View" 8 "Rear Wide View" 9 "Front Wide View" 10 "Manual Calibration Initial View" 11 "Front Camera Calibration View" 12 "Rear Camera Calibration View" 13 "Left Camera Calibration View" 14 "Right Camera Calibration View" 15 "Direct AVM Video Out View" 16 "Parking Assist Init View" 17 "Parking Assist Rear View" 18 "Parking Assit Front View" 19 "Front 2-Section View" 20 "Reserved" 21 "Reserved" 22 "Reserved" 23 "Reserved" 24 "Reserved" 25 "Reserved" 26 "Reserved" 27 "Reserved" 28 "Reserved" 29 "Reserved" 30 "Not used" 31 "Error Indicator" ;
VAL_ 1026 AVM_CamTyp 0 "Full Type" 1 "Half Type" 2 "reserved" 3 "reserved" 4 "reserved" 5 "reserved" 6 "Not Used" 7 "Error Indicator" ;
VAL_ 1026 AVM_FrDisBtnTyp 0 "Wide Button Type" 1 "2-Section Button Type" 2 "Reserved" 3 "Reserved" 4 "Reserved" 5 "Reserved" 6 "Reserved" 7 "Reserved" 8 "Reserved" 9 "Reserved" 10 "Reserved" 11 "Reserved" 12 "Reserved" 13 "Reserved" 14 "Not used" 15 "Error Indicator" ;
VAL_ 807 PSB_LHFlrSta 0 "No failure" 1 "Failure/Service Required" 2 "Defect, PSB warning light off" 3 "Signal not valid" ;
VAL_ 807 PSB_RHFlrSta 0 "No failure" 1 "Failure/Service Required" 2 "Defect, PSB warning light off" 3 "Signal not valid" ;
VAL_ 940 Audio_VcRecSwSta 0 "Off" 1 "Key On" 2 "Long Key On" 3 "Invalid" ;
VAL_ 940 Audio_BluetoothPhnClSwSta 0 "Off" 1 "Key On" 2 "Long Key On" 3 "Invalid" ;
VAL_ 940 Audio_ModSwSta 0 "Off" 1 "Key On" 2 "Long Key On" 3 "Invalid" ;
VAL_ 940 Audio_MutSwSta 0 "Off" 1 "Key On" 2 "Long Key On" 3 "Invalid" ;
VAL_ 940 Audio_SeakDnSwSta 0 "Off" 1 "Key On" 2 "Long Key On" 3 "Invalid" ;
VAL_ 940 Audio_SeakUpSwSta 0 "Off" 1 "Key On" 2 "Long Key On" 3 "Invalid" ;
VAL_ 940 Audio_VolDnSwSta 0 "Off" 1 "Key On" 2 "Long Key On" 3 "Invalid" ;
VAL_ 940 Audio_VolUpSwSta 0 "Off" 1 "Key On" 2 "Long Key On" 3 "Invalid" ;
VAL_ 940 Cluster_DisSwSta 0 "Off" 1 "Key On" 2 "Long Key On" 3 "Invalid" ;
VAL_ 940 Cluster_ScrlDnSwSta 0 "Idle" 1 "State1" 2 "State2" 3 "Invalid" ;
VAL_ 940 Cluster_ScrlOkSwSta 0 "Off" 1 "Key On" 2 "Long Key On" 3 "Invalid" ;
VAL_ 940 Cluster_ScrlUpSwSta 0 "Idle" 1 "State1" 2 "State2" 3 "Invalid" ;
VAL_ 940 Cluster_TrpSwSta 0 "off" 1 "Key On" 2 "Long Key On" 3 "Invalid" ;
VAL_ 940 Cruise_MainSwSta 0 "Off" 1 "On" 2 "Not Used" 3 "Error Indicator" ;
VAL_ 940 Cruise_SwSta 0 "Off" 1 "ResumeAcceleration" 2 "SetCoast" 3 "DistanceGap" 4 "Cancel" 5 "Reserved0x6" ;
VAL_ 832 Lamp_HdLmpHiSwSta 0 "Off" 1 "On" 2 "Not Used" 3 "Error Indicator" ;
VAL_ 832 Lamp_LtSwSta 0 "Light Sw Off" 1 "Tail Sw On" 2 "HeadLamp Low Sw On" 3 "AutoLight Sw On" ;
VAL_ 832 Lamp_OneTouchTrnSigLftSwSta 0 "Off" 1 "On" 2 "Not Used" 3 "Error Indicator" ;
VAL_ 832 Lamp_OneTouchTrnSigRtSwSta 0 "Off" 1 "On" 2 "Not Used" 3 "Error Indicator" ;
VAL_ 832 Lamp_PassingLmpSwSta 0 "Off" 1 "On" 2 "Not Used" 3 "Error Indicator" ;
VAL_ 832 Lamp_TrnSigLftSwSta 0 "Off" 1 "On" 2 "Not Used" 3 "Error Indicator" ;
VAL_ 832 Lamp_TrnSigRtSwSta 0 "Off" 1 "On" 2 "Not Used" 3 "Error Indicator" ;
VAL_ 842 Wiper_AutoSwSta 0 "Off" 1 "On" 2 "Not Used" 3 "Error Indicator" ;
VAL_ 842 Wiper_HiSwSta 0 "Off" 1 "On" 2 "Not Used" 3 "Error Indicator" ;
VAL_ 842 Wiper_IntSta 0 "Off" 1 "On" 2 "Not Used" 3 "Error Indicator" ;
VAL_ 842 Wiper_IntStepSta 0 "STEP1(SLOW)" 1 "STEP2" 2 "STEP3" 3 "STEP4" 4 "STEP5(FAST)" ;
VAL_ 842 Wiper_LoSwSta 0 "Off" 1 "On" 2 "Not Used" 3 "Error Indicator" ;
VAL_ 922 HWSW_SysSta 0 "Normal" 1 "System Fail" 2 "reserved" 3 "Invalid" ;
VAL_ 922 USM_CmdSta 0 "Default" 1 "Steering Off" 2 "Steering On" 3 "Invalid" ;
VAL_ 1177 HCIMS_PlyBckReq 0 "None" 1023 "Invalid" ;
VAL_ 1177 PSM_DrvStImsBzrReq 0 "Off" 1 "On" 2 "Not Used" 3 "Error Indicator" ;
VAL_ 1177 PSM_DrvStPosMemoryP1Req 0 "None" 1 "P1" 2 "Not Used" 3 "Error Indicator" ;
VAL_ 1177 PSM_DrvStPosMemoryP2Req 0 "None" 1 "P2" 2 "Not Used" 3 "Error Indicator" ;
VAL_ 1177 PSM_DrvStPosMemoryP3Req 0 "None" 1 "P3" 2 "Not Used" 3 "Error Indicator" ;
VAL_ 1177 PSM_MemorySetEnaSta 0 "Disable" 1 "Enable" 2 "Not Used" 3 "Error Indicator" ;
VAL_ 1177 PSM_PlyBckP1Req 0 "None" 1 "P1" 2 "Not Used" 3 "Error Indicator" ;
VAL_ 1177 PSM_PlyBckP2Req 0 "None" 1 "P2" 2 "Not Used" 3 "Error Indicator" ;
VAL_ 1177 PSM_PlyBckP3Req 0 "None" 1 "P3" 2 "Not Used" 3 "Error Indicator" ;
VAL_ 1177 PSM_PlyBckStpReq 0 "Off" 1 "Stop" 2 "Not Used" 3 "Error Indicator" ;
VAL_ 794 USM_MvVal 0 "Default Value" 1 "Off (Disable)" 2 "50mmOn (Enable)" 3 "75mmOn (Enable)" 4 "Reserved" 5 "Reserved" 6 "Reserved" 7 "Invalid" ;
VAL_ 926 USM_CmdWPCSta 0 "Default" 1 "Off(Disable)" 2 "On(Enable)" 3 "Invalid" ;
VAL_ 926 WPC_PhnLftWrngSta 0 "Off" 1 "Phone Left Warning" 2 "Charging" 3 "Charging complete" 4 "Reserved" 5 "Reserved" 6 "Reserved" 7 "Invalid" ;
VAL_ 938 HSWS_SysWrngSta 0 "Normal" 1 "System Fail" 2 "reserved" 3 "Invalid" ;
VAL_ 1159 Mirror_AsstOSMirFldSta 0 "Stop" 1 "Fold" 2 "Unfold" ;
VAL_ 876 Mirror_AsstBsdIndDiagSta 0 "Normal" 1 "Load short to Ground" 2 "Load Open or Short to Battery" 3 "LIN time out" 4 "Reserved" 5 "Reserved" 6 "Reserved" 7 "Reserved" ;
VAL_ 876 Mirror_OSMirFldDis 0 "Off(Unfold)" 1 "On(Fold)" 2 "Not Used" 3 "Error Indicator" ;
VAL_ 876 Mirror_DrvrBsdIndDiagSta 0 "Normal" 1 "Load short to Ground" 2 "Load Open or Short to Battery" 3 "LIN time out" 4 "Reserved" 5 "Reserved" 6 "Reserved" 7 "Reserved" ;
VAL_ 876 Mirror_DrvrOutDrTempSnsrVal 0 "Exterior Temperature" 1 "Exterior Temperature" 2 "Exterior Temperature" 3 "Exterior Temperature" 4 "Exterior Temperature" 5 "Exterior Temperature" 6 "Exterior Temperature" 7 "Exterior Temperature" 8 "Exterior Temperature" 9 "Exterior Temperature" 10 "Exterior Temperature" 11 "Exterior Temperature" 12 "Exterior Temperature" 13 "Exterior Temperature" 14 "Exterior Temperature" 15 "Exterior Temperature" 16 "Exterior Temperature" 17 "Exterior Temperature" 18 "Exterior Temperature" 19 "Exterior Temperature" 20 "Exterior Temperature" 21 "Exterior Temperature" 22 "Exterior Temperature" 23 "Exterior Temperature" 24 "Exterior Temperature" 25 "Exterior Temperature" 26 "Exterior Temperature" 27 "Exterior Temperature" 28 "Exterior Temperature" 29 "Exterior Temperature" 30 "Exterior Temperature" 31 "Exterior Temperature" 32 "Exterior Temperature" 33 "Exterior Temperature" 34 "Exterior Temperature" 35 "Exterior Temperature" 36 "Exterior Temperature" 37 "Exterior Temperature" 38 "Exterior Temperature" 39 "Exterior Temperature" 40 "Exterior Temperature" 41 "Exterior Temperature" 42 "Exterior Temperature" 43 "Exterior Temperature" 44 "Exterior Temperature" 45 "Exterior Temperature" 46 "Exterior Temperature" 47 "Exterior Temperature" 48 "Exterior Temperature" 49 "Exterior Temperature" 50 "Exterior Temperature" 51 "Exterior Temperature" 52 "Exterior Temperature" 53 "Exterior Temperature" 54 "Exterior Temperature" 55 "Exterior Temperature" 56 "Exterior Temperature" 57 "Exterior Temperature" 58 "Exterior Temperature" 59 "Exterior Temperature" 60 "Exterior Temperature" 61 "Exterior Temperature" 62 "Exterior Temperature" 63 "Exterior Temperature" 64 "Exterior Temperature" 65 "Exterior Temperature" 66 "Exterior Temperature" 67 "Exterior Temperature" 68 "Exterior Temperature" 69 "Exterior Temperature" 70 "Exterior Temperature" 71 "Exterior Temperature" 72 "Exterior Temperature" 73 "Exterior Temperature" 74 "Exterior Temperature" 75 "Exterior Temperature" 76 "Exterior Temperature" 77 "Exterior Temperature" 78 "Exterior Temperature" 79 "Exterior Temperature" 80 "Exterior Temperature" 81 "Exterior Temperature" 82 "Exterior Temperature" 83 "Exterior Temperature" 84 "Exterior Temperature" 85 "Exterior Temperature" 86 "Exterior Temperature" 87 "Exterior Temperature" 88 "Exterior Temperature" 89 "Exterior Temperature" 90 "Exterior Temperature" 91 "Exterior Temperature" 92 "Exterior Temperature" 93 "Exterior Temperature" 94 "Exterior Temperature" 95 "Exterior Temperature" 96 "Exterior Temperature" 97 "Exterior Temperature" 98 "Exterior Temperature" 99 "Exterior Temperature" 100 "Exterior Temperature" 101 "Exterior Temperature" 102 "Exterior Temperature" 103 "Exterior Temperature" 104 "Exterior Temperature" 105 "Exterior Temperature" 106 "Exterior Temperature" 107 "Exterior Temperature" 108 "Exterior Temperature" 109 "Exterior Temperature" 110 "Exterior Temperature" 111 "Exterior Temperature" 112 "Exterior Temperature" 113 "Exterior Temperature" 114 "Exterior Temperature" 115 "Exterior Temperature" 116 "Exterior Temperature" 117 "Exterior Temperature" 118 "Exterior Temperature" 119 "Exterior Temperature" 120 "Exterior Temperature" 121 "Exterior Temperature" 122 "Exterior Temperature" 123 "Exterior Temperature" 124 "Exterior Temperature" 125 "Exterior Temperature" 126 "Exterior Temperature" 127 "Exterior Temperature" 128 "Exterior Temperature" 129 "Exterior Temperature" 130 "Exterior Temperature" 131 "Exterior Temperature" 132 "Exterior Temperature" 133 "Exterior Temperature" 134 "Exterior Temperature" 135 "Exterior Temperature" 136 "Exterior Temperature" 137 "Exterior Temperature" 138 "Exterior Temperature" 139 "Exterior Temperature" 140 "Exterior Temperature" 141 "Exterior Temperature" 142 "Exterior Temperature" 143 "Exterior Temperature" 144 "Exterior Temperature" 145 "Exterior Temperature" 146 "Exterior Temperature" 147 "Exterior Temperature" 148 "Exterior Temperature" 149 "Exterior Temperature" 150 "Exterior Temperature" 151 "Exterior Temperature" 152 "Exterior Temperature" 153 "Exterior Temperature" 154 "Exterior Temperature" 155 "Exterior Temperature" 156 "Exterior Temperature" 157 "Exterior Temperature" 158 "Exterior Temperature" 159 "Exterior Temperature" 160 "Exterior Temperature" 161 "Exterior Temperature" 162 "Exterior Temperature" 163 "Exterior Temperature" 164 "Exterior Temperature" 165 "Exterior Temperature" 166 "Exterior Temperature" 167 "Exterior Temperature" 168 "Exterior Temperature" 169 "Exterior Temperature" 170 "Exterior Temperature" 171 "Exterior Temperature" 172 "Exterior Temperature" 173 "Exterior Temperature" 174 "Exterior Temperature" 175 "Exterior Temperature" 176 "Exterior Temperature" 177 "Exterior Temperature" 178 "Exterior Temperature" 179 "Exterior Temperature" 180 "Exterior Temperature" 181 "Exterior Temperature" 182 "Exterior Temperature" 183 "Exterior Temperature" 184 "Exterior Temperature" 185 "Exterior Temperature" 186 "Exterior Temperature" 187 "Exterior Temperature" 188 "Exterior Temperature" 189 "Exterior Temperature" 190 "Exterior Temperature" 191 "Exterior Temperature" 192 "Exterior Temperature" 193 "Exterior Temperature" 194 "Exterior Temperature" 195 "Exterior Temperature" 196 "Exterior Temperature" 197 "Exterior Temperature" 198 "Exterior Temperature" 199 "Exterior Temperature" 200 "Exterior Temperature" 201 "Reserved" 202 "Reserved" 203 "Reserved" 204 "Reserved" 205 "Reserved" 206 "Reserved" 207 "Reserved" 208 "Reserved" 209 "Reserved" 210 "Reserved" 211 "Reserved" 212 "Reserved" 213 "Reserved" 214 "Reserved" 215 "Reserved" 216 "Reserved" 217 "Reserved" 218 "Reserved" 219 "Reserved" 220 "Reserved" 221 "Reserved" 222 "Reserved" 223 "Reserved" 224 "Reserved" 225 "Reserved" 226 "Reserved" 227 "Reserved" 228 "Reserved" 229 "Reserved" 230 "Reserved" 231 "Reserved" 232 "Reserved" 233 "Reserved" 234 "Reserved" 235 "Reserved" 236 "Reserved" 237 "Reserved" 238 "Reserved" 239 "Reserved" 240 "Reserved" 241 "Reserved" 242 "Reserved" 243 "Reserved" 244 "Reserved" 245 "Reserved" 246 "Reserved" 247 "Reserved" 248 "Reserved" 249 "Reserved" 250 "Invalid" 251 "Reserved" 252 "Reserved" 253 "Reserved" 254 "Reserved" 255 "Sensor Fail" ;
VAL_ 904 IMS_DrvrStPosLimSta 0 "Disable" 1 "Enable" 2 "Not Used" 3 "Error Indicator" ;
